VERSION "PMZ_HSCAN"

NS_ :

BS_:

BU_: BCM_Gp BECM CCF_Server EPICD EPICD_E GWM HVAC PCM SGCM TSTR Virtual_Node

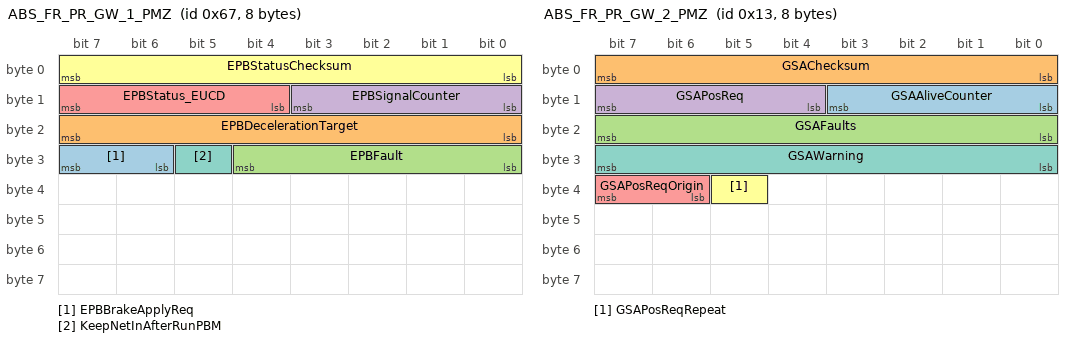
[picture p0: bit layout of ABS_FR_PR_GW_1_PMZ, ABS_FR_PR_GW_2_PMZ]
BO_ 103 ABS_FR_PR_GW_1_PMZ: 8 GWM
 SG_ EPBBrakeApplyReq : 31|2@0+ (1,0) [0|3] "" Vector__XXX
 SG_ EPBDecelerationTarget : 23|8@0+ (0.1,-11) [-11|11] "m/s/s" Vector__XXX
 SG_ EPBFault : 28|5@0+ (1,0) [0|31] "" Vector__XXX
 SG_ EPBSignalCounter : 11|4@0+ (1,0) [0|15] "Counter value" Vector__XXX
 SG_ EPBStatus_EUCD : 15|4@0+ (1,0) [0|15] "" Vector__XXX
 SG_ EPBStatusChecksum : 7|8@0+ (1,0) [0|255] "checksum" Vector__XXX
 SG_ KeepNetInAfterRunPBM : 29|1@0+ (1,0) [0|1] "" Vector__XXX

BO_ 19 ABS_FR_PR_GW_2_PMZ: 8 GWM
 SG_ GSAAliveCounter : 11|4@0+ (1,0) [0|15] "Counter value" Vector__XXX
 SG_ GSAChecksum : 7|8@0+ (1,0) [0|255] "checksum" Vector__XXX
 SG_ GSAFaults : 23|8@0+ (1,0) [0|255] "" Vector__XXX
 SG_ GSAPosReq : 15|4@0+ (1,0) [0|15] "" Vector__XXX
 SG_ GSAPosReqOrigin : 39|2@0+ (1,0) [0|3] "" Vector__XXX
 SG_ GSAPosReqRepeat : 37|1@0+ (1,0) [0|1] "" Vector__XXX
 SG_ GSAWarning : 31|8@0+ (1,0) [0|255] "" Vector__XXX

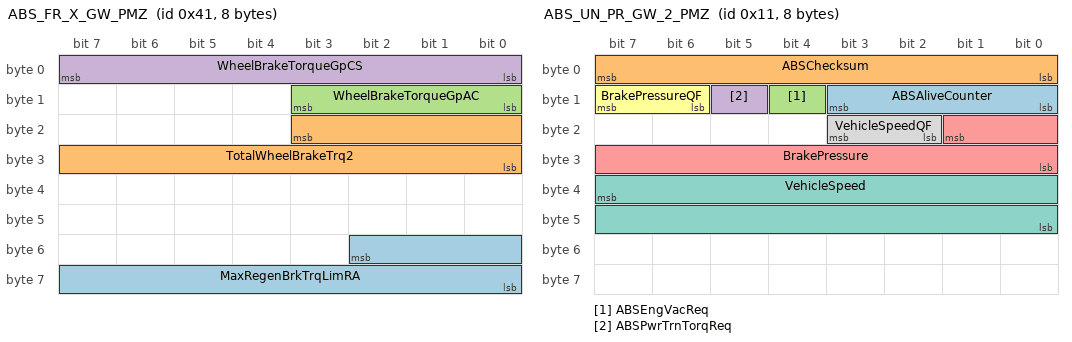
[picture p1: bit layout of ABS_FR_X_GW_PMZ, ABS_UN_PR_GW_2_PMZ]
BO_ 65 ABS_FR_X_GW_PMZ: 8 GWM
 SG_ MaxRegenBrkTrqLimRA : 50|11@0+ (10,0) [0|20470] "Nm" Vector__XXX
 SG_ TotalWheelBrakeTrq2 : 19|12@0+ (10,0) [0|40950] "Nm" Vector__XXX
 SG_ WheelBrakeTorqueGpAC : 11|4@0+ (1,0) [0|15] "Counter value" Vector__XXX
 SG_ WheelBrakeTorqueGpCS : 7|8@0+ (1,0) [0|255] "checksum" Vector__XXX

BO_ 17 ABS_UN_PR_GW_2_PMZ: 8 GWM
 SG_ ABSAliveCounter : 11|4@0+ (1,0) [0|15] "Counter value" Vector__XXX
 SG_ ABSChecksum : 7|8@0+ (1,0) [0|255] "checksum" Vector__XXX
 SG_ ABSEngVacReq : 12|1@0+ (1,0) [0|1] "" Vector__XXX
 SG_ ABSPwrTrnTorqReq : 13|1@0+ (1,0) [0|1] "" Vector__XXX
 SG_ BrakePressure : 17|10@0+ (0.2,0) [0|204.6] "Bar" Vector__XXX
 SG_ BrakePressureQF : 15|2@0+ (1,0) [0|3] "" Vector__XXX
 SG_ VehicleSpeed : 39|16@0+ (0.01,0) [0|320] "kph"  EPICD,EPICD_E
 SG_ VehicleSpeedQF : 19|2@0+ (1,0) [0|3] ""  EPICD,EPICD_E

BO_ 1537 BCM_CCP_Rx_PMZCAN: 8 GWM
 SG_ CCP_BCM_Rx : 7|64@0+ (1,0) [0|1.84467440737096E+019] ""  BCM_Gp

BO_ 1536 BCM_CCP_Tx_PMZCAN: 8 BCM_Gp
 SG_ CCP_BCM_Tx : 7|64@0+ (1,0) [0|1.84467440737096E+019] ""  GWM

BO_ 1281 BCM_NM501HS: 8 BCM_Gp
 SG_ NMmessageBCMHS : 7|64@0+ (1,0) [0|1.84467440737096E+019] ""  Virtual_Node

BO_ 417 BCM_PMZ_Core: 8 BCM_Gp
 SG_ AlarmModeHS : 42|2@0+ (1,0) [0|3] "" Vector__XXX
 SG_ AlarmModeHS_UB : 47|1@0+ (1,0) [0|1] "" Vector__XXX
 SG_ BCMReqBusAwakePT : 43|1@0+ (1,0) [0|1] ""  GWM
 SG_ CabinCleaningWakeUpReq : 27|1@0+ (1,0) [0|1] ""  HVAC
 SG_ CarModeHS : 60|4@0+ (1,0) [0|15] ""  BECM,EPICD,EPICD_E,HVAC
 SG_ CentralLockStatus : 46|3@0+ (1,0) [5|7] "Unused (Undefined)" Vector__XXX
 SG_ CentralLockStatus3 : 30|3@0+ (1,0) [5|7] "Unused (Undefined)" Vector__XXX
 SG_ CLockCmd_2 : 55|8@0+ (1,0) [0|255] "See Description for encoding" Vector__XXX
 SG_ CLockCmd_2_UB : 63|1@0+ (1,0) [0|1] "" Vector__XXX
 SG_ CLockCmd_3 : 39|8@0+ (1,0) [0|255] "See Description for encoding" Vector__XXX
 SG_ CLockCmd_3_UB : 40|1@0+ (1,0) [0|1] "" Vector__XXX
 SG_ PHEVFuelFillRequest : 62|2@0+ (1,0) [0|3] "" Vector__XXX
 SG_ PowerMode : 23|5@0+ (1,0) [0|31] ""  BECM,EPICD,EPICD_E,HVAC,SGCM
 SG_ PowerModeAliveCounter : 11|4@0+ (1,0) [0|15] "Counter value" Vector__XXX
 SG_ PowerModeChecksum : 7|8@0+ (1,0) [0|255] "checksum" Vector__XXX
 SG_ PowerModeQF : 18|2@0+ (1,0) [0|3] "" Vector__XXX
 SG_ RemoteEngStartDrivPres : 16|1@0+ (1,0) [0|1] "" Vector__XXX
 SG_ RemoteFunctionStatus : 15|4@0+ (1,0) [3|14] "Reserved" Vector__XXX
 SG_ RemoteStartStatusMS : 31|1@0+ (1,0) [0|1] "" Vector__XXX
 SG_ TimedChrgWakeUpReq : 56|1@0+ (1,0) [0|1] "" Vector__XXX

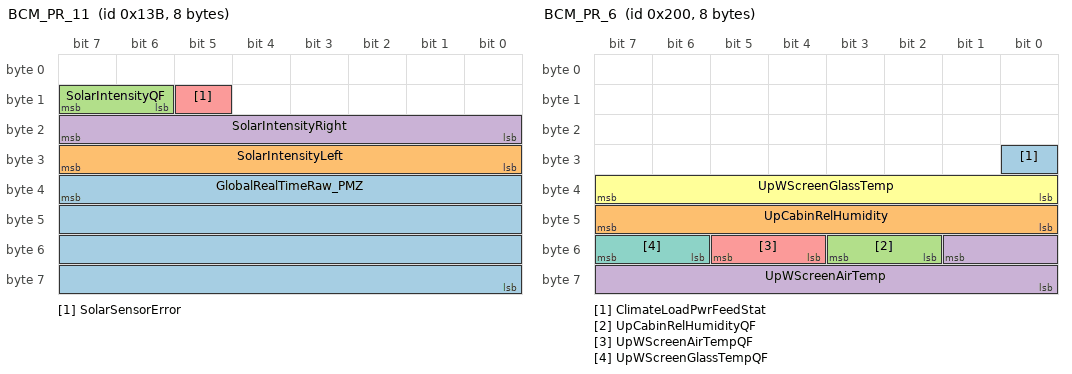
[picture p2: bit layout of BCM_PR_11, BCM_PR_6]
BO_ 315 BCM_PR_11: 8 BCM_Gp
 SG_ GlobalRealTimeRaw_PMZ : 39|32@0+ (1,0) [0|4294967295] ""  GWM,HVAC
 SG_ SolarIntensityLeft : 31|8@0+ (5,0) [0|1250] "W/m2"  GWM,HVAC
 SG_ SolarIntensityQF : 15|2@0+ (1,0) [0|3] ""  GWM,HVAC
 SG_ SolarIntensityRight : 23|8@0+ (5,0) [0|1250] "W/m2"  GWM,HVAC
 SG_ SolarSensorError : 13|1@0+ (1,0) [0|1] ""  GWM,HVAC

BO_ 512 BCM_PR_6: 8 BCM_Gp
 SG_ ClimateLoadPwrFeedStat : 24|1@0+ (1,0) [0|1] ""  HVAC
 SG_ UpCabinRelHumidity : 47|8@0+ (0.5,0) [0|127.5] "%"  HVAC
 SG_ UpCabinRelHumidityQF : 51|2@0+ (1,0) [0|3] ""  HVAC
 SG_ UpWScreenAirTemp : 49|10@0+ (0.125,-40) [-40|87.875] "DegC"  HVAC
 SG_ UpWScreenAirTempQF : 53|2@0+ (1,0) [0|3] ""  HVAC
 SG_ UpWScreenGlassTemp : 39|8@0+ (0.5,-40) [-40|87.5] "DegC"  HVAC
 SG_ UpWScreenGlassTempQF : 55|2@0+ (1,0) [0|3] ""  HVAC

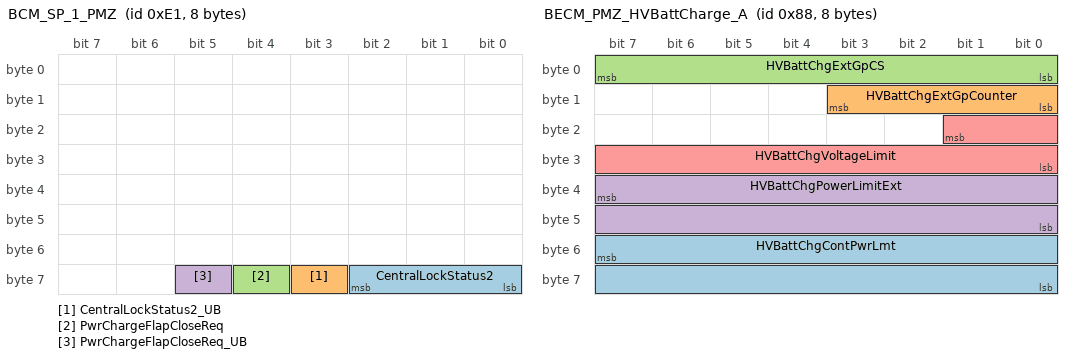
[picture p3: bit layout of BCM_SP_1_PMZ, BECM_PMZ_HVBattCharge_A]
BO_ 225 BCM_SP_1_PMZ: 8 BCM_Gp
 SG_ CentralLockStatus2 : 58|3@0+ (1,0) [5|7] "Unused (Undefined)" Vector__XXX
 SG_ CentralLockStatus2_UB : 59|1@0+ (1,0) [0|1] "" Vector__XXX
 SG_ PwrChargeFlapCloseReq : 60|1@0+ (1,0) [0|1] "" Vector__XXX
 SG_ PwrChargeFlapCloseReq_UB : 61|1@0+ (1,0) [0|1] "" Vector__XXX

BO_ 7 BCM_SP_GW_ParkLockDataControl: 8 BCM_Gp
 SG_ ParkLockDataControl : 7|64@0+ (1,0) [0|1.84467440737096E+019] ""  GWM

BO_ 1672 BCM_UUDT1_PMZCAN: 8 BCM_Gp
 SG_ UUDTBCMResponse1 : 7|64@0+ (1,0) [0|1.84467440737096E+019] ""  GWM

BO_ 1673 BCM_UUDT2_PMZCAN: 8 BCM_Gp
 SG_ UUDTBCMResponse2 : 7|64@0+ (1,0) [0|1.84467440737096E+019] ""  GWM

BO_ 1674 BCM_UUDT3_PMZCAN: 8 BCM_Gp
 SG_ UUDTBCMResponse3 : 7|64@0+ (1,0) [0|1.84467440737096E+019] ""  GWM

BO_ 1675 BCM_UUDT4_PMZCAN: 8 BCM_Gp
 SG_ UUDTBCMResponse4 : 7|64@0+ (1,0) [0|1.84467440737096E+019] ""  GWM

BO_ 1314 BECM_NM522: 8 BECM
 SG_ NMmessageBECM : 7|64@0+ (1,0) [0|1.84467440737096E+019] ""  Virtual_Node

BO_ 136 BECM_PMZ_HVBattCharge_A: 8 BECM
 SG_ HVBattChgContPwrLmt : 55|16@0+ (0.01,-655.35) [-655.35|0] "kW"  PCM
 SG_ HVBattChgExtGpCounter : 11|4@0+ (1,0) [0|15] "Counter value"  PCM
 SG_ HVBattChgExtGpCS : 7|8@0+ (1,0) [0|255] "checksum"  PCM
 SG_ HVBattChgPowerLimitExt : 39|16@0+ (0.01,-655.35) [-655.35|0] "kW"  PCM
 SG_ HVBattChgVoltageLimit : 17|10@0+ (1,0) [0|1023] "Volts"  PCM

BO_ 138 BECM_PMZ_HVBattCharge_B: 8 BECM
 SG_ HVBattChgCurrentLimit : 33|10@0+ (1,-1023) [-1023|0] "Amps"  GWM,PCM
 SG_ HVBattDerateWarning : 54|1@0+ (1,0) [0|1] ""  PCM
 SG_ HVBattTotalCapacity : 19|12@0+ (0.1,0) [0|409.5] "Kwh"  PCM

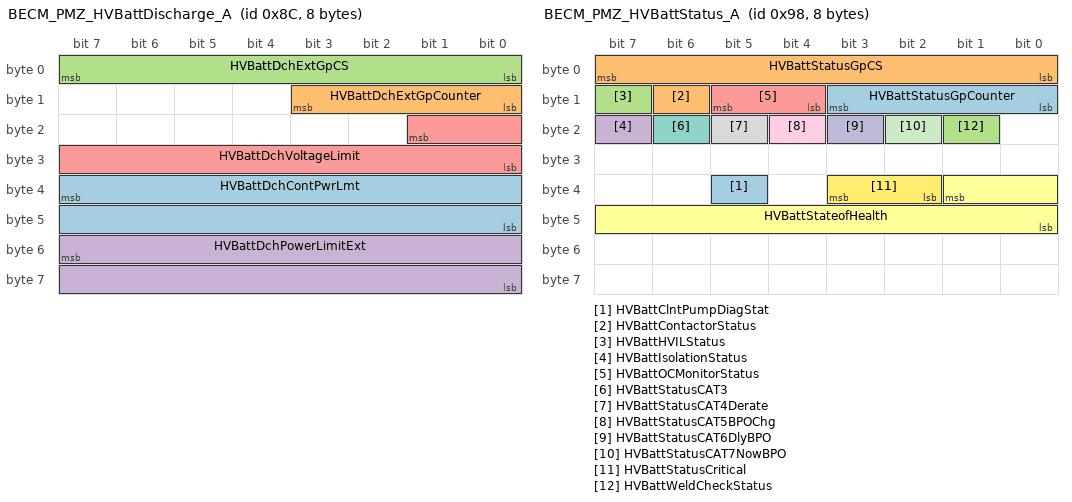
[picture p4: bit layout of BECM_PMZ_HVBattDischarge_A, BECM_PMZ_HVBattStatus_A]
BO_ 140 BECM_PMZ_HVBattDischarge_A: 8 BECM
 SG_ HVBattDchContPwrLmt : 39|16@0+ (0.01,0) [0|655.35] "kW"  PCM
 SG_ HVBattDchExtGpCounter : 11|4@0+ (1,0) [0|15] "Counter value"  PCM
 SG_ HVBattDchExtGpCS : 7|8@0+ (1,0) [0|255] "checksum"  PCM
 SG_ HVBattDchPowerLimitExt : 55|16@0+ (0.01,0) [0|655.35] "kW"  PCM
 SG_ HVBattDchVoltageLimit : 17|10@0+ (1,0) [0|1023] "Volts"  PCM

BO_ 142 BECM_PMZ_HVBattDischarge_B: 8 BECM
 SG_ HVBattDchCurrentLimit : 17|10@0+ (1,0) [0|1023] "Amps"  GWM,PCM

BO_ 144 BECM_PMZ_HVBattPower_A: 8 BECM
 SG_ HVBattMILRequest : 21|2@0+ (1,0) [0|3] ""  PCM

BO_ 519 BECM_PMZ_HVBattSOC: 8 BECM
 SG_ HVBattSOCAverage : 53|14@0+ (0.01,0) [0|100] "%"  GWM,PCM

BO_ 152 BECM_PMZ_HVBattStatus_A: 8 BECM
 SG_ HVBattClntPumpDiagStat : 37|1@0+ (1,0) [0|1] ""  HVAC
 SG_ HVBattContactorStatus : 14|1@0+ (1,0) [0|1] ""  EPICD_E,GWM,PCM
 SG_ HVBattHVILStatus : 15|1@0+ (1,0) [0|1] ""  GWM,PCM
 SG_ HVBattIsolationStatus : 23|1@0+ (1,0) [0|1] ""  PCM
 SG_ HVBattOCMonitorStatus : 13|2@0+ (1,0) [0|3] ""  GWM,PCM
 SG_ HVBattStateofHealth : 33|10@0+ (0.1,0) [0|100] "%"  GWM,PCM
 SG_ HVBattStatusCAT3 : 22|1@0+ (1,0) [0|1] ""  GWM,PCM
 SG_ HVBattStatusCAT4Derate : 21|1@0+ (1,0) [0|1] ""  GWM,PCM
 SG_ HVBattStatusCAT5BPOChg : 20|1@0+ (1,0) [0|1] ""  PCM
 SG_ HVBattStatusCAT6DlyBPO : 19|1@0+ (1,0) [0|1] ""  GWM,PCM
 SG_ HVBattStatusCAT7NowBPO : 18|1@0+ (1,0) [0|1] ""  GWM,PCM
 SG_ HVBattStatusCritical : 35|2@0+ (1,0) [0|3] ""  GWM,HVAC
 SG_ HVBattStatusGpCounter : 11|4@0+ (1,0) [0|15] "Counter value"  PCM
 SG_ HVBattStatusGpCS : 7|8@0+ (1,0) [0|255] "checksum"  PCM
 SG_ HVBattWeldCheckStatus : 17|1@0+ (1,0) [0|1] ""  PCM

BO_ 328 BECM_PMZ_HVBattTemp: 8 BECM
 SG_ HVBattCellTempAverage : 63|8@0+ (0.5,-40) [-40|87.5] "deg C"  GWM,PCM
 SG_ HVBattCellTempColdest : 55|8@0+ (0.5,-40) [-40|87.5] "deg C"  GWM,HVAC,PCM
 SG_ HVBattCellTempHottest : 47|8@0+ (0.5,-40) [-40|87.5] "deg C"  GWM,HVAC,PCM

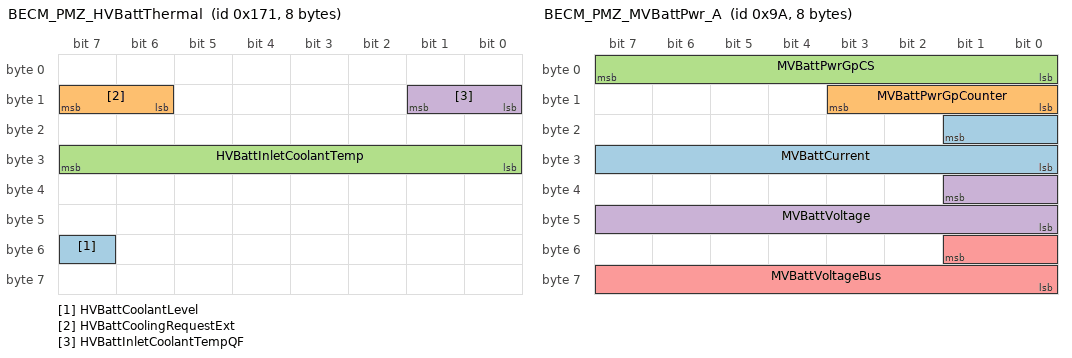
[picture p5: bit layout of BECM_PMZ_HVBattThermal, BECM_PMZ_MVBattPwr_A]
BO_ 369 BECM_PMZ_HVBattThermal: 8 BECM
 SG_ HVBattCoolantLevel : 55|1@0+ (1,0) [0|1] ""  HVAC
 SG_ HVBattCoolingRequestExt : 15|2@0+ (1,0) [0|3] ""  HVAC
 SG_ HVBattInletCoolantTemp : 31|8@0+ (0.5,-40) [-40|86.5] "DegC"  GWM,HVAC,PCM
 SG_ HVBattInletCoolantTempQF : 9|2@0+ (1,0) [0|3] ""  PCM

BO_ 332 BECM_PMZ_HVBattVoltage: 8 BECM
 SG_ HVBattCellVoltageMax : 52|13@0+ (0.001,0) [0|8.191] "Volts"  GWM
 SG_ HVBattCellVoltageMin : 36|13@0+ (0.001,0) [0|8.191] "Volts"  GWM

BO_ 334 BECM_PMZ_HVBattWakeUp: 8 BECM
 SG_ HVBattWakeUpDchReq : 54|1@0+ (1,0) [0|1] ""  BCM_Gp
 SG_ HVBattWakeUpThermalReq : 62|1@0+ (1,0) [0|1] ""  BCM_Gp
 SG_ HVBattWakeUpTopUpReq : 63|1@0+ (1,0) [0|1] ""  BCM_Gp

BO_ 744 BECM_PMZ_MVBattCal_A: 8 BECM
 SG_ MVBattCalibrationID01 : 15|56@0+ (1,0) [0|7.20575940379279E+016] ""  PCM

BO_ 745 BECM_PMZ_MVBattCal_B: 8 BECM
 SG_ MVBattCalibrationID02 : 15|56@0+ (1,0) [0|7.20575940379279E+016] ""  PCM

BO_ 746 BECM_PMZ_MVBattCal_C: 8 BECM
 SG_ MVBattCalibVerifNumber : 39|32@0+ (1,0) [0|4294967295] ""  PCM

BO_ 748 BECM_PMZ_MVBattDiag_A: 8 BECM
 SG_ MVBattDiagnostic01 : 7|64@0+ (1,0) [0|1.84467440737096E+019] ""  PCM

BO_ 749 BECM_PMZ_MVBattDiag_B: 8 BECM
 SG_ MVBattDiagnostic02 : 7|64@0+ (1,0) [0|1.84467440737096E+019] ""  PCM

BO_ 154 BECM_PMZ_MVBattPwr_A: 8 BECM
 SG_ MVBattCurrent : 17|10@0+ (1,-511) [-511|512] "Amps"  PCM
 SG_ MVBattPwrGpCounter : 11|4@0+ (1,0) [0|15] "Counter value"  PCM
 SG_ MVBattPwrGpCS : 7|8@0+ (1,0) [0|255] "checksum"  PCM
 SG_ MVBattVoltage : 33|10@0+ (0.1,0) [0|102.3] "Volts"  PCM
 SG_ MVBattVoltageBus : 49|10@0+ (0.1,0) [0|102.3] "Volts"  PCM

BO_ 249 BECM_PMZ_MVBattPwr_B: 8 BECM
 SG_ HVBattDchContCurLmt : 49|10@0+ (1,0) [0|1023] "Amps"  PCM
 SG_ MVBattTOCRModeReq : 51|2@0+ (1,0) [0|3] ""  PCM

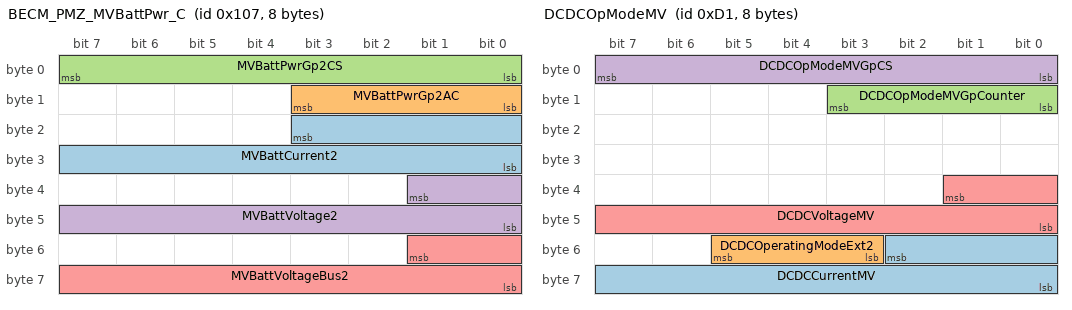
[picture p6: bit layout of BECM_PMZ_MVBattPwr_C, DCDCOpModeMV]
BO_ 263 BECM_PMZ_MVBattPwr_C: 8 BECM
 SG_ MVBattCurrent2 : 19|12@0+ (1,-2047) [-2047|2048] "Amps"  GWM,PCM
 SG_ MVBattPwrGp2AC : 11|4@0+ (1,0) [0|15] "Counter value"  GWM,PCM
 SG_ MVBattPwrGp2CS : 7|8@0+ (1,0) [0|255] "checksum"  GWM,PCM
 SG_ MVBattVoltage2 : 33|10@0+ (0.1,0) [0|102.3] "Volts"  GWM,PCM
 SG_ MVBattVoltageBus2 : 49|10@0+ (0.1,0) [0|102.3] "Volts"  GWM,PCM

BO_ 794 BMS_PR_GW_1_PMZ: 8 GWM
 SG_ BSBattSOC : 54|7@0+ (1,0) [0|100] "%" Vector__XXX
 SG_ BSBattVoltage : 63|8@0+ (0.0625,0) [0|15.9375] "V" Vector__XXX
 SG_ BSBsdEstimState : 41|2@0+ (1,0) [0|3] "" Vector__XXX

BO_ 1617 CCP_REQ_EDPM_PMZCAN: 8 GWM
 SG_ CCPTesterToEDPM : 7|64@0+ (1,0) [0|1.84467440737096E+019] "" Vector__XXX

BO_ 1604 CCP_REQ_HVAC_PMZCAN: 8 GWM
 SG_ CCPTesterToHVAC : 7|64@0+ (1,0) [0|1.84467440737096E+019] ""  HVAC

BO_ 1605 CCP_RES_HVAC_PMZCAN: 8 HVAC
 SG_ CCPHVACToTester : 7|64@0+ (1,0) [0|1.84467440737096E+019] ""  GWM

BO_ 209 DCDCOpModeMV: 8 EPICD_E
 SG_ DCDCCurrentMV : 50|11@0+ (0.1,-102.35) [-102.35|102.35] "Amps"  GWM,PCM
 SG_ DCDCOperatingModeExt2 : 53|3@0+ (1,0) [0|7] ""  GWM,PCM
 SG_ DCDCOpModeMVGpCounter : 11|4@0+ (1,0) [0|15] "Counter value"  GWM,PCM
 SG_ DCDCOpModeMVGpCS : 7|8@0+ (1,0) [0|255] "checksum"  GWM,PCM
 SG_ DCDCVoltageMV : 33|10@0+ (0.1,0) [0|102.3] "Volts"  BECM,GWM,PCM

BO_ 465 ElectricityPeakTimes1_PMZ: 8 GWM
 SG_ TimedCharge1Active : 23|1@0+ (1,0) [0|1] "" Vector__XXX
 SG_ TimedCharge1ActiveFri : 31|1@0+ (1,0) [0|1] "" Vector__XXX
 SG_ TimedCharge1ActiveMon : 39|1@0+ (1,0) [0|1] "" Vector__XXX
 SG_ TimedCharge1ActiveSat : 47|1@0+ (1,0) [0|1] "" Vector__XXX
 SG_ TimedCharge1ActiveSun : 58|1@0+ (1,0) [0|1] "" Vector__XXX
 SG_ TimedCharge1ActiveThur : 59|1@0+ (1,0) [0|1] "" Vector__XXX
 SG_ TimedCharge1ActiveTues : 60|1@0+ (1,0) [0|1] "" Vector__XXX
 SG_ TimedCharge1ActiveWed : 61|1@0+ (1,0) [0|1] "" Vector__XXX
 SG_ TimedCharge1EndTimeA : 22|7@0+ (15,0) [0|1425] "Mins" Vector__XXX
 SG_ TimedCharge1EndTimeB : 30|7@0+ (15,0) [0|1425] "Mins" Vector__XXX
 SG_ TimedCharge1EndTimeC : 38|7@0+ (15,0) [0|1425] "Mins" Vector__XXX
 SG_ TimedCharge1EndTimeD : 46|7@0+ (15,0) [0|1425] "Mins" Vector__XXX
 SG_ TimedCharge1ZoneA : 49|2@0+ (1,0) [0|3] "" Vector__XXX
 SG_ TimedCharge1ZoneB : 51|2@0+ (1,0) [0|3] "" Vector__XXX
 SG_ TimedCharge1ZoneC : 53|2@0+ (1,0) [0|3] "" Vector__XXX
 SG_ TimedCharge1ZoneD : 55|2@0+ (1,0) [0|3] "" Vector__XXX
 SG_ TimedCharge1ZoneE : 63|2@0+ (1,0) [0|3] "" Vector__XXX

BO_ 466 ElectricityPeakTimes2_PMZ: 8 GWM
 SG_ TimedCharge2Active : 23|1@0+ (1,0) [0|1] "" Vector__XXX
 SG_ TimedCharge2ActiveFri : 31|1@0+ (1,0) [0|1] "" Vector__XXX
 SG_ TimedCharge2ActiveMon : 39|1@0+ (1,0) [0|1] "" Vector__XXX
 SG_ TimedCharge2ActiveSat : 47|1@0+ (1,0) [0|1] "" Vector__XXX
 SG_ TimedCharge2ActiveSun : 61|1@0+ (1,0) [0|1] "" Vector__XXX
 SG_ TimedCharge2ActiveThur : 60|1@0+ (1,0) [0|1] "" Vector__XXX
 SG_ TimedCharge2ActiveTues : 59|1@0+ (1,0) [0|1] "" Vector__XXX
 SG_ TimedCharge2ActiveWed : 58|1@0+ (1,0) [0|1] "" Vector__XXX
 SG_ TimedCharge2EndTimeA : 22|7@0+ (15,0) [0|1425] "Mins" Vector__XXX
 SG_ TimedCharge2EndTimeB : 30|7@0+ (15,0) [0|1425] "Mins" Vector__XXX
 SG_ TimedCharge2EndTimeC : 38|7@0+ (15,0) [0|1425] "Mins" Vector__XXX
 SG_ TimedCharge2EndTimeD : 46|7@0+ (15,0) [0|1425] "Mins" Vector__XXX
 SG_ TimedCharge2ZoneA : 49|2@0+ (1,0) [0|3] "" Vector__XXX
 SG_ TimedCharge2ZoneB : 51|2@0+ (1,0) [0|3] "" Vector__XXX
 SG_ TimedCharge2ZoneC : 53|2@0+ (1,0) [0|3] "" Vector__XXX
 SG_ TimedCharge2ZoneD : 55|2@0+ (1,0) [0|3] "" Vector__XXX
 SG_ TimedCharge2ZoneE : 63|2@0+ (1,0) [0|3] "" Vector__XXX

BO_ 467 ElectricityPeakTimes3_PMZ: 8 GWM
 SG_ TimedCharge3Active : 23|1@0+ (1,0) [0|1] "" Vector__XXX
 SG_ TimedCharge3ActiveFri : 31|1@0+ (1,0) [0|1] "" Vector__XXX
 SG_ TimedCharge3ActiveMon : 39|1@0+ (1,0) [0|1] "" Vector__XXX
 SG_ TimedCharge3ActiveSat : 47|1@0+ (1,0) [0|1] "" Vector__XXX
 SG_ TimedCharge3ActiveSun : 61|1@0+ (1,0) [0|1] "" Vector__XXX
 SG_ TimedCharge3ActiveThur : 60|1@0+ (1,0) [0|1] "" Vector__XXX
 SG_ TimedCharge3ActiveTues : 59|1@0+ (1,0) [0|1] "" Vector__XXX
 SG_ TimedCharge3ActiveWed : 58|1@0+ (1,0) [0|1] "" Vector__XXX
 SG_ TimedCharge3EndTimeA : 22|7@0+ (15,0) [0|1425] "Mins" Vector__XXX
 SG_ TimedCharge3EndTimeB : 30|7@0+ (15,0) [0|1425] "Mins" Vector__XXX
 SG_ TimedCharge3EndTimeC : 38|7@0+ (15,0) [0|1425] "Mins" Vector__XXX
 SG_ TimedCharge3EndTimeD : 46|7@0+ (15,0) [0|1425] "Mins" Vector__XXX
 SG_ TimedCharge3ZoneA : 49|2@0+ (1,0) [0|3] "" Vector__XXX
 SG_ TimedCharge3ZoneB : 51|2@0+ (1,0) [0|3] "" Vector__XXX
 SG_ TimedCharge3ZoneC : 53|2@0+ (1,0) [0|3] "" Vector__XXX
 SG_ TimedCharge3ZoneD : 55|2@0+ (1,0) [0|3] "" Vector__XXX
 SG_ TimedCharge3ZoneE : 63|2@0+ (1,0) [0|3] "" Vector__XXX

BO_ 468 ElectricityPeakTimes4_PMZ: 8 GWM
 SG_ TimedCharge4Active : 23|1@0+ (1,0) [0|1] "" Vector__XXX
 SG_ TimedCharge4ActiveFri : 31|1@0+ (1,0) [0|1] "" Vector__XXX
 SG_ TimedCharge4ActiveMon : 39|1@0+ (1,0) [0|1] "" Vector__XXX
 SG_ TimedCharge4ActiveSat : 47|1@0+ (1,0) [0|1] "" Vector__XXX
 SG_ TimedCharge4ActiveSun : 61|1@0+ (1,0) [0|1] "" Vector__XXX
 SG_ TimedCharge4ActiveThur : 60|1@0+ (1,0) [0|1] "" Vector__XXX
 SG_ TimedCharge4ActiveTues : 59|1@0+ (1,0) [0|1] "" Vector__XXX
 SG_ TimedCharge4ActiveWed : 58|1@0+ (1,0) [0|1] "" Vector__XXX
 SG_ TimedCharge4EndTimeA : 22|7@0+ (15,0) [0|1425] "Mins" Vector__XXX
 SG_ TimedCharge4EndTimeB : 30|7@0+ (15,0) [0|1425] "Mins" Vector__XXX
 SG_ TimedCharge4EndTimeC : 38|7@0+ (15,0) [0|1425] "Mins" Vector__XXX
 SG_ TimedCharge4EndTimeD : 46|7@0+ (15,0) [0|1425] "Mins" Vector__XXX
 SG_ TimedCharge4ZoneA : 49|2@0+ (1,0) [0|3] "" Vector__XXX
 SG_ TimedCharge4ZoneB : 51|2@0+ (1,0) [0|3] "" Vector__XXX
 SG_ TimedCharge4ZoneC : 53|2@0+ (1,0) [0|3] "" Vector__XXX
 SG_ TimedCharge4ZoneD : 55|2@0+ (1,0) [0|3] "" Vector__XXX
 SG_ TimedCharge4ZoneE : 63|2@0+ (1,0) [0|3] "" Vector__XXX

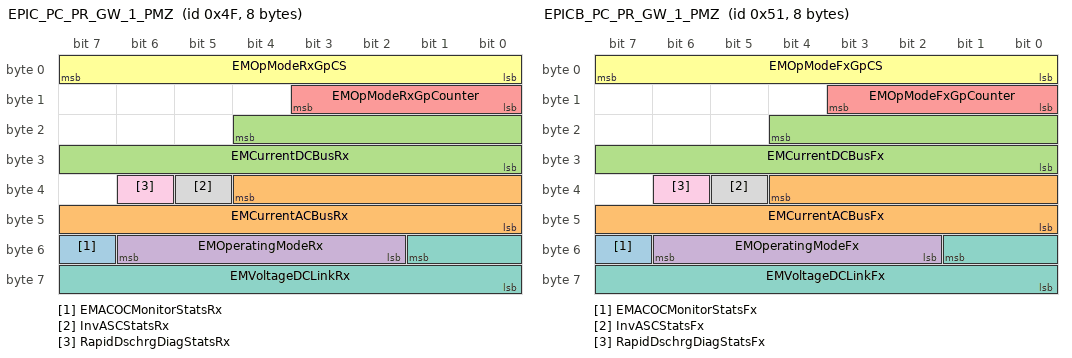
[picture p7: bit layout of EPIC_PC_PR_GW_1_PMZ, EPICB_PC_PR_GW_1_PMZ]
BO_ 79 EPIC_PC_PR_GW_1_PMZ: 8 GWM
 SG_ EMACOCMonitorStatsRx : 55|1@0+ (1,0) [0|1] "" Vector__XXX
 SG_ EMCurrentACBusRx : 36|13@0+ (0.25,-1024) [-1024|1023.75] "Amps" Vector__XXX
 SG_ EMCurrentDCBusRx : 20|13@0+ (0.25,-1024) [-1024|1023.75] "Amps" Vector__XXX
 SG_ EMOperatingModeRx : 54|5@0+ (1,0) [0|31] "" Vector__XXX
 SG_ EMOpModeRxGpCounter : 11|4@0+ (1,0) [0|15] "Counter value" Vector__XXX
 SG_ EMOpModeRxGpCS : 7|8@0+ (1,0) [0|255] "checksum" Vector__XXX
 SG_ EMVoltageDCLinkRx : 49|10@0+ (1,0) [0|1023] "Volts" Vector__XXX
 SG_ InvASCStatsRx : 37|1@0+ (1,0) [0|1] "" Vector__XXX
 SG_ RapidDschrgDiagStatsRx : 38|1@0+ (1,0) [0|1] "" Vector__XXX

BO_ 81 EPICB_PC_PR_GW_1_PMZ: 8 GWM
 SG_ EMACOCMonitorStatsFx : 55|1@0+ (1,0) [0|1] "" Vector__XXX
 SG_ EMCurrentACBusFx : 36|13@0+ (0.25,-1024) [-1024|1023.75] "Amps" Vector__XXX
 SG_ EMCurrentDCBusFx : 20|13@0+ (0.25,-1024) [-1024|1023.75] "Amps" Vector__XXX
 SG_ EMOperatingModeFx : 54|5@0+ (1,0) [0|31] "" Vector__XXX
 SG_ EMOpModeFxGpCounter : 11|4@0+ (1,0) [0|15] "Counter value" Vector__XXX
 SG_ EMOpModeFxGpCS : 7|8@0+ (1,0) [0|255] "checksum" Vector__XXX
 SG_ EMVoltageDCLinkFx : 49|10@0+ (1,0) [0|1023] "Volts" Vector__XXX
 SG_ InvASCStatsFx : 37|1@0+ (1,0) [0|1] "" Vector__XXX
 SG_ RapidDschrgDiagStatsFx : 38|1@0+ (1,0) [0|1] "" Vector__XXX

BO_ 15 EPICB_PMZ_AuthDataControl: 8 BCM_Gp
 SG_ EPICBAuthDataControl : 7|64@0+ (1,0) [0|1.84467440737096E+019] ""  GWM

BO_ 1315 EPICD_NM523: 8 EPICD
 SG_ NMmessageEPICD : 7|64@0+ (1,0) [0|1.84467440737096E+019] ""  Virtual_Node

BO_ 331 EPICD_PMZ_PR_4: 8 EPICD_E
 SG_ DCDCCurrentMVExt : 51|12@0+ (0.1,-150) [-150|259.5] "Amps"  PCM

BO_ 1630 GWA_REQ_EPIC_PMZCAN: 8 TSTR
 SG_ GWA_REQ_EPIC_PMZCAN_Pdu : 7|64@0+ (1,0) [0|0] "" Vector__XXX

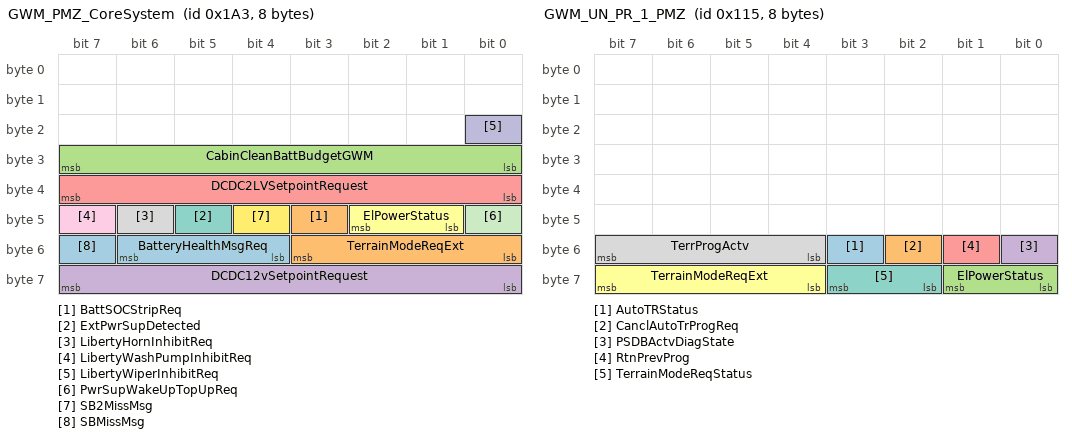
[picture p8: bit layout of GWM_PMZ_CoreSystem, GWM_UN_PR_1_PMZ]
BO_ 419 GWM_PMZ_CoreSystem: 8 GWM
 SG_ BatteryHealthMsgReq : 54|3@0+ (1,0) [0|7] "" Vector__XXX
 SG_ BattSOCStripReq : 43|1@0+ (1,0) [0|1] ""  BCM_Gp
 SG_ CabinCleanBattBudgetGWM : 31|8@0+ (0.1,0) [0|25.3] "AmpHrs"  HVAC
 SG_ DCDC12vSetpointRequest : 63|8@0+ (0.1,0) [0|25.3] "Volts"  EPICD,EPICD_E
 SG_ DCDC2LVSetpointRequest : 39|8@0+ (0.1,0) [0|25.3] "Volts" Vector__XXX
 SG_ ElPowerStatus : 42|2@0+ (1,0) [0|3] "" Vector__XXX
 SG_ ExtPwrSupDetected : 45|1@0+ (1,0) [0|1] ""  BCM_Gp
 SG_ LibertyHornInhibitReq : 46|1@0+ (1,0) [0|1] "" Vector__XXX
 SG_ LibertyWashPumpInhibitReq : 47|1@0+ (1,0) [0|1] "" Vector__XXX
 SG_ LibertyWiperInhibitReq : 16|1@0+ (1,0) [0|1] "" Vector__XXX
 SG_ PwrSupWakeUpTopUpReq : 40|1@0+ (1,0) [0|1] ""  BCM_Gp
 SG_ SB2MissMsg : 44|1@0+ (1,0) [0|1] "" Vector__XXX
 SG_ SBMissMsg : 55|1@0+ (1,0) [0|1] "" Vector__XXX
 SG_ TerrainModeReqExt : 51|4@0+ (1,0) [0|15] "" Vector__XXX

BO_ 277 GWM_UN_PR_1_PMZ: 8 GWM
 SG_ AutoTRStatus : 51|1@0+ (1,0) [0|1] "" Vector__XXX
 SG_ CanclAutoTrProgReq : 50|1@0+ (1,0) [0|1] "" Vector__XXX
 SG_ ElPowerStatus : 57|2@0+ (1,0) [0|3] "" Vector__XXX
 SG_ PSDBActvDiagState : 48|1@0+ (1,0) [0|1] "" Vector__XXX
 SG_ RtnPrevProg : 49|1@0+ (1,0) [0|1] "" Vector__XXX
 SG_ TerrainModeReqExt : 63|4@0+ (1,0) [0|15] "" Vector__XXX
 SG_ TerrainModeReqStatus : 59|2@0+ (1,0) [0|3] "" Vector__XXX
 SG_ TerrProgActv : 55|4@0+ (1,0) [0|15] "" Vector__XXX

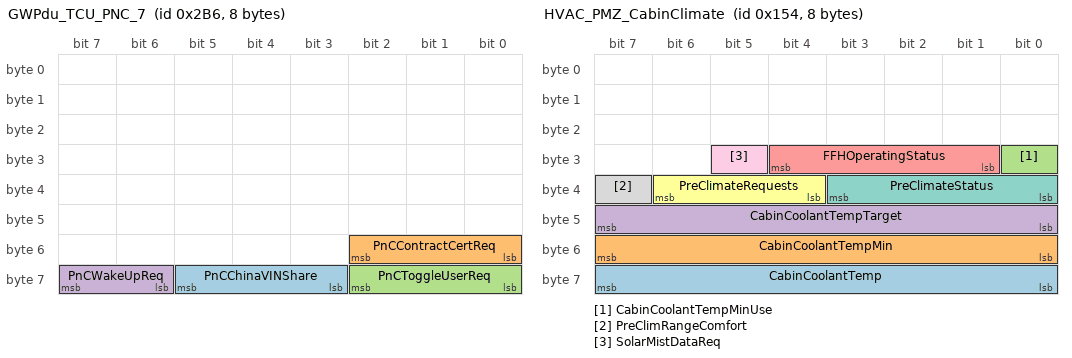
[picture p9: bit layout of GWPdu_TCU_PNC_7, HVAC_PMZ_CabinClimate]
BO_ 694 GWPdu_TCU_PNC_7: 8 GWM
 SG_ PnCChinaVINShare : 61|3@0+ (1,0) [0|7] "" Vector__XXX
 SG_ PnCContractCertReq : 50|3@0+ (1,0) [0|7] "" Vector__XXX
 SG_ PnCToggleUserReq : 58|3@0+ (1,0) [0|7] "" Vector__XXX
 SG_ PnCWakeUpReq : 63|2@0+ (1,0) [0|3] ""  BCM_Gp

BO_ 340 HVAC_PMZ_CabinClimate: 8 HVAC
 SG_ CabinCoolantTemp : 63|8@0+ (1,-60) [-60|195] "deg C" Vector__XXX
 SG_ CabinCoolantTempMin : 55|8@0+ (1,-60) [-60|195] "deg C" Vector__XXX
 SG_ CabinCoolantTempMinUse : 24|1@0+ (1,0) [0|1] "" Vector__XXX
 SG_ CabinCoolantTempTarget : 47|8@0+ (1,-60) [-60|195] "deg C" Vector__XXX
 SG_ FFHOperatingStatus : 28|4@0+ (1,0) [0|15] "" Vector__XXX
 SG_ PreClimateRequests : 38|3@0+ (1,0) [0|7] "" Vector__XXX
 SG_ PreClimateStatus : 35|4@0+ (1,0) [0|15] "" Vector__XXX
 SG_ PreClimRangeComfort : 39|1@0+ (1,0) [0|1] "" Vector__XXX
 SG_ SolarMistDataReq : 29|1@0+ (1,0) [0|1] ""  BCM_Gp

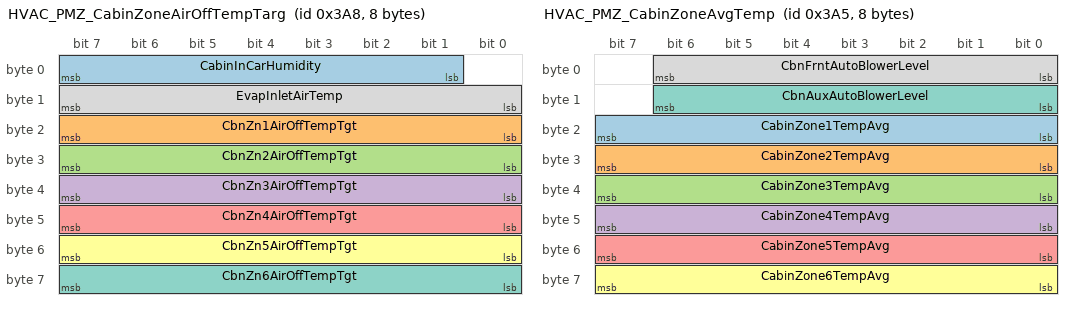
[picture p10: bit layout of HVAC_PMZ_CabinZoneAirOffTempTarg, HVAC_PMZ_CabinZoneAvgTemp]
BO_ 936 HVAC_PMZ_CabinZoneAirOffTempTarg: 8 HVAC
 SG_ CabinInCarHumidity : 7|7@0+ (1,0) [0|100] "%" Vector__XXX
 SG_ CbnZn1AirOffTempTgt : 23|8@0+ (0.5,-57) [-57|70.5] "Deg C" Vector__XXX
 SG_ CbnZn2AirOffTempTgt : 31|8@0+ (0.5,-57) [-57|70.5] "Deg C" Vector__XXX
 SG_ CbnZn3AirOffTempTgt : 39|8@0+ (0.5,-57) [-57|70.5] "Deg C" Vector__XXX
 SG_ CbnZn4AirOffTempTgt : 47|8@0+ (0.5,-57) [-57|70.5] "Deg C" Vector__XXX
 SG_ CbnZn5AirOffTempTgt : 55|8@0+ (0.5,-57) [-57|70.5] "Deg C" Vector__XXX
 SG_ CbnZn6AirOffTempTgt : 63|8@0+ (0.5,-57) [-57|70.5] "Deg C" Vector__XXX
 SG_ EvapInletAirTemp : 15|8@0+ (0.5,-57) [-57|70.5] "Deg C" Vector__XXX

BO_ 933 HVAC_PMZ_CabinZoneAvgTemp: 8 HVAC
 SG_ CabinZone1TempAvg : 23|8@0+ (0.5,-57) [-57|70.5] "Deg C" Vector__XXX
 SG_ CabinZone2TempAvg : 31|8@0+ (0.5,-57) [-57|70.5] "Deg C" Vector__XXX
 SG_ CabinZone3TempAvg : 39|8@0+ (0.5,-57) [-57|70.5] "Deg C" Vector__XXX
 SG_ CabinZone4TempAvg : 47|8@0+ (0.5,-57) [-57|70.5] "Deg C" Vector__XXX
 SG_ CabinZone5TempAvg : 55|8@0+ (0.5,-57) [-57|70.5] "Deg C" Vector__XXX
 SG_ CabinZone6TempAvg : 63|8@0+ (0.5,-57) [-57|70.5] "Deg C" Vector__XXX
 SG_ CbnAuxAutoBlowerLevel : 14|7@0+ (1,0) [0|100] "%" Vector__XXX
 SG_ CbnFrntAutoBlowerLevel : 6|7@0+ (1,0) [0|100] "%" Vector__XXX

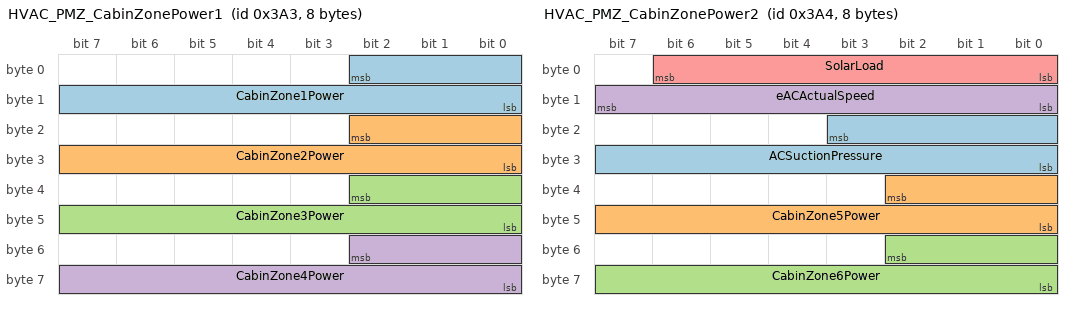
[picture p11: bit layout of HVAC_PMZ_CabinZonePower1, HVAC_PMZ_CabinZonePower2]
BO_ 931 HVAC_PMZ_CabinZonePower1: 8 HVAC
 SG_ CabinZone1Power : 2|11@0+ (10,-10000) [-10000|10000] "W" Vector__XXX
 SG_ CabinZone2Power : 18|11@0+ (10,-10000) [-10000|10000] "W" Vector__XXX
 SG_ CabinZone3Power : 34|11@0+ (10,-10000) [-10000|10000] "W" Vector__XXX
 SG_ CabinZone4Power : 50|11@0+ (10,-10000) [-10000|10000] "W" Vector__XXX

BO_ 932 HVAC_PMZ_CabinZonePower2: 8 HVAC
 SG_ ACSuctionPressure : 19|12@0+ (1,0) [0|3500] "kPa" Vector__XXX
 SG_ CabinZone5Power : 34|11@0+ (10,-10000) [-10000|10000] "W" Vector__XXX
 SG_ CabinZone6Power : 50|11@0+ (10,-10000) [-10000|10000] "W" Vector__XXX
 SG_ eACActualSpeed : 15|8@0+ (50,0) [0|12000] "RPM" Vector__XXX
 SG_ SolarLoad : 6|7@0+ (10,0) [0|1270] "W" Vector__XXX

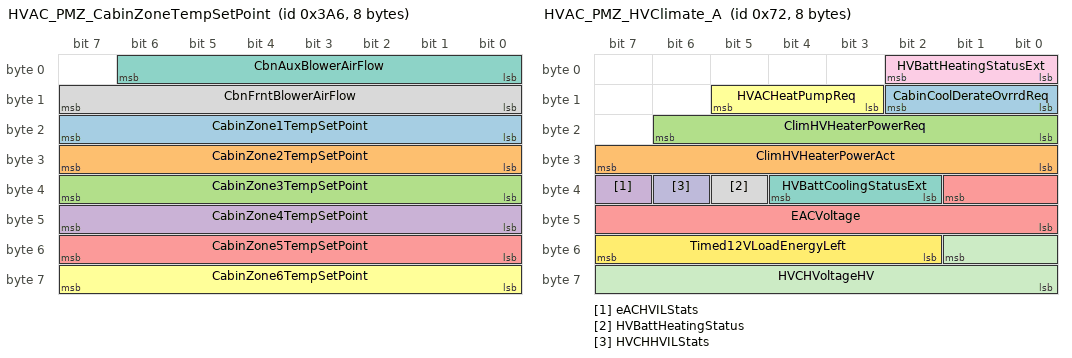
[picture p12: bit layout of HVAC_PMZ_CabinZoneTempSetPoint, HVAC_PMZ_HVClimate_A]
BO_ 934 HVAC_PMZ_CabinZoneTempSetPoint: 8 HVAC
 SG_ CabinZone1TempSetPoint : 23|8@0+ (0.5,-57) [-57|70.5] "Deg C" Vector__XXX
 SG_ CabinZone2TempSetPoint : 31|8@0+ (0.5,-57) [-57|70.5] "Deg C" Vector__XXX
 SG_ CabinZone3TempSetPoint : 39|8@0+ (0.5,-57) [-57|70.5] "Deg C" Vector__XXX
 SG_ CabinZone4TempSetPoint : 47|8@0+ (0.5,-57) [-57|70.5] "Deg C" Vector__XXX
 SG_ CabinZone5TempSetPoint : 55|8@0+ (0.5,-57) [-57|70.5] "Deg C" Vector__XXX
 SG_ CabinZone6TempSetPoint : 63|8@0+ (0.5,-57) [-57|70.5] "Deg C" Vector__XXX
 SG_ CbnAuxBlowerAirFlow : 6|7@0+ (1,0) [0|127] "L/s" Vector__XXX
 SG_ CbnFrntBlowerAirFlow : 15|8@0+ (1,0) [0|255] "L/s" Vector__XXX

BO_ 114 HVAC_PMZ_HVClimate_A: 8 HVAC
 SG_ CabinCoolDerateOvrrdReq : 10|3@0+ (1,0) [0|7] ""  GWM
 SG_ ClimHVHeaterPowerAct : 31|8@0+ (0.1,0) [0|25.5] "kW"  GWM
 SG_ ClimHVHeaterPowerReq : 22|7@0+ (0.25,0) [0|31.75] "kW"  GWM
 SG_ eACHVILStats : 39|1@0+ (1,0) [0|1] ""  GWM
 SG_ EACVoltage : 33|10@0+ (1,0) [0|1021] "Volts"  GWM
 SG_ HVACHeatPumpReq : 13|3@0+ (1,0) [0|7] ""  GWM
 SG_ HVBattCoolingStatusExt : 36|3@0+ (1,0) [0|7] ""  GWM,PCM
 SG_ HVBattHeatingStatus : 37|1@0+ (1,0) [0|1] ""  GWM
 SG_ HVBattHeatingStatusExt : 2|3@0+ (1,0) [0|7] ""  GWM
 SG_ HVCHHVILStats : 38|1@0+ (1,0) [0|1] ""  GWM
 SG_ HVCHVoltageHV : 49|10@0+ (1,0) [0|1023] "Volts"  GWM
 SG_ Timed12VLoadEnergyLeft : 55|6@0+ (0.01,0) [0|0.63] "kWh"  GWM

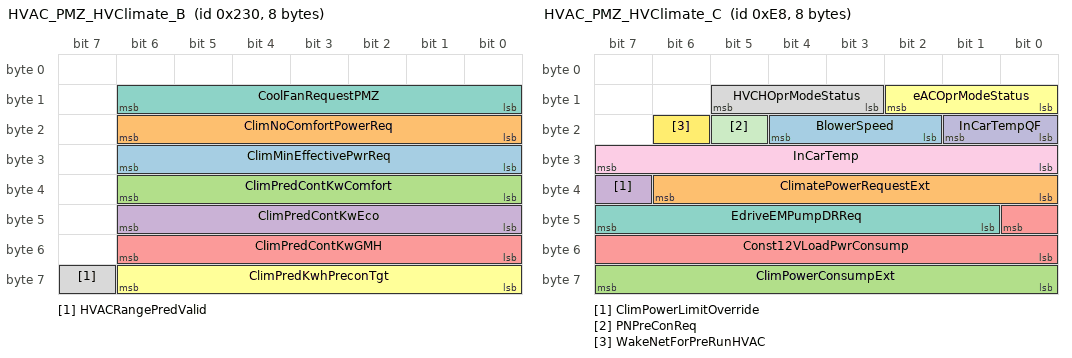
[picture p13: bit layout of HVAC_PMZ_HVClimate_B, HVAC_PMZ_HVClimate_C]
BO_ 560 HVAC_PMZ_HVClimate_B: 8 HVAC
 SG_ ClimMinEffectivePwrReq : 30|7@0+ (0.25,0) [0|31.75] "kW" Vector__XXX
 SG_ ClimNoComfortPowerReq : 22|7@0+ (0.25,0) [0|31.75] "kW" Vector__XXX
 SG_ ClimPredContKwComfort : 38|7@0+ (0.25,0) [0|31.75] "kW" Vector__XXX
 SG_ ClimPredContKwEco : 46|7@0+ (0.25,0) [0|31.75] "kW" Vector__XXX
 SG_ ClimPredContKwGMH : 54|7@0+ (0.25,0) [0|31.75] "kW" Vector__XXX
 SG_ ClimPredKwhPreconTgt : 62|7@0+ (0.1,0) [0|12.7] "kW" Vector__XXX
 SG_ CoolFanRequestPMZ : 14|7@0+ (1,0) [0|100] "Requested speed of cooling fans " Vector__XXX
 SG_ HVACRangePredValid : 63|1@0+ (1,0) [0|1] "" Vector__XXX

BO_ 232 HVAC_PMZ_HVClimate_C: 8 HVAC
 SG_ BlowerSpeed : 20|3@0+ (1,0) [0|7] ""  GWM
 SG_ ClimatePowerRequestExt : 38|7@0+ (0.25,0) [0|31.75] "kW"  GWM
 SG_ ClimPowerConsumpExt : 63|8@0+ (0.1,0) [0|25.5] "kW"  GWM
 SG_ ClimPowerLimitOverride : 39|1@0+ (1,0) [0|1] ""  GWM,Virtual_Node
 SG_ Const12VLoadPwrConsump : 40|9@0+ (0.01,0) [0|5.11] "kW"  GWM
 SG_ eACOprModeStatus : 10|3@0+ (1,0) [0|7] ""  GWM
 SG_ EdriveEMPumpDRReq : 47|7@0+ (1,0) [0|100] "%"  GWM
 SG_ HVCHOprModeStatus : 13|3@0+ (1,0) [0|7] ""  GWM
 SG_ InCarTemp : 31|8@0+ (0.5,-57) [-57|70.5] "Deg C"  GWM
 SG_ InCarTempQF : 17|2@0+ (1,0) [0|3] ""  GWM
 SG_ PNPreConReq : 21|1@0+ (1,0) [0|1] ""  GWM,Virtual_Node
 SG_ WakeNetForPreRunHVAC : 22|1@0+ (1,0) [0|1] ""  GWM

BO_ 795 HVAC_PMZ_HVClimate_D: 8 HVAC
 SG_ EWPClimatePostRunCom : 50|3@0+ (1,0) [0|7] "" Vector__XXX
 SG_ EWPClimateRPMCom : 63|8@0+ (0.3937,0) [0|99.9998] "%" Vector__XXX

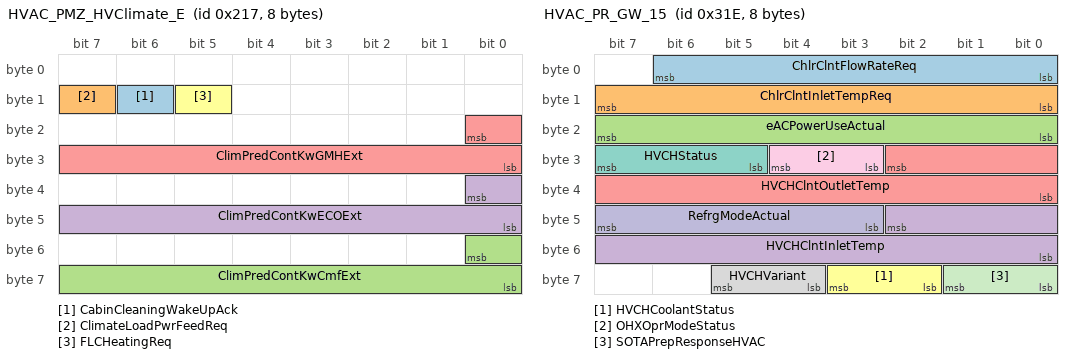
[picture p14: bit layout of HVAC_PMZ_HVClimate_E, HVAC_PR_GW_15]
BO_ 535 HVAC_PMZ_HVClimate_E: 8 HVAC
 SG_ CabinCleaningWakeUpAck : 14|1@0+ (1,0) [0|1] ""  BCM_Gp
 SG_ ClimateLoadPwrFeedReq : 15|1@0+ (1,0) [0|1] ""  BCM_Gp
 SG_ ClimPredContKwCmfExt : 48|9@0+ (0.1,0) [0|51.1] "kW" Vector__XXX
 SG_ ClimPredContKwECOExt : 32|9@0+ (0.1,0) [0|51.1] "kW" Vector__XXX
 SG_ ClimPredContKwGMHExt : 16|9@0+ (0.1,0) [0|51.1] "kW" Vector__XXX
 SG_ FLCHeatingReq : 13|1@0+ (1,0) [0|1] ""  BCM_Gp

BO_ 937 HVAC_PMZ_RefrgTemp: 8 HVAC
 SG_ CbnRecircDoorPos : 30|7@0+ (1,0) [0|100] "%" Vector__XXX
 SG_ ChlrRefrgOutletTemp : 34|11@0+ (0.1,-40) [-40|150] "Deg C" Vector__XXX
 SG_ OHXRefrgOutletTemp : 50|11@0+ (0.1,-40) [-40|150] "Deg C" Vector__XXX

BO_ 798 HVAC_PR_GW_15: 8 HVAC
 SG_ ChlrClntFlowRateReq : 6|7@0+ (1,0) [0|100] "%"  GWM
 SG_ ChlrClntInletTempReq : 15|8@0+ (1,-40) [-40|214] "degC"  GWM
 SG_ eACPowerUseActual : 23|8@0+ (0.1,0) [0|25.4] "kW"  GWM
 SG_ HVCHClntInletTemp : 42|11@0+ (0.1,-40) [-40|164.6] "DegC"  GWM
 SG_ HVCHClntOutletTemp : 26|11@0+ (0.1,-40) [-40|164.6] "DegC"  GWM
 SG_ HVCHCoolantStatus : 59|2@0+ (1,0) [0|3] ""  GWM
 SG_ HVCHStatus : 31|3@0+ (1,0) [0|7] ""  GWM
 SG_ HVCHVariant : 61|2@0+ (1,0) [0|3] ""  GWM
 SG_ OHXOprModeStatus : 28|2@0+ (1,0) [0|3] ""  GWM
 SG_ RefrgModeActual : 47|5@0+ (1,0) [0|31] ""  GWM
 SG_ SOTAPrepResponseHVAC : 57|2@0+ (1,0) [0|3] ""  GWM

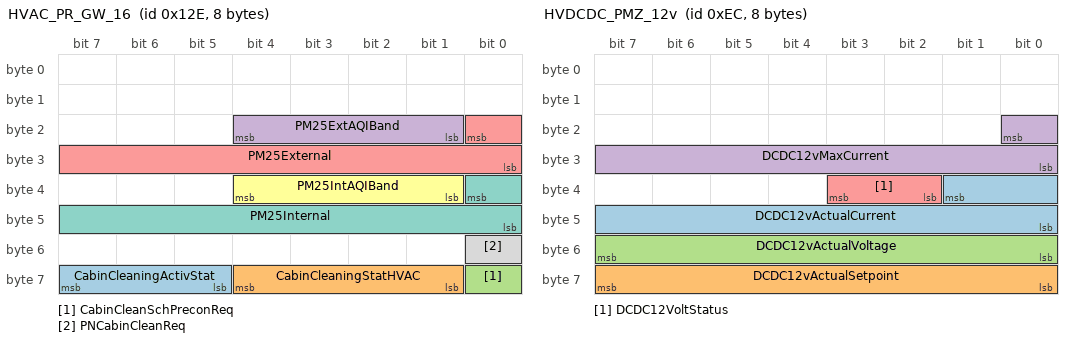
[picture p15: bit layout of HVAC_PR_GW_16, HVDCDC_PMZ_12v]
BO_ 302 HVAC_PR_GW_16: 8 HVAC
 SG_ CabinCleaningActivStat : 63|3@0+ (1,0) [0|7] ""  GWM
 SG_ CabinCleaningStatHVAC : 60|4@0+ (1,0) [0|15] ""  GWM
 SG_ CabinCleanSchPreconReq : 56|1@0+ (1,0) [0|1] ""  GWM
 SG_ PM25ExtAQIBand : 20|4@0+ (1,0) [0|15] ""  GWM
 SG_ PM25External : 16|9@0+ (1,0) [0|500] "Air Quality Index"  GWM
 SG_ PM25IntAQIBand : 36|4@0+ (1,0) [0|15] ""  GWM
 SG_ PM25Internal : 32|9@0+ (1,0) [0|500] "Air Quality Index"  GWM
 SG_ PNCabinCleanReq : 48|1@0+ (1,0) [0|1] ""  GWM

BO_ 236 HVDCDC_PMZ_12v: 8 EPICD_E
 SG_ DCDC12vActualCurrent : 33|10@0+ (1,-510) [-510|511] "Amps"  GWM
 SG_ DCDC12vActualSetpoint : 63|8@0+ (0.1,0) [0|25.3] "Volts"  GWM
 SG_ DCDC12vActualVoltage : 55|8@0+ (0.1,0) [0|25.3] "Volts"  GWM
 SG_ DCDC12vMaxCurrent : 16|9@0+ (1,-509) [-509|0] "Amps"  GWM,PCM
 SG_ DCDC12VoltStatus : 35|2@0+ (1,0) [0|3] ""  GWM,PCM

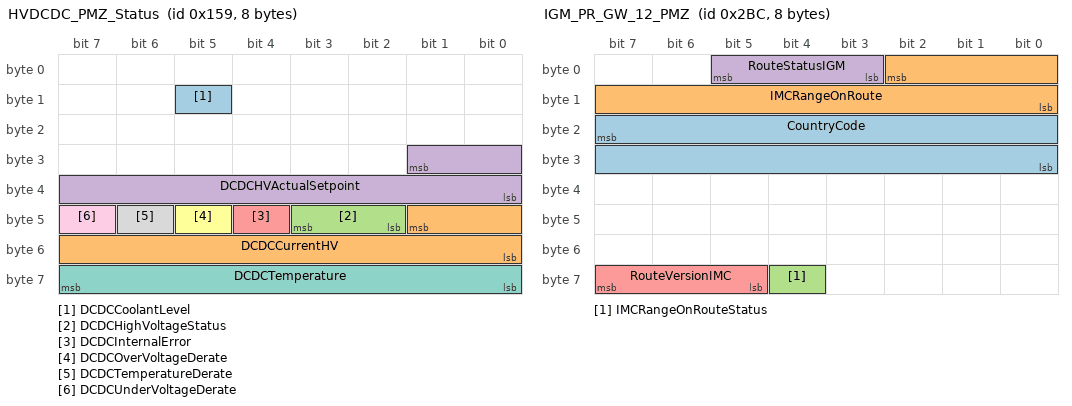
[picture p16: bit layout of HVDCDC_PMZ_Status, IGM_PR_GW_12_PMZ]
BO_ 345 HVDCDC_PMZ_Status: 8 EPICD_E
 SG_ DCDCCoolantLevel : 13|1@0+ (1,0) [0|1] ""  GWM,PCM
 SG_ DCDCCurrentHV : 41|10@0+ (0.1,-51) [-51|51.1] "Amps"  GWM,PCM
 SG_ DCDCHighVoltageStatus : 43|2@0+ (1,0) [0|3] ""  GWM,PCM
 SG_ DCDCHVActualSetpoint : 25|10@0+ (1,0) [0|1021] "Volts"  GWM,PCM
 SG_ DCDCInternalError : 44|1@0+ (1,0) [0|1] ""  GWM,PCM
 SG_ DCDCOverVoltageDerate : 45|1@0+ (1,0) [0|1] ""  GWM,PCM
 SG_ DCDCTemperature : 63|8@0+ (1,-40) [-40|213] "DegC"  GWM,PCM
 SG_ DCDCTemperatureDerate : 46|1@0+ (1,0) [0|1] ""  GWM,PCM
 SG_ DCDCUnderVoltageDerate : 47|1@0+ (1,0) [0|1] ""  GWM,PCM

BO_ 700 IGM_PR_GW_12_PMZ: 8 GWM
 SG_ CountryCode : 23|16@0+ (1,0) [0|65535] "n/a" Vector__XXX
 SG_ IMCRangeOnRoute : 2|11@0+ (1,0) [0|2047] "km" Vector__XXX
 SG_ IMCRangeOnRouteStatus : 60|1@0+ (1,0) [0|1] "" Vector__XXX
 SG_ RouteStatusIGM : 5|3@0+ (1,0) [0|7] "" Vector__XXX
 SG_ RouteVersionIMC : 63|3@0+ (1,0) [0|7] "" Vector__XXX

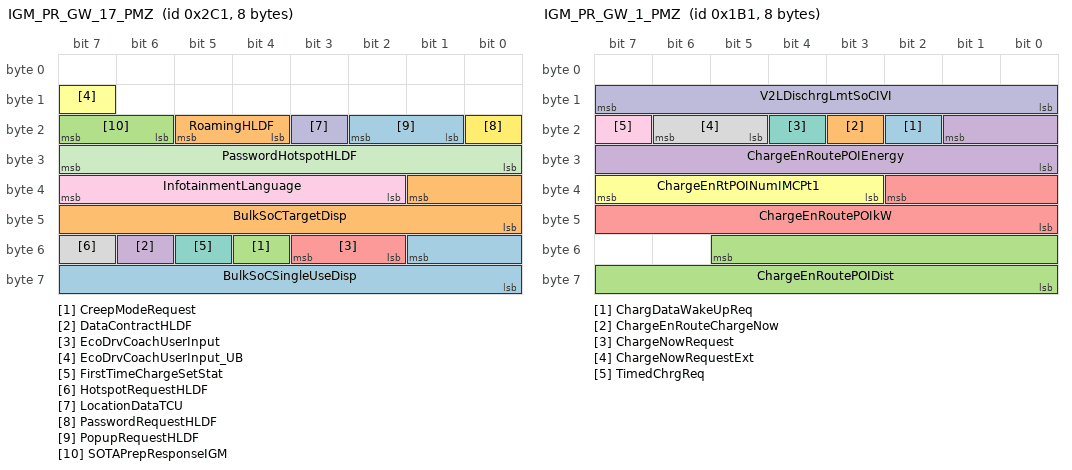
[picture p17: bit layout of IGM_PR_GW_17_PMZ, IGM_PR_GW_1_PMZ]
BO_ 705 IGM_PR_GW_17_PMZ: 8 GWM
 SG_ BulkSoCSingleUseDisp : 49|10@0+ (0.1,0) [0|102.3] "%" Vector__XXX
 SG_ BulkSoCTargetDisp : 33|10@0+ (0.1,0) [0|102.3] "%" Vector__XXX
 SG_ CreepModeRequest : 52|1@0+ (1,0) [0|1] "" Vector__XXX
 SG_ DataContractHLDF : 54|1@0+ (1,0) [0|1] "" Vector__XXX
 SG_ EcoDrvCoachUserInput : 51|2@0+ (1,0) [0|3] ""  PCM
 SG_ EcoDrvCoachUserInput_UB : 15|1@0+ (1,0) [0|1] ""  PCM
 SG_ FirstTimeChargeSetStat : 53|1@0+ (1,0) [0|1] "" Vector__XXX
 SG_ HotspotRequestHLDF : 55|1@0+ (1,0) [0|1] "" Vector__XXX
 SG_ InfotainmentLanguage : 39|6@0+ (1,0) [45|62] "Reserved" Vector__XXX
 SG_ LocationDataTCU : 19|1@0+ (1,0) [0|1] "" Vector__XXX
 SG_ PasswordHotspotHLDF : 31|8@0+ (1,0) [0|255] "DefaultPasswordValue" Vector__XXX
 SG_ PasswordRequestHLDF : 16|1@0+ (1,0) [0|1] "" Vector__XXX
 SG_ PopupRequestHLDF : 18|2@0+ (1,0) [0|3] "" Vector__XXX
 SG_ RoamingHLDF : 21|2@0+ (1,0) [0|3] "" Vector__XXX
 SG_ SOTAPrepResponseIGM : 23|2@0+ (1,0) [0|3] "" Vector__XXX

BO_ 433 IGM_PR_GW_1_PMZ: 8 GWM
 SG_ ChargDataWakeUpReq : 18|1@0+ (1,0) [0|1] ""  BCM_Gp
 SG_ ChargeEnRouteChargeNow : 19|1@0+ (1,0) [0|1] "" Vector__XXX
 SG_ ChargeEnRoutePOIDist : 53|14@0+ (0.1,0) [0|1638.3] "km" Vector__XXX
 SG_ ChargeEnRoutePOIEnergy : 17|10@0+ (0.1,0) [0|102.3] "kWh" Vector__XXX
 SG_ ChargeEnRoutePOIkW : 34|11@0+ (0.1,-42.2) [-42.2|162.5] "kW" Vector__XXX
 SG_ ChargeEnRtPOINumIMCPt1 : 39|5@0+ (1,0) [0|31] "None" Vector__XXX
 SG_ ChargeNowRequest : 20|1@0+ (1,0) [0|1] "" Vector__XXX
 SG_ ChargeNowRequestExt : 22|2@0+ (1,0) [0|3] "" Vector__XXX
 SG_ TimedChrgReq : 23|1@0+ (1,0) [0|1] "" Vector__XXX
 SG_ V2LDischrgLmtSoCIVI : 15|8@0+ (1,0) [0|100] "%" Vector__XXX

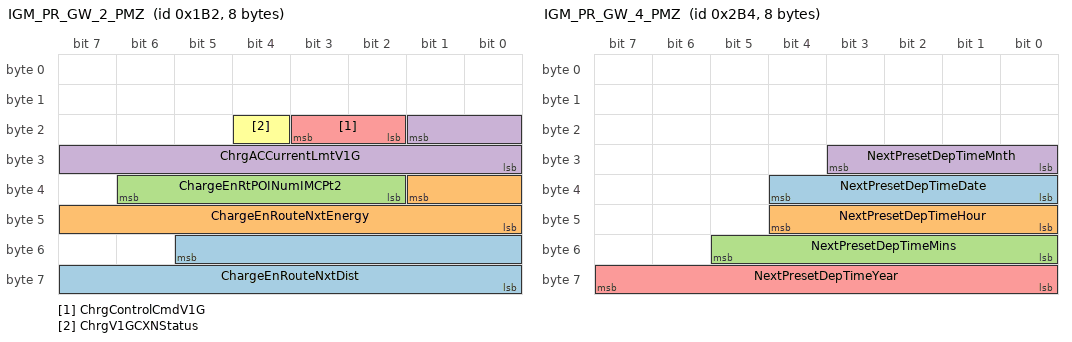
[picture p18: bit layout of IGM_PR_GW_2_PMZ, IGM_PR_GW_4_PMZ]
BO_ 434 IGM_PR_GW_2_PMZ: 8 GWM
 SG_ ChargeEnRouteNxtDist : 53|14@0+ (0.1,0) [0|1638.3] "km" Vector__XXX
 SG_ ChargeEnRouteNxtEnergy : 33|10@0+ (0.1,0) [0|102.3] "kWh" Vector__XXX
 SG_ ChargeEnRtPOINumIMCPt2 : 38|5@0+ (1,0) [0|31] "None" Vector__XXX
 SG_ ChrgACCurrentLmtV1G : 17|10@0+ (0.1,0) [0|102.3] "Amps" Vector__XXX
 SG_ ChrgControlCmdV1G : 19|2@0+ (1,0) [0|3] "" Vector__XXX
 SG_ ChrgV1GCXNStatus : 20|1@0+ (1,0) [0|1] "" Vector__XXX

BO_ 692 IGM_PR_GW_4_PMZ: 8 GWM
 SG_ NextPresetDepTimeDate : 36|5@0+ (1,1) [1|31] "" Vector__XXX
 SG_ NextPresetDepTimeHour : 44|5@0+ (1,0) [0|23] "Hour" Vector__XXX
 SG_ NextPresetDepTimeMins : 53|6@0+ (1,0) [0|59] "Mins" Vector__XXX
 SG_ NextPresetDepTimeMnth : 27|4@0+ (1,1) [1|12] "Month" Vector__XXX
 SG_ NextPresetDepTimeYear : 63|8@0+ (1,2000) [2000|2254] "" Vector__XXX

BO_ 693 IGM_PR_GW_5_PMZ: 8 GWM
 SG_ ChgPreConNowReq : 57|2@0+ (1,0) [0|3] "" Vector__XXX
 SG_ ChrgACCurrUserLimit : 41|10@0+ (0.1,0) [0|102.3] "Amps" Vector__XXX

BO_ 186 IGM_SP_GW_10_PMZ: 8 GWM
 SG_ ABRCTAMode : 47|1@0+ (1,0) [0|1] "" Vector__XXX
 SG_ ABRCTAMode_UB : 35|1@0+ (1,0) [0|1] "" Vector__XXX
 SG_ AdaptDriBeamEnableReq : 3|1@0+ (1,0) [0|1] "" Vector__XXX
 SG_ AdaptDriBeamEnableReq_UB : 4|1@0+ (1,0) [0|1] "" Vector__XXX
 SG_ AnimProjEnableReq : 39|1@0+ (1,0) [0|1] "" Vector__XXX
 SG_ AnimProjEnableReq_UB : 24|1@0+ (1,0) [0|1] "" Vector__XXX
 SG_ AnimProjPreviewReq : 26|1@0+ (1,0) [0|1] "" Vector__XXX
 SG_ AnimProjPreviewReq_UB : 25|1@0+ (1,0) [0|1] "" Vector__XXX
 SG_ AppOpenWalkAwyCloseReq : 27|1@0+ (1,0) [0|1] "" Vector__XXX
 SG_ AppOpenWalkAwyCloseReq_UB : 28|1@0+ (1,0) [0|1] "" Vector__XXX
 SG_ ApproachUnlockOnOffReq : 29|1@0+ (1,0) [0|1] "" Vector__XXX
 SG_ ApproachUnlockOnOffReq_UB : 30|1@0+ (1,0) [0|1] "" Vector__XXX
 SG_ ARAMode : 37|2@0+ (1,0) [0|3] "" Vector__XXX
 SG_ ARAMode_UB : 38|1@0+ (1,0) [0|1] "" Vector__XXX
 SG_ AutoHighBeamEnableReq : 5|1@0+ (1,0) [0|1] "" Vector__XXX
 SG_ AutoHighBeamEnableReq_UB : 6|1@0+ (1,0) [0|1] "" Vector__XXX
 SG_ AutoHighBeamSAEModeReq : 51|2@0+ (1,0) [0|3] "" Vector__XXX
 SG_ AutoHighBeamSAEModeReq_UB : 57|1@0+ (1,0) [0|1] "" Vector__XXX
 SG_ AutoHoldEnable : 52|1@0+ (1,0) [0|1] "" Vector__XXX
 SG_ AutoHoldEnable_UB : 58|1@0+ (1,0) [0|1] "" Vector__XXX
 SG_ BSMMode : 55|3@0+ (1,0) [4|7] "Reserved for future enhancements" Vector__XXX
 SG_ BSMMode_UB : 59|1@0+ (1,0) [0|1] "" Vector__XXX
 SG_ ChargingModeChcToLatch : 40|1@0+ (1,0) [0|1] "" Vector__XXX
 SG_ ChargingModeChcToLatch_UB : 60|1@0+ (1,0) [0|1] "" Vector__XXX
 SG_ CloseAllApertureReqIVI : 17|2@0+ (1,0) [0|3] "" Vector__XXX
 SG_ CloseAllApertureReqIVI_UB : 12|1@0+ (1,0) [0|1] "" Vector__XXX
 SG_ DDOpenCloseSwPressIVI : 19|2@0+ (1,0) [0|3] "" Vector__XXX
 SG_ DDOpenCloseSwPressIVI_UB : 13|1@0+ (1,0) [0|1] "" Vector__XXX
 SG_ DRDOpenCloseSwPressIVI : 21|2@0+ (1,0) [0|3] "" Vector__XXX
 SG_ DRDOpenCloseSwPressIVI_UB : 14|1@0+ (1,0) [0|1] "" Vector__XXX
 SG_ GestDrsOpnClosOnOffReq : 31|1@0+ (1,0) [0|1] "" Vector__XXX
 SG_ GestDrsOpnClosOnOffReq_UB : 15|1@0+ (1,0) [0|1] "" Vector__XXX
 SG_ IMCHybridModeRequest : 43|3@0+ (1,0) [0|7] "" Vector__XXX
 SG_ IMCHybridModeRequest_UB : 61|1@0+ (1,0) [0|1] "" Vector__XXX
 SG_ OnDemandHoldEnable : 44|1@0+ (1,0) [0|1] "" Vector__XXX
 SG_ OnDemandHoldEnable_UB : 62|1@0+ (1,0) [0|1] "" Vector__XXX
 SG_ PDOpenCloseSwPressIVI : 23|2@0+ (1,0) [0|3] "" Vector__XXX
 SG_ PDOpenCloseSwPressIVI_UB : 0|1@0+ (1,0) [0|1] "" Vector__XXX
 SG_ PEOEnablementStatus : 45|1@0+ (1,0) [0|1] "" Vector__XXX
 SG_ PEOEnablementStatus_UB : 63|1@0+ (1,0) [0|1] "" Vector__XXX
 SG_ PRDOpenCloseSwPressIVI : 9|2@0+ (1,0) [0|3] "" Vector__XXX
 SG_ PRDOpenCloseSwPressIVI_UB : 1|1@0+ (1,0) [0|1] "" Vector__XXX
 SG_ RCTAReq : 32|1@0+ (1,0) [0|1] "" Vector__XXX
 SG_ RCTAReq_UB : 49|1@0+ (1,0) [0|1] "" Vector__XXX
 SG_ RPCCustInhibitReq : 34|2@0+ (1,0) [0|3] "" Vector__XXX
 SG_ RPCCustInhibitReq_UB : 56|1@0+ (1,0) [0|1] "" Vector__XXX
 SG_ SupMainBeamEnableReq : 46|1@0+ (1,0) [0|1] "" Vector__XXX
 SG_ SupMainBeamEnableReq_UB : 48|1@0+ (1,0) [0|1] "" Vector__XXX
 SG_ WalkAwayLockOnOffReq : 11|2@0+ (1,0) [0|3] "" Vector__XXX
 SG_ WalkAwayLockOnOffReq_UB : 2|1@0+ (1,0) [0|1] "" Vector__XXX

BO_ 497 IGM_SP_GW_15_PMZ: 8 GWM
 SG_ ALAnimateReqIVI : 31|1@0+ (1,0) [0|1] "" Vector__XXX
 SG_ ALAnimateReqIVI_UB : 19|1@0+ (1,0) [0|1] "" Vector__XXX
 SG_ ALBrightnessReqIVI : 27|4@0+ (1,0) [0|15] "" Vector__XXX
 SG_ ALBrightnessReqIVI_UB : 20|1@0+ (1,0) [0|1] "" Vector__XXX
 SG_ ALCustomL1ColReqIVI : 60|5@0+ (1,0) [0|31] "" Vector__XXX
 SG_ ALCustomL1ColReqIVI_UB : 21|1@0+ (1,0) [0|1] "" Vector__XXX
 SG_ ALCustomL1IntReqIVI : 63|3@0+ (1,0) [0|7] "" Vector__XXX
 SG_ ALCustomL1IntReqIVI_UB : 22|1@0+ (1,0) [0|1] "" Vector__XXX
 SG_ ALCustomL2ColReqIVI : 52|5@0+ (1,0) [0|31] "" Vector__XXX
 SG_ ALCustomL2ColReqIVI_UB : 23|1@0+ (1,0) [0|1] "" Vector__XXX
 SG_ ALCustomL2IntReqIVI : 55|3@0+ (1,0) [0|7] "" Vector__XXX
 SG_ ALCustomL2IntReqIVI_UB : 8|1@0+ (1,0) [0|1] "" Vector__XXX
 SG_ ALCustomL3ColReqIVI : 44|5@0+ (1,0) [0|31] "" Vector__XXX
 SG_ ALCustomL3ColReqIVI_UB : 9|1@0+ (1,0) [0|1] "" Vector__XXX
 SG_ ALCustomL3IntReqIVI : 47|3@0+ (1,0) [0|7] "" Vector__XXX
 SG_ ALCustomL3IntReqIVI_UB : 10|1@0+ (1,0) [0|1] "" Vector__XXX
 SG_ ALCustomL4ColReqIVI : 36|5@0+ (1,0) [0|31] "" Vector__XXX
 SG_ ALCustomL4ColReqIVI_UB : 11|1@0+ (1,0) [0|1] "" Vector__XXX
 SG_ ALCustomL4IntReqIVI : 39|3@0+ (1,0) [0|7] "" Vector__XXX
 SG_ ALCustomL4IntReqIVI_UB : 12|1@0+ (1,0) [0|1] "" Vector__XXX
 SG_ ALDriverModeReqIVI : 18|1@0+ (1,0) [0|1] "" Vector__XXX
 SG_ ALDriverModeReqIVI_UB : 13|1@0+ (1,0) [0|1] "" Vector__XXX
 SG_ ALOnOffReqIVI : 17|2@0+ (1,0) [0|3] "" Vector__XXX
 SG_ ALOnOffReqIVI_UB : 14|1@0+ (1,0) [0|1] "" Vector__XXX
 SG_ ALPresetReqIVI : 30|3@0+ (1,0) [0|7] "" Vector__XXX
 SG_ ALPresetReqIVI_UB : 15|1@0+ (1,0) [0|1] "" Vector__XXX
 SG_ PEODestPredictConfidnc : 6|7@0+ (1,0) [0|100] "" Vector__XXX
 SG_ PEODestPredictConfidnc_UB : 7|1@0+ (1,0) [0|1] "" Vector__XXX

BO_ 44 INVA_EC_PR_GW_1_PMZ: 8 GWM
 SG_ DrvlineDampStatusFx : 60|3@0+ (1,0) [0|7] "" Vector__XXX
 SG_ InverterHVILStatusFx : 57|2@0+ (1,0) [0|3] "" Vector__XXX

BO_ 24 INVB_EC_PR_GW_1_PMZ: 8 GWM
 SG_ DrvlineDampStatusRx : 60|3@0+ (1,0) [0|7] "" Vector__XXX
 SG_ InverterHVILStatusRx : 57|2@0+ (1,0) [0|3] "" Vector__XXX

BO_ 117 Inverter_PMZ_AuthDataControl: 8 BCM_Gp
 SG_ EPICAuthDataControl : 7|64@0+ (1,0) [0|1.84467440737096E+019] ""  GWM,SGCM

BO_ 135 Inverter_PMZ_AuthDataTarget: 8 SGCM
 SG_ EPICAuthDataTarget : 7|64@0+ (1,0) [0|1.84467440737096E+019] ""  BCM_Gp

BO_ 164 Inverter_PMZ_InverterHV: 8 SGCM
 SG_ EMCurrentDcLink : 35|12@0+ (0.25,-511.5) [-511.5|511.75] "Amps"  GWM,PCM

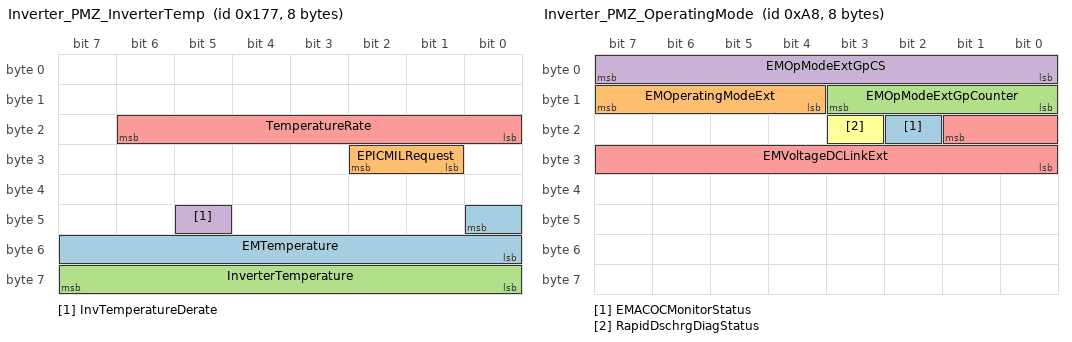
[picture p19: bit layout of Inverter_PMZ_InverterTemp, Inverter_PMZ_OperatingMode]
BO_ 375 Inverter_PMZ_InverterTemp: 8 SGCM
 SG_ EMTemperature : 40|9@0+ (1,-40) [-40|469] "degC"  GWM,PCM
 SG_ EPICMILRequest : 26|2@0+ (1,0) [0|3] ""  GWM,PCM
 SG_ InverterTemperature : 63|8@0+ (1,-40) [-40|213] "DegC"  GWM,PCM
 SG_ InvTemperatureDerate : 45|1@0+ (1,0) [0|1] ""  GWM,Virtual_Node
 SG_ TemperatureRate : 22|7@0+ (1,0) [0|120] "%"  GWM,PCM

BO_ 168 Inverter_PMZ_OperatingMode: 8 SGCM
 SG_ EMACOCMonitorStatus : 18|1@0+ (1,0) [0|1] ""  GWM,PCM
 SG_ EMOperatingModeExt : 15|4@0+ (1,0) [0|15] ""  GWM,PCM
 SG_ EMOpModeExtGpCounter : 11|4@0+ (1,0) [0|15] "Counter value"  GWM,PCM
 SG_ EMOpModeExtGpCS : 7|8@0+ (1,0) [0|255] "checksum"  GWM,PCM
 SG_ EMVoltageDCLinkExt : 17|10@0+ (1,0) [0|1023] "Volts"  GWM,PCM
 SG_ RapidDschrgDiagStatus : 19|1@0+ (1,0) [0|1] ""  GWM,PCM

CM_ BU_ BCM_Gp "Body Control Module, Lear BCM Without TPMS and with HCM, Atlas 3R2

Node type - Type 3, OSEK, Local / Network wake-up 

This variant has 12 LIN bues";
CM_ BU_ BECM "Battery Energy Control Module - EVA2 MHEV";
CM_ BU_ EPICD "EPICD: DCDC Converter MHEV - EVA2";
CM_ BU_ EPICD_E "EPICD: DCDC Converter MHEV - EVA2";
CM_ BU_ GWM "XCL Gateway Module for EVA2, NCR17Q4 / Feature Bundle 3 onwards
";
CM_ BU_ HVAC "Heating Ventilation & Air Conditioning with High Speed Comfort CAN Interfaces";
CM_ BU_ PCM "PCM for Diesel MHEV Engines (PCM_N2)";
CM_ BU_ SGCM "Starter / Generator Control Module.

MHEV 48V BISG";
CM_ BU_ TSTR "Offboard Tester with High Speed Comfort CAN Interface - TSTR_HS";
CM_ SG_ 103 EPBBrakeApplyReq "This is the request from the EPB system for the SCS to apply the main vehicle brakes.
This is to prevent excessive wear of the EPB linings.
";
CM_ SG_ 103 EPBDecelerationTarget "This is the Electric Park Brake target deceleration value.";
CM_ SG_ 103 EPBFault "Indicates if there is a fault with the Electric Park Brake.";
CM_ SG_ 103 EPBSignalCounter "This counter forms part of a safety-related signal group.
It is incremented by the task which generates the data set used in the CRC calculation, and may be used to determine the health of the data generation task.
Refer to STJLR 18.036 for more detail.";
CM_ SG_ 103 EPBStatus_EUCD "To inform the BCM (brake control) about Rear caliper ststus and if EPB system is active or inactive

For details see SRD 31815888 or ECU SWRS
";
CM_ SG_ 103 EPBStatusChecksum "This CRC shall be calculated in compliance with STJLR 18.036 Version 5.
The Data Segment Polynomial shall be constructed from the details
in the network configuration file.";
CM_ SG_ 103 KeepNetInAfterRunPBM "CAN signal stating if the network is required for After-Run.

Description of bit field detailing each application function to be stored in the DID (After-Run Function 1- 16):
Bit 0: Brake Temperature
Bit 1-15: Unused";
CM_ SG_ 19 GSAAliveCounter "This counter forms part of a safety-related signal group.
It is incremented by the task which generates the data set used in the CRC calculation, and may be used to determine the health of the data generation task.
Refer to STJLR 18.036 for more detail.";
CM_ SG_ 19 GSAChecksum "This CRC shall be calculated in compliance with STJLR 18.036 Version 5.
The Data Segment Polynomial shall be constructed from the details in the network configuration file.";
CM_ SG_ 19 GSAFaults "Display GSM Faults
xxxx xxx1 Single Bit Position Sensor Fault
xxxx xx1x Multiple Bit Position Sensor Fault
xxxx x1xx Park Button Stuck
xxxx 1xxx Position Display Fault
xxx1 xxxx Unlock Button Stuck
xx1x xxxx Buttons Electrical Fault
x1xx xxxx Lever Lock/Flipback Fault
1xxx xxxx Ignition Status";
CM_ SG_ 19 GSAPosReq "Final arbitrated gear position as arbitrated by GSA.";
CM_ SG_ 19 GSAPosReqOrigin "Describes how the Transmission Range Request (P,R,N,D,S) transmitted on the signal GSAPosReq was generated";
CM_ SG_ 19 GSAPosReqRepeat "To send repeat request to engage gear requested by GSAPosReq";
CM_ SG_ 19 GSAWarning "Alerts Request Signal originating in GSM. Passed through and modified slightly by GSA to become GSAWarning.

More then one bit to can be set in the signal. This is to request multiple
messages.
xxxx xxx1 = Gearbox Fault
xxxx xx1x = User error1
xxxx x1xx = User error2
xxxx 1xxx = User error3
xxx1 xxxx = Lock failure
xx1x xxxx = Tip not available
x1xx xxxx = GSM Fault 1
1xxx xxxx = GSM Fault 2";
CM_ SG_ 65 MaxRegenBrkTrqLimRA "Rear axle regen torque limit request signal for BEVs. Enables the regen capacity of the rear axle to be capped.";
CM_ SG_ 65 TotalWheelBrakeTrq2 "Total brake request (driver + system + regen braking) referenced at the wheels. Excludes the effects of individual wheel brake modulation e.g. due to stability events.";
CM_ SG_ 65 WheelBrakeTorqueGpAC "This counter forms part of a safety-related signal group.

It is incremented by the task which generates the data set used in the CRC calculation, and may be used to determine the health of the data generation task.

Refer to STJLR 18.036 for more detail.";
CM_ SG_ 65 WheelBrakeTorqueGpCS "This CRC shall be calculated in compliance with STJLR 18.036 Version 6.

The Data Segment Polynomial shall be constructed from the details in the network configuration file.";
CM_ SG_ 17 ABSAliveCounter "This counter forms part of a safety-related signal group.
It is incremented by the task which generates the data set used in the CRC calculation, and may be used to determine the health of the data generation task.
Refer to STJLR 18.036 for more detail.";
CM_ SG_ 17 ABSChecksum "This CRC shall be calculated in compliance with STJLR 18.036 Version 5.
The Data Segment Polynomial shall be constructed from the details
in the network configuration file.";
CM_ SG_ 17 ABSEngVacReq "1 bit signal used to indicate that ABS is unable to generate any/ sufficient brake vacuum using the electric vacuum pump, and that the engine will need to generate brake vacuum itself.";
CM_ SG_ 17 ABSPwrTrnTorqReq "This is a renaming action for ABSReqEngRunning to give clarity of the intent of this signal.
It does not mean that the internal combustion engine must be running, rather it means that the powertrain torque must be available to the driver. This may be achieved by the internal combustion engine, or an e-machine, and the transmission";
CM_ SG_ 17 BrakePressure "Non Hybrid: The signal informs about the pressure in the master cylinder.
Hybrid: Indicates the pressure that would be present at the master cylinder for the same total
brake torque delivered by the HEV braking system compared to a conventional braking system.

Note: The signal saturates at 204.6 bar. The actual brake pressure can exceed 204.6 bar.";
CM_ SG_ 17 BrakePressureQF "Quality factor for the signal BrakePressure.
";
CM_ SG_ 17 VehicleSpeed "Use in conjunction with VehicleSpeedQF. A value of 65535d may also be set under error conditions.
 
Rear Wheel Drive and AWD Vehicles: VehicleSpeed is calculated as the average speed of the two driven rear wheels. If one wheel speed sensor fails, VehicleSpeed will use the speed information from the other sensor.  

Four Wheel Drive Vehicles: VehicleSpeed is calculated as the average speed of all four wheels. In the case of wheel speed sensor failures, VehicleSpeed will use the speed information from the remaining sensors.

Front Wheel Drive and AWD Vehicles: VehicleSpeed is calculated as the average speed of the two driven front wheels. If one wheel speed sensor fails, VehicleSpeed will use the speed information from the other sensor.

Rolling circumference values used in vehicle speed calculation differ per carline.
If you are interested in knowing the rolling circumference values, please contact the ABS team- Tim Reynolds (treyno13)
";
CM_ SG_ 17 VehicleSpeedQF "Quality factor for the signal VehicleSpeed. EuCD compliant signal.";
CM_ SG_ 1281 NMmessageBCMHS "This is the Network Management Protocol Data Unit (NMPDU) for the BCM on HS_CAN.

Description of station manager bit field detailing each application function (station manager function 1-16)
Bit 0 - Power Mode Management
Bit 1 - Start Warnings
Bit 2 - Courtesy Lights
Bit 3 - Alarm and Security
Bit 4 - Passive key scan requests
Bit 5 - Personalisation
Bit 6 - Doors and Windows
Bit 7 - Start Authorisation and ESCL
Bit 8 - Lighting
Bit 9 - Electric Park Brake
Bit 10 - Steering Column Control
Bit 11 - HeVAC
Bit 12 - Trip Computer Button
Bit 13 - Not Used
Bit 14 - Diagnostics
Bit 15 - Not Used

The MSB of the signal must be written to the COM layer first (with an offset of zero in wr_bytes() ) and therefore transmitted on the bus first.
Similarly, subscribing modules will receive the MSB of the signal when they call rd_bytes(0).

E.g. wr_bytes(0) = published_signal_MSB;

Subscribed_Signal_MSB = rd_bytes(0);

";
CM_ SG_ 417 AlarmModeHS "Vehicle Alarm Mode";
CM_ SG_ 417 CabinCleaningWakeUpReq "Signal to trigger the scheduled cabin cleaning after the Timer expired.";
CM_ SG_ 417 CarModeHS "Information about which Carmode the vehicle is in i.e. Normal, factory etc.
";
CM_ SG_ 417 CentralLockStatus "Provides status information for the central locking.";
CM_ SG_ 417 CLockCmd_2 "Central Locking command to control the latch actuators.

Bitcoded:
CentralLock                   0000 0001
CentralUnlock                0000 0010
CentralDL                       0000 0011
CentralUnlockDL           0000 0100
TrunkLock                     0000 0101
TrunkUnlock                  0000 0110
DDUnlock                      xxx1 1111
PDUnlock                      xx1x 1111
LRUnlock                      x1xx 1111
RRUnlock                      1xxx 1111
DDLock                         xxx1 0000
PDLock                         xx1x 0000
LRLock                         x1xx 0000
RRLock                         1xxx 0000
CrashUnlock                  0000 1000 ";
CM_ SG_ 417 CLockCmd_3 "Central Locking command to control the latch actuators.

Bitcoded:
CentralLock                   0000 0001
CentralUnlock                0000 0010
CentralDL                       0000 0011
CentralUnlockDL           0000 0100
TrunkLock                     0000 0101
TrunkUnlock                  0000 0110
DDUnlock                      xxx1 1111
PDUnlock                      xx1x 1111
LRUnlock                      x1xx 1111
RRUnlock                      1xxx 1111
DDLock                         xxx1 0000
PDLock                         xx1x 0000
LRLock                         x1xx 0000
RRLock                         1xxx 0000
CrashUnlock                  0000 1000 ";
CM_ SG_ 417 PHEVFuelFillRequest "This signal is used on vehicles fitted with sealed fuel systems and a fuel flap sensor i.e. PHEV
This  indicates that the fuel refill button has been pressed inside the passenger compartment.
When the button is pressed the status is latched until the PCM acknowledges and clears down the request.";
CM_ SG_ 417 PowerMode "Information of current PowerMode, reflects the current  state of the Power Mode Superviser

For L538:
The signals PowerModeHS, PowerModeHSQF & PowerModeComp are all with the group PowerModeGrpHS. This grouping is to ensure that the signals are packed within the same frame, they are not treated as a group within the BCM. ";
CM_ SG_ 417 PowerModeAliveCounter "This counter forms part of a safety-related signal group.
It is incremented by the task which generates the data set used in the CRC calculation, and may be used to determine the health of the data generation task.
Refer to STJLR 18.036 for more detail.";
CM_ SG_ 417 PowerModeChecksum "This CRC shall be calculated in compliance with STJLR 18.036 Version 5.
The Data Segment Polynomial shall be constructed from the details in the network configuration file";
CM_ SG_ 417 PowerModeQF "Quality Factor of current PowerMode, reflects the quality of the PowerMode signal


For L538:
The signals PowerModeHS, PowerModeHSQF & PowerModeComp are all with the group PowerModeGrpHS. This grouping is to ensure that the signals are packed within the same frame, they are not treated as a group within the BCM. 
";
CM_ SG_ 417 RemoteFunctionStatus "CAN Message required to provide feedback to the TCU. Signal contains engine start Allowed/Blocked status.";
CM_ SG_ 417 RemoteStartStatusMS "Indicates whether Remote Engine starting is currently requested or Not.";
CM_ SG_ 417 TimedChrgWakeUpReq "Signal is used to request the vehicle to wake-up at the appropriate time if timed charging is active.";
CM_ SG_ 315 GlobalRealTimeRaw_PMZ "The raw Global Real Time value calculated in the BCM. 
This value is used by the Vehicle Information Parameters master to populate the Global Real Time value in the  Vehicle Information Parameters signal.
All nodes except the Vehicle Information Parameters master should use the Global Real Time from the Vehicle Information Parameters signal, they must NOT subscribe to this signal.
If there is no value available on Global real time, the value shall be 0xFFFFFFFF.";
CM_ SG_ 315 SolarIntensityLeft "Solar intensity value for the left solar sensor";
CM_ SG_ 315 SolarIntensityQF "Quality factor for Solar intensity values";
CM_ SG_ 315 SolarIntensityRight "Solar intensity value for the right solar sensor";
CM_ SG_ 315 SolarSensorError "Solar sensor internal error status";
CM_ SG_ 512 ClimateLoadPwrFeedStat "Power feed status of the climate loads.";
CM_ SG_ 512 UpCabinRelHumidity "Upper Cabin Relative Humidity Sensor Form RASM";
CM_ SG_ 512 UpCabinRelHumidityQF "Upper Cabin Relative Humidity Quality Factor";
CM_ SG_ 512 UpWScreenAirTemp "Upper Cabin Air Temp Sensor RASM";
CM_ SG_ 512 UpWScreenAirTempQF "Upper Cabin Air Temp Quality Factor";
CM_ SG_ 512 UpWScreenGlassTemp "Windscreen Glass Temp Sensor From RASM";
CM_ SG_ 512 UpWScreenGlassTempQF "Windscreen Glass Temp Quality Factor";
CM_ SG_ 225 CentralLockStatus2 "Provides status information for the central locking.";
CM_ SG_ 225 PwrChargeFlapCloseReq "Request to close power charge flap based on user intended lock";
CM_ SG_ 7 ParkLockDataControl "Signal used by BCM to send 'Idle, key and challenge response' to TCM/EDPM for Start Authorisation.
";
CM_ SG_ 1672 UUDTBCMResponse1 "Unacknowledged Unsegmented Data Transfer Signal from the BCM. Used for rapid data transfer in compliance with:

Ford GGDS (Generic Global Diagnostic Specification).
ISO 14229
ISO 15765-3.

UUDTBCMResponse1 shall always be packaged into CAN Identifier 0x688.

The timing specified within GGDS for frame transfers is:
Slow: 1000ms period
Medium: 100ms period
Fast: Specified by transmitting application supplier.

NOTE: All Volcano Timing Analysis has been performed on this signal at the Medium Rate (100ms). Any attempt to transmit the Message containing this signal at a faster rate may result in unknown delays on the vehicle CAN Bus, which could potentially disrupt normal functionality. In addition, transmission rates faster than Medium cannot be guaranteed.

The MSB of the signal must be written to the COM layer first (with an offset of zero in wr_bytes() ) and therefore transmitted on the bus first.
Similarly, subscribing modules will receive the MSB of the signal when they call rd_bytes(0).

";
CM_ SG_ 1673 UUDTBCMResponse2 "Unacknowledged Unsegmented Data Transfer Signal from the BCM. Used for rapid data transfer in compliance with:

Ford GGDS (Generic Global Diagnostic Specification).
ISO 14229
ISO 15765-3.

UUDTBCMResponse2 shall always be packaged into CAN Identifier 0x689.

The timing specified within GGDS for frame transfers is:
Slow: 1000ms period
Medium: 100ms period
Fast: Specified by transmitting application supplier.

NOTE: All Volcano Timing Analysis has been performed on this signal at the Medium Rate (100ms). Any attempt to transmit the Message containing this signal at a faster rate may result in unknown delays on the vehicle CAN Bus, which could potentially disrupt normal functionality. In addition, transmission rates faster than Medium cannot be guaranteed.

The MSB of the signal must be written to the COM layer first (with an offset of zero in wr_bytes() ) and therefore transmitted on the bus first.
Similarly, subscribing modules will receive the MSB of the signal when they call rd_bytes(0).

";
CM_ SG_ 1674 UUDTBCMResponse3 "Unacknowledged Unsegmented Data Transfer Signal from the BCM. Used for rapid data transfer in compliance with:

Ford GGDS (Generic Global Diagnostic Specification).
ISO 14229
ISO 15765-3.

UUDTBCMResponse3 shall always be packaged into CAN Identifier 0x68A.

The timing specified within GGDS for frame transfers is:
Slow: 1000ms period
Medium: 100ms period
Fast: Specified by transmitting application supplier.

NOTE: All Volcano Timing Analysis has been performed on this signal at the Medium Rate (100ms). Any attempt to transmit the Message containing this signal at a faster rate may result in unknown delays on the vehicle CAN Bus, which could potentially disrupt normal functionality. In addition, transmission rates faster than Medium cannot be guaranteed.

The MSB of the signal must be written to the COM layer first (with an offset of zero in wr_bytes() ) and therefore transmitted on the bus first.
Similarly, subscribing modules will receive the MSB of the signal when they call rd_bytes(0).

";
CM_ SG_ 1675 UUDTBCMResponse4 "Unacknowledged Unsegmented Data Transfer Signal from the BCM. Used for rapid data transfer in compliance with:

Ford GGDS (Generic Global Diagnostic Specification).
ISO 14229
ISO 15765-3.

UUDTBCMResponse4 shall always be packaged into CAN Identifier 0x68B.

The timing specified within GGDS for frame transfers is:
Slow: 1000ms period
Medium: 100ms period
Fast: Specified by transmitting application supplier.

NOTE: All Volcano Timing Analysis has been performed on this signal at the Medium Rate (100ms). Any attempt to transmit the Message containing this signal at a faster rate may result in unknown delays on the vehicle CAN Bus, which could potentially disrupt normal functionality. In addition, transmission rates faster than Medium cannot be guaranteed.

The MSB of the signal must be written to the COM layer first (with an offset of zero in wr_bytes() ) and therefore transmitted on the bus first.
Similarly, subscribing modules will receive the MSB of the signal when they call rd_bytes(0).

";
CM_ SG_ 136 HVBattChgContPwrLmt "The HV battery charge power limit for the plug-in charger to honour when charging the battery.";
CM_ SG_ 136 HVBattChgExtGpCounter "This counter forms part of a safety-related signal group.
It is incremented by the task which generates the data set used in the CRC calculation, and may be used to determine the health of the data generation task.
Refer to STJLR 18.036 for more detail.";
CM_ SG_ 136 HVBattChgExtGpCS "This CRC shall be calculated in compliance with STJLR 18.036 Version 5.
The Data Segment Polynomial shall be constructed from the details in the network configuration file.";
CM_ SG_ 136 HVBattChgPowerLimitExt "Power limit at which the HV battery can be charged. Note that charging current and power are represented as negative values, and discharging current and power are represented as positive values. Therefore this signal will always be less than or equal to zero.";
CM_ SG_ 136 HVBattChgVoltageLimit "Max voltage limit during generating mode i.e during charging of the HV Battery.  ";
CM_ SG_ 138 HVBattChgCurrentLimit "Maximum current that can be transferred into the HV Battery during generating mode i.e during charging. Charging is neagtive and discharging is positive. ";
CM_ SG_ 138 HVBattDerateWarning "This signal is use to provide the VSC with prior warning that a HV battery derate is imminent.";
CM_ SG_ 138 HVBattTotalCapacity "Total battery capacity in kWh (energy content). 
Reference conditions: discharged from 100% to 0% (absolute) SOC at a rate of 1C at 25 degC. 
This value will reduce with the SOH decrease over the lifetime of the battery.
";
CM_ SG_ 140 HVBattDchContPwrLmt "The HV Battery discharge power limit for long duration discharging events.";
CM_ SG_ 140 HVBattDchExtGpCounter "This counter forms part of a safety-related signal group.
It is incremented by the task which generates the data set used in the CRC calculation, and may be used to determine the health of the data generation task.
Refer to STJLR 18.036 for more detail.";
CM_ SG_ 140 HVBattDchExtGpCS "This CRC shall be calculated in compliance with STJLR 18.036 Version 5.
The Data Segment Polynomial shall be constructed from the details in the network configuration file.";
CM_ SG_ 140 HVBattDchPowerLimitExt "Power limit at which the HV battery can be Discharged. Note that charging current and power are represented as negative values, and discharging current and power are represented as positive values. Therefore this signal will always be greater than or equal to zero.";
CM_ SG_ 140 HVBattDchVoltageLimit "Min voltage limit during motoring mode  i.e during discharging of the HV Battery
";
CM_ SG_ 142 HVBattDchCurrentLimit "'Maximum current that can be delivered by the HV Battery during motoring mode  i.e during discharging.
Charging is negative and discharging is postive'
";
CM_ SG_ 144 HVBattMILRequest "Request from HV Battery to light the MIL";
CM_ SG_ 519 HVBattSOCAverage "Average state of charge (SOC) of the traction battery, referenced in battery absolute SOC %.";
CM_ SG_ 152 HVBattClntPumpDiagStat "HV Battery coolant pump diagnostic status";
CM_ SG_ 152 HVBattContactorStatus "Status of the HV Battery Contactor.

For vehicle's with multiple HV Buses, this is the Status of the Auxiliary Bus Contactors.";
CM_ SG_ 152 HVBattHVILStatus "HV Battery Hazardous Voltage Interlock Loop Status";
CM_ SG_ 152 HVBattIsolationStatus "Status of BECM's assessment of the HV isolation measurement against the primary threshold.

This status reflects the status against a different isolation resistance compared to the
HVBattIsolationStatus2 signal. Depending on the vehicle application, both interfaces may be used
to ascertain the severity of the loss of isolation";
CM_ SG_ 152 HVBattOCMonitorStatus "The status of the HV Battery's open circuit monitor.
For a single bus system this reports the DC bus status. For a multiple bus system this reports the Auxiliary DC bus status";
CM_ SG_ 152 HVBattStateofHealth "The estimated State of Health of the HV Battery.
100% = Beginning of Life Capability
0% = No Capability Remaining";
CM_ SG_ 152 HVBattStatusCAT3 "HV Battery 'CAT 3' fault flag";
CM_ SG_ 152 HVBattStatusCAT4Derate "This signal indicates whether or not a HV battery CAT4 fault is present.
The definition of HV battery 'CAT' faults is contained in JLR standard HI-7043.";
CM_ SG_ 152 HVBattStatusCAT5BPOChg "HV Battery Category 5 error during plug-in charging. The charger contacts opens after 1 second.
";
CM_ SG_ 152 HVBattStatusCAT6DlyBPO "HV Battery Category 6 error - battery failure, battery not available. Battery contactor open after  2 to 4 seconds(approx).
";
CM_ SG_ 152 HVBattStatusCAT7NowBPO "HV Battery Cat 7 error - serious battery failure, battery not available. Battery contacts open immediately (0ms).
";
CM_ SG_ 152 HVBattStatusCritical "Indicates whether or not a thermal runaway is detected within the traction battery pack.";
CM_ SG_ 152 HVBattStatusGpCounter "This counter forms part of a safety-related signal group.
It is incremented by the task which generates the data set used in the CRC calculation, and may be used to determine the health of the data generation task.
Refer to STJLR 18.036 for more detail.";
CM_ SG_ 152 HVBattStatusGpCS "This CRC shall be calculated in compliance with STJLR 18.036 Version 5.
The Data Segment Polynomial shall be constructed from the details in the network configuration file.";
CM_ SG_ 152 HVBattWeldCheckStatus "The HV battery shall set the value of CAN signal HVBattWeldCheckStatus_HY as follows: 
a. Set the signal equal to 'weld detected' (0x1) if the positive or negative main contactor was diagnosed as welded during the most recent execution of the main contactor weld diagnostics. 
b. Set the signal equal to 'no weld detected' (0x0) if the positive and negative main contactor weld diagnostics completed successfully (i.e. no welds detected) during their most recent execution. 

Note that the behaviour described above is in addition to the 'CAT7' response of the HV battery to a detected welded contactor.";
CM_ SG_ 328 HVBattCellTempAverage "Estimation of the average cell temperature within the HV battery pack. ";
CM_ SG_ 328 HVBattCellTempColdest "Minimum cell temperature of the HV battery";
CM_ SG_ 328 HVBattCellTempHottest "Temperature of the hottest cell in the HV battery";
CM_ SG_ 369 HVBattCoolantLevel "HV Battery coolant level sensor status";
CM_ SG_ 369 HVBattCoolingRequestExt "HV Battery cooling request to be cooled by the eAC/chiller as its cooling needs exceed the LTR cooling loop capability.";
CM_ SG_ 369 HVBattInletCoolantTemp "HV Battery Inlet Coolant Temperature";
CM_ SG_ 369 HVBattInletCoolantTempQF "Quality factor for HVBattInletCoolantTemp";
CM_ SG_ 332 HVBattCellVoltageMax "Voltage of the HV battery cell with the highest voltage.";
CM_ SG_ 332 HVBattCellVoltageMin "Voltage of the HV battery cell with the lowest voltage.";
CM_ SG_ 334 HVBattWakeUpDchReq "The HV Battery can trigger a vehicle wake-up to request its State of Charge to be reduced.";
CM_ SG_ 334 HVBattWakeUpThermalReq "The HV Battery can trigger a vehicle wake-up in order to be thermally managed (ie. cooled down OR warmed up).";
CM_ SG_ 334 HVBattWakeUpTopUpReq "The HV Battery can trigger a vehicle wake-up to request its State of Charge to be increased.";
CM_ SG_ 744 MVBattCalibrationID01 "Sporadic Signal  - Calibration Identification for the software installed on the ECU. Format is 16 character 128 bit ASCII ($20 through $7E) Each character is 7 bits and is split over two messages. This signal comprises characters 1 to 8 of 16 characters.

128 ASCII (56 bits)
---------------------
Bit 0 to 6 = Character 1 of 16
Bit 7 to 13 = Character 2 of 16
Bit 14 to 20 = Character 3 of 16
Bit 21 to 27 = Character 4 of 16
Bit 28 to 34 = Character 5 of 16
Bit 35 to 41 = Character 6 of 16
Bit 42 to 48 = Character 7 of 16
Bit 49 to 56 = Character 8 of 16
Bit 57 to 63 = Unused";
CM_ SG_ 745 MVBattCalibrationID02 "Sporadic Signal  - Calibration Identification for the software installed on the ECU. Format is 16 character 128 bit ASCII ($20 through $7E) Each character is 7 bits  and is split over two messages. This signal comprises characters 9 to 16 of 16 characters.

128 ASCII (56 bits)
---------------------
Bit 0 to 6 = Character 9 of 16
Bit 7 to 13 = Character 10 of 16
Bit 14 to 20 = Character 11 of 16
Bit 21 to 27 = Character 12 of 16
Bit 28 to 34 = Character 13 of 16
Bit 35 to 41 = Character 14 of 16
Bit 42 to 48 = Character 15 of 16
Bit 49 to 56 = Character 16 of 16
Bit 57 to 63 = Unused";
CM_ SG_ 746 MVBattCalibVerifNumber "Sporadic Signal  - Number used to verify the integrity of the vehicle software. Consists of four Bytes values interpreted as Hexadecimal eg 0B 9F 4E D5

Hexadecimal
Bit Value  Hex Description
--------------------------------------------------------
Bit 0 to 3 (0x0 to 0xF) First Hex value (1st Byte)
Bit 4 to 7 (0x0 to 0xF) Second Hex value (1st Byte)
Bit 8 to 11 (0x0 to 0xF) Third Hex value (2nd Byte)
Bit 12 to 15 (0x0 to 0xF) Forth Hex value (2nd Byte)
Bit 16 to 19 (0x0 to 0xF) Fifth Hex value (3rd Byte)
Bit 20 to 23 (0x0 to 0xF) Sixth Hex value (3rd Byte)
Bit 24 to 27 (0x0 to 0xF) Seventh Hex value (4th Byte)
Bit 28 to 31 (0x0 to 0xF) Eighth Hex value (4th Byte)";
CM_ SG_ 748 MVBattDiagnostic01 "Bit coded Diagnostic message contained in a single CAN signal. Periodically broadcast by component to the Diagnostic Service Manager

Bit 0 = Reserved01
Bit 1 =    STACK_VOLT_CMP [P0B3C-17]  [Stack Voltage]             0 = No Fault     1 = Fault
Bit 2 =    BUS_DCDC_VOLTAGE_MISMATCH [P0E35-62]  [Stack Voltage Sense]             0 = No Fault     1 = Fault
Bit 3 =    BUS_BISG_VOLTAGE_MISMATCH [P0DA8-62]  [Stack Voltage Sense]             0 = No Fault     1 = Fault
Bit 4 =    LVBAT_LO [U3003-16]  [System Voltage]             0 = No Fault     1 = Fault
Bit 5 =    LVBAT_HI [U3003-17]  [System Voltage]             0 = No Fault     1 = Fault
Bit 6 =    SW_5V [P06A3 - 00]  [5 Volt Reference Voltage]             0 = No Fault     1 = Fault'
Bit 7 =    HW_OCP_MON [P0D34-00]  [Battery Current]             0 = No Fault     1 = Fault
Bit 8 =    BCC_CURRENT_SENSE [P0ABF-00]  [Battery Current]             0 = No Fault     1 = Fault
Bit 9 =    TEMP1_OOR_Hi [P0A9E-00]  [Battery Temperature]             0 = No Fault ";
CM_ SG_ 749 MVBattDiagnostic02 "Bit coded Diagnostic message contained in a single CAN signal. Periodically broadcast by component to the Diagnostic Service Manager

Bit 0 = Reserved01
Bit 1 =    CELL_OPEN_SENSE1  [P3007-1C]  [Voltage Measurement]             0 = No Fault     1 = Fault
Bit 2 =    CELL_OPEN_SENSE2 [P3008-1C]  [Voltage Measurement]             0 = No Fault     1 = Fault
Bit 3 =    CELL_OPEN_SENSE3 [P3009-1C]  [Voltage Measurement]             0 = No Fault     1 = Fault
Bit 4 =    CELL_OPEN_SENSE4 [P300A-1C]  [Voltage Measurement]             0 = No Fault     1 = Fault
Bit 5 =    CELL_OPEN_SENSE5 [P300B-1C]  [Voltage Measurement]             0 = No Fault     1 = Fault
Bit 6 =    CELL_OPEN_SENSE6 [P300C-1C]  [Voltage Measurement]             0 = No Fault     1 = Fault
Bit 7 =    CELL_OPEN_SENSE7 [P300D-1C]  [Voltage Measurement]             0 = No Fault     1 = Fault
Bit 8 =    CELL_OPEN_SENSE8 [P300E-1C]  [Voltage Measurement]             0 = No Fault     1 = Fault
Bit 9 =    CELL_OPEN_SENSE9 [P300F-1C]  [Voltage M";
CM_ SG_ 154 MVBattCurrent "Positive - Current taken from the battery (Motoring Mode)
Negative - Current going to the battery (Generating Mode)";
CM_ SG_ 154 MVBattPwrGpCounter "This counter forms part of a safety-related signal group.
It is incremented by the task which generates the data set used in the CRC calculation, and may be used to determine the health of the data generation task.
Refer to STJLR 18.036 for more detail.";
CM_ SG_ 154 MVBattPwrGpCS "This CRC shall be calculated in compliance with STJLR 18.036 Version 5.
The Data Segment Polynomial shall be constructed from the details in the network configuration file.";
CM_ SG_ 154 MVBattVoltage "Voltage of the MHEV battery";
CM_ SG_ 154 MVBattVoltageBus "The voltage on the MHEV DC bus measured
on the vehicle-side of the battery contactors
by the MHEV battery.";
CM_ SG_ 249 HVBattDchContCurLmt "The HV Battery discharge current limit for long duration discharging events.";
CM_ SG_ 249 MVBattTOCRModeReq "Request to run the Top Of Charge Reset function in order to maintain an accurate SOC estimation.";
CM_ SG_ 263 MVBattCurrent2 "Positive - Current taken from the battery (Motoring Mode)
Negative - Current going to the battery (Generating Mode)";
CM_ SG_ 263 MVBattPwrGp2AC "This counter forms part of a safety-related signal group.
It is incremented by the task which generates the data set used in the CRC calculation, and may be used to determine the health of the data generation task.
Refer to STJLR 18.036 for more detail.";
CM_ SG_ 263 MVBattPwrGp2CS "This CRC shall be calculated in compliance with STJLR 18.036 Version 5.
The Data Segment Polynomial shall be constructed from the details in the network configuration file.";
CM_ SG_ 263 MVBattVoltage2 "Voltage of the MHEV battery";
CM_ SG_ 263 MVBattVoltageBus2 "The voltage on the MHEV DC bus measured
on the vehicle-side of the battery contactors
by the MHEV battery.";
CM_ SG_ 794 BSBattSOC "Battery State of charge  (referenced to estimated Capacity not including sulphation losses) at normalised temperature";
CM_ SG_ 794 BSBattVoltage "Battery voltage measured with battery sensor";
CM_ SG_ 794 BSBsdEstimState " Confidence of esimated battery parameters";
CM_ SG_ 1617 CCPTesterToEDPM "The MSB of the signal must be written to the COM layer first (with an offset of zero in wr_bytes() ) and therefore transmitted on the bus first., Similarly, subscribing modules will receive the MSB of the signal when they call rd_bytes(0)., , E.g. wr_bytes(0) = published_signal_MSB;, , Subscribed_Signal_MSB = rd_bytes(0);";
CM_ SG_ 1604 CCPTesterToHVAC "

The MSB of the signal must be written to the COM layer first (with an offset of zero in wr_bytes() ) and therefore transmitted on the bus first.
Similarly, subscribing modules will receive the MSB of the signal when they call rd_bytes(0).

E.g. wr_bytes(0) = published_signal_MSB;

Subscribed_Signal_MSB = rd_bytes(0);

CAN ID = 0x644";
CM_ SG_ 1605 CCPHVACToTester "The MSB of the signal must be written to the COM layer first (with an offset of zero in wr_bytes() ) and therefore transmitted on the bus first.
Similarly, subscribing modules will receive the MSB of the signal when they call rd_bytes(0).

E.g. wr_bytes(0) = published_signal_MSB;

Subscribed_Signal_MSB = rd_bytes(0);

CAN ID = 0x645
";
CM_ SG_ 209 DCDCCurrentMV "DCDC Current on the HV Bus.

Positive - Power transfer from HV to 12v side (Buck Mode).

Negative - Power transfer from 12v to HV side (Boost Mode).
";
CM_ SG_ 209 DCDCOperatingModeExt2 "Operating Mode of the DCDC Converter
";
CM_ SG_ 209 DCDCOpModeMVGpCounter "This counter forms part of a safety-related signal group.
It is incremented by the task which generates the data set used in the CRC calculation, and may be used to determine the health of the data generation task.
Refer to STJLR 18.036 for more detail.";
CM_ SG_ 209 DCDCOpModeMVGpCS "This CRC shall be calculated in compliance with STJLR 18.036 Version 5.
The Data Segment Polynomial shall be constructed from the details
in the network configuration file.";
CM_ SG_ 209 DCDCVoltageMV "48V DC Bus voltage measured at the DCDC Converter";
CM_ SG_ 465 TimedCharge1Active "Indicates whether the first timed charging option is active or not.";
CM_ SG_ 465 TimedCharge1ActiveFri "Indicates whether the first timed charging option is active for Friday or not.";
CM_ SG_ 465 TimedCharge1ActiveMon "Indicates whether the first timed charging option is active for Monday or not.";
CM_ SG_ 465 TimedCharge1ActiveSat "Indicates whether the first timed charging option is active for Saturday or not.";
CM_ SG_ 465 TimedCharge1ActiveSun "Indicates whether the first timed charging option is active for Sunday or not.";
CM_ SG_ 465 TimedCharge1ActiveThur "Indicates whether the first timed charging option is active for Thursday or not.";
CM_ SG_ 465 TimedCharge1ActiveTues "ndicates whether the first timed charging option is active for Tuesday or not.";
CM_ SG_ 465 TimedCharge1ActiveWed "Indicates whether the first timed charging option is active for Wednesday or not.";
CM_ SG_ 465 TimedCharge1EndTimeA "Indicates the end time of Zone A within the 24 hour clock.
Note: The start of Zone A is 00:00 i.e. midnight";
CM_ SG_ 465 TimedCharge1EndTimeB "Indicates the end time of Zone B within the 24 hour clock.
Note: The start of Zone B is the end time of Zone A";
CM_ SG_ 465 TimedCharge1EndTimeC "Indicates the end time of Zone C within the 24 hour clock.
Note: The start of Zone C is the end time of Zone B";
CM_ SG_ 465 TimedCharge1EndTimeD "Indicates the end time of Zone D within the 24 hour clock.
Note: The start of Zone D is the end time of Zone C";
CM_ SG_ 465 TimedCharge1ZoneA "Indicates the Electricity pricing within the specified timeframe (Zone A)";
CM_ SG_ 465 TimedCharge1ZoneB "Indicates the Electricity pricing within the specified timeframe (Zone B)";
CM_ SG_ 465 TimedCharge1ZoneC "Indicates the Electricity pricing within the specified timeframe (Zone C)";
CM_ SG_ 465 TimedCharge1ZoneD "Indicates the Electricity pricing within the specified timeframe (Zone D)";
CM_ SG_ 465 TimedCharge1ZoneE "Indicates the Electricity pricing within the specified timeframe (Zone E)";
CM_ SG_ 466 TimedCharge2Active "Indicates whether the first timed charging option is active or not.";
CM_ SG_ 466 TimedCharge2ActiveFri "Indicates whether the first timed charging option is active for Friday or not.";
CM_ SG_ 466 TimedCharge2ActiveMon "Indicates whether the first timed charging option is active for Monday or not.";
CM_ SG_ 466 TimedCharge2ActiveSat "Indicates whether the first timed charging option is active for Saturday or not.";
CM_ SG_ 466 TimedCharge2ActiveSun "Indicates whether the first timed charging option is active for Sunday or not.";
CM_ SG_ 466 TimedCharge2ActiveThur "Indicates whether the first timed charging option is active for Thursday or not.";
CM_ SG_ 466 TimedCharge2ActiveTues "Indicates whether the first timed charging option is active for Tuesday or not.";
CM_ SG_ 466 TimedCharge2ActiveWed "Indicates whether the first timed charging option is active for Wednesday or not.";
CM_ SG_ 466 TimedCharge2EndTimeA "Indicates the end time of Zone A within the 24 hour clock.
Note: The start of Zone A is 00:00 i.e. midnight";
CM_ SG_ 466 TimedCharge2EndTimeB "Indicates the end time of Zone B within the 24 hour clock.
Note: The start of Zone B is the end time of Zone A";
CM_ SG_ 466 TimedCharge2EndTimeC "Indicates the end time of Zone C within the 24 hour clock.
Note: The start of Zone C is the end time of Zone B";
CM_ SG_ 466 TimedCharge2EndTimeD "Indicates the end time of Zone D within the 24 hour clock.
Note: The start of Zone D is the end time of Zone C";
CM_ SG_ 466 TimedCharge2ZoneA "Indicates the Electricity pricing within the specified timeframe (Zone A)";
CM_ SG_ 466 TimedCharge2ZoneB "Indicates the Electricity pricing within the specified timeframe (Zone B)";
CM_ SG_ 466 TimedCharge2ZoneC "Indicates the Electricity pricing within the specified timeframe (Zone C)";
CM_ SG_ 466 TimedCharge2ZoneD "Indicates the Electricity pricing within the specified timeframe (Zone D)";
CM_ SG_ 466 TimedCharge2ZoneE "Indicates the Electricity pricing within the specified timeframe (Zone E)";
CM_ SG_ 467 TimedCharge3Active "Indicates whether the first timed charging option is active or not.";
CM_ SG_ 467 TimedCharge3ActiveFri "Indicates whether the first timed charging option is active for Friday or not.";
CM_ SG_ 467 TimedCharge3ActiveMon "Indicates whether the first timed charging option is active for Monday or not.";
CM_ SG_ 467 TimedCharge3ActiveSat "Indicates whether the first timed charging option is active for Saturday or not.";
CM_ SG_ 467 TimedCharge3ActiveSun "Indicates whether the first timed charging option is active for Sunday or not.";
CM_ SG_ 467 TimedCharge3ActiveThur "Indicates whether the first timed charging option is active for Thursday or not.";
CM_ SG_ 467 TimedCharge3ActiveTues "Indicates whether the first timed charging option is active for Tuesday or not.";
CM_ SG_ 467 TimedCharge3ActiveWed "Indicates whether the first timed charging option is active for Wednesday or not.";
CM_ SG_ 467 TimedCharge3EndTimeA "Indicates the end time of Zone A within the 24 hour clock.
Note: The start of Zone A is 00:00 i.e. midnight";
CM_ SG_ 467 TimedCharge3EndTimeB "Indicates the end time of Zone B within the 24 hour clock.
Note: The start of Zone B is the end time of Zone A";
CM_ SG_ 467 TimedCharge3EndTimeC "Indicates the end time of Zone C within the 24 hour clock.
Note: The start of Zone C is the end time of Zone B";
CM_ SG_ 467 TimedCharge3EndTimeD "Indicates the end time of Zone D within the 24 hour clock.
Note: The start of Zone D is the end time of Zone C";
CM_ SG_ 467 TimedCharge3ZoneA "Indicates the Electricity pricing within the specified timeframe (Zone A)";
CM_ SG_ 467 TimedCharge3ZoneB "Indicates the Electricity pricing within the specified timeframe (Zone B)";
CM_ SG_ 467 TimedCharge3ZoneC "Indicates the Electricity pricing within the specified timeframe (Zone C)";
CM_ SG_ 467 TimedCharge3ZoneD "Indicates the Electricity pricing within the specified timeframe (Zone D)";
CM_ SG_ 467 TimedCharge3ZoneE "Indicates the Electricity pricing within the specified timeframe (Zone E)";
CM_ SG_ 468 TimedCharge4Active "Indicates whether the first timed charging option is active or not.";
CM_ SG_ 468 TimedCharge4ActiveFri "Indicates whether the first timed charging option is active for Friday or not.";
CM_ SG_ 468 TimedCharge4ActiveMon "Indicates whether the first timed charging option is active for Monday or not.";
CM_ SG_ 468 TimedCharge4ActiveSat "Indicates whether the first timed charging option is active for Saturday or not.";
CM_ SG_ 468 TimedCharge4ActiveSun "Indicates whether the first timed charging option is active for Sunday or not.";
CM_ SG_ 468 TimedCharge4ActiveThur "Indicates whether the first timed charging option is active for Thursday or not.";
CM_ SG_ 468 TimedCharge4ActiveTues "Indicates whether the first timed charging option is active for Tuesday or not.";
CM_ SG_ 468 TimedCharge4ActiveWed "Indicates whether the first timed charging option is active for Wednesday or not.";
CM_ SG_ 468 TimedCharge4EndTimeA "Indicates the end time of Zone A within the 24 hour clock.
Note: The start of Zone A is 00:00 i.e. midnight";
CM_ SG_ 468 TimedCharge4EndTimeB "Indicates the end time of Zone B within the 24 hour clock.
Note: The start of Zone B is the end time of Zone A";
CM_ SG_ 468 TimedCharge4EndTimeC "Indicates the end time of Zone C within the 24 hour clock.
Note: The start of Zone C is the end time of Zone B";
CM_ SG_ 468 TimedCharge4EndTimeD "Indicates the end time of Zone D within the 24 hour clock.
Note: The start of Zone D is the end time of Zone C";
CM_ SG_ 468 TimedCharge4ZoneA "Indicates the Electricity pricing within the specified timeframe (Zone A)";
CM_ SG_ 468 TimedCharge4ZoneB "Indicates the Electricity pricing within the specified timeframe (Zone B)";
CM_ SG_ 468 TimedCharge4ZoneC "Indicates the Electricity pricing within the specified timeframe (Zone C)";
CM_ SG_ 468 TimedCharge4ZoneD "Indicates the Electricity pricing within the specified timeframe (Zone D)";
CM_ SG_ 468 TimedCharge4ZoneE "Indicates the Electricity pricing within the specified timeframe (Zone E)";
CM_ SG_ 79 EMACOCMonitorStatsRx "The status of the Sole Rear or Rear Right (delete where applicable) Electric Machine's open circuit monitor for the 3-phase AC.";
CM_ SG_ 79 EMCurrentACBusRx "The status of the Sole Rear or Rear Right (delete where applicable) Electric Machine's Current measurement at the AC connector.";
CM_ SG_ 79 EMCurrentDCBusRx "The Sole Rear or Rear Right (delete where applicable) Electric Machine's Current measurement of the DC bus.
";
CM_ SG_ 79 EMOperatingModeRx "The status of the Sole Rear or Rear Right (delete where applicable) Electric Machine's operating mode.";
CM_ SG_ 79 EMOpModeRxGpCounter "This counter forms part of a safety-related signal group.
It is incremented by the task which generates the data set used in the CRC calculation, and may be used to determine the health of the data generation task.
Refer to STJLR 18.036 for more detail.";
CM_ SG_ 79 EMOpModeRxGpCS "This CRC shall be calculated in compliance with STJLR 18.036 Version 8.
The Data Segment Polynomial shall be constructed from the details in the network configuration file.";
CM_ SG_ 79 EMVoltageDCLinkRx "The status of the Sole Rear or Rear Right (delete where applicable) Electric Machine's Voltage measurement at the DC connector.";
CM_ SG_ 79 InvASCStatsRx "The status of the Sole Rear or Rear Right (delete where applicable) Electric Machine's Active Short Circuit (ASC) operation.";
CM_ SG_ 79 RapidDschrgDiagStatsRx "The status of the Sole Rear or Rear Right (delete where applicable) Electric Machine's rapid discharge mechanism.";
CM_ SG_ 81 EMCurrentACBusFx "The status of the Sole front or front right (delete where applicable) Electric Machine's Current measurement at the AC connector.";
CM_ SG_ 81 EMOperatingModeFx "The status of the Sole front or front Right (delete where applicable) Electric Machine's operating mode.";
CM_ SG_ 81 EMOpModeFxGpCounter "This counter forms part of a safety-related signal group.
It is incremented by the task which generates the data set used in the CRC calculation, and may be used to determine the health of the data generation task.
Refer to STJLR 18.036 for more detail.";
CM_ SG_ 81 EMOpModeFxGpCS "This CRC shall be calculated in compliance with STJLR 18.036 Version 8.
The Data Segment Polynomial shall be constructed from the details in the network configuration file.";
CM_ SG_ 81 EMVoltageDCLinkFx "The status of the Sole front or front right (delete where applicable) Electric Machine's Voltage measurement at the DC connector.";
CM_ SG_ 15 EPICBAuthDataControl "EPICBAuthDataControl:
CAN signal transmitted by BCM to authenticate (Challenge/Response sequence) the EPIC_B module.

Note: Same details as EPICAuthDataControl as currently used, but concerns Secondary EPIC Module for full electric vehicle, hence the reference to EPIC_B 

0x00 - Idle
0x01 - Key
0x03 - Challenge Response
0x05 - Terminate";
CM_ SG_ 1315 NMmessageEPICD "Network Management Signal. This signal contains Network Management Data. This data includes the DA (Destination Address), CF (Control Field) and up to 6 data bytes of user defined data. 

The MSB of the signal must be written to the COM layer first (with an offset of zero in wr_bytes() ) and therefore transmitted on the bus first.
Similarly, subscribing modules will receive the MSB of the signal when they call rd_bytes(0).

E.g. wr_bytes(0) = published_signal_MSB;

Subscribed_Signal_MSB = rd_bytes(0);
";
CM_ SG_ 331 DCDCCurrentMVExt "DCDC Current on the HV Bus.
Positive - Power transfer from HV to 12v side (Buck Mode).
Negative - Power transfer from 12v to HV side (Boost Mode).";
CM_ SG_ 419 BatteryHealthMsgReq "Signal to report battery condition in Transport and Factory Mode only. These messages will not be seen by the end customer.";
CM_ SG_ 419 CabinCleanBattBudgetGWM "Battery Budget allocated for Cabin Cleaning Feature";
CM_ SG_ 419 DCDC12vSetpointRequest "DCDC low voltage set point in buck mode
";
CM_ SG_ 419 DCDC2LVSetpointRequest "Second DCDC low voltage set point in buck mode.";
CM_ SG_ 419 ElPowerStatus "Multi-stage engine-off battery State of Charge related warning mechanism
";
CM_ SG_ 419 ExtPwrSupDetected "Indicates an external power supply is connected.";
CM_ SG_ 419 LibertyHornInhibitReq "Request to the SDS to prevent actuation of the Horn based on power availability";
CM_ SG_ 419 LibertyWashPumpInhibitReq "Request to the SDS to prevent actuation of the Washer Pump based on power availability";
CM_ SG_ 419 LibertyWiperInhibitReq "Request to the SDS to prevent actuation of the Windscreen Wiper based on power availability";
CM_ SG_ 419 PwrSupWakeUpTopUpReq "Indicate if the 12V battery needs topping up from the HV Battery on a PHEV/HEV/BEV.";
CM_ SG_ 419 SB2MissMsg "Indicates that frames have been missed from the SBU 2 LIN";
CM_ SG_ 419 SBMissMsg "Indicates that frames have been missed from the SBU LIN";
CM_ SG_ 419 TerrainModeReqExt "The 'Drive mode' or 'Terrain mode' selected by the driver. (Jaguar Drive Control and Land Rover Terrain Response)";
CM_ SG_ 277 AutoTRStatus "Indicates that the Auto Terrain Response program is on or off.

0 = Auto TR Off
1 = Auto TR On";
CM_ SG_ 277 CanclAutoTrProgReq "Advises Auto Terrain Response that the requested Terrain Program/Mode cannot be provided ";
CM_ SG_ 277 ElPowerStatus "Multi-stage engine-off battery State of Charge related warning mechanism
";
CM_ SG_ 277 PSDBActvDiagState "PSDB active diagnostics state.";
CM_ SG_ 277 RtnPrevProg "Advises Auto Terrain Response that a return to the previous program occurred due to a Program change timeout.";
CM_ SG_ 277 TerrainModeReqExt "The 'Drive mode' or 'Terrain mode' selected by the driver. (Jaguar Drive Control and Land Rover Terrain Response)";
CM_ SG_ 277 TerrainModeReqStatus "signal for the activation of the passive electrical features included in ECO Mode for future car lines.Signal will allow handshake of TR prior to entering mode removing potential entry and exit faults.";
CM_ SG_ 277 TerrProgActv "Currently active Terrain Program/Mode";
CM_ SG_ 694 PnCChinaVINShare "Provides the user request for PnC to be active or not (For China GBT only).";
CM_ SG_ 694 PnCContractCertReq "Master controller request for PnC Contract Certificate";
CM_ SG_ 694 PnCToggleUserReq "Provides the user request for PnC via the toggle button";
CM_ SG_ 694 PnCWakeUpReq "Signal used to request the vehicle to wake-up for plug and charge certificate installation";
CM_ SG_ 340 CabinCoolantTempMin "The minimum cabin coolant temperature";
CM_ SG_ 340 CabinCoolantTempTarget "The target cabin coolant temperature";
CM_ SG_ 340 FFHOperatingStatus "Status of the Fuel Burning Heater (FFH).";
CM_ SG_ 340 PreClimateRequests "Pre-Climate requested state

Summary of the preconditioning request(s) from multiple ECUs (e.g. Battery cooling, Timed Preclimate, Preclimate direct request (Mobile office), Engine heat)";
CM_ SG_ 340 PreClimateStatus "Pre-Climate system status - Current preconditioning operating system state. ";
CM_ SG_ 340 PreClimRangeComfort "The priority of Range or Comfort for Climate Pre-Conditioning";
CM_ SG_ 340 SolarMistDataReq "Request to provide Solar and Mist data from sensor";
CM_ SG_ 936 CabinInCarHumidity "Cabin InCar Humidity";
CM_ SG_ 936 CbnZn1AirOffTempTgt "Cabin Zone 1 Air Off Temperature Target";
CM_ SG_ 936 CbnZn2AirOffTempTgt "Cabin Zone 2 Air Off Temperature Target";
CM_ SG_ 936 CbnZn3AirOffTempTgt "Cabin Zone 3 Air Off Temperature Target";
CM_ SG_ 936 CbnZn4AirOffTempTgt "Cabin Zone 4 Air Off Temperature Target";
CM_ SG_ 936 CbnZn5AirOffTempTgt "Cabin Zone 5 Air Off Temperature Target";
CM_ SG_ 936 CbnZn6AirOffTempTgt "Cabin Zone 6 Air Off Temperature Target";
CM_ SG_ 936 EvapInletAirTemp "Front Evap Refrigerant Inlet Temperature";
CM_ SG_ 933 CabinZone1TempAvg "Estimated Cabin Zone 1 Average Temperature";
CM_ SG_ 933 CabinZone2TempAvg "Estimated Cabin Zone 2 Average Temperature";
CM_ SG_ 933 CabinZone3TempAvg "Estimated Cabin Zone 3 Average Temperature";
CM_ SG_ 933 CabinZone4TempAvg "Estimated Cabin Zone 4 Average Temperature";
CM_ SG_ 933 CabinZone5TempAvg "Estimated Cabin Zone 5 Average Temperature";
CM_ SG_ 933 CabinZone6TempAvg "Estimated Cabin Zone 6 Average Temperature";
CM_ SG_ 933 CbnAuxAutoBlowerLevel "Cabin Aux Automatic Blower Level";
CM_ SG_ 933 CbnFrntAutoBlowerLevel "Cabin ATC Front Automatic Blower Level";
CM_ SG_ 931 CabinZone1Power "Cabin ATC Zone 1 Power calculated in Watts";
CM_ SG_ 931 CabinZone2Power "Cabin ATC Zone 2 Power calculated in Watts";
CM_ SG_ 931 CabinZone3Power "Cabin ATC Zone 3 Power caluclated in W";
CM_ SG_ 931 CabinZone4Power "Cabin ATC Zone 4 Power caluclated in W";
CM_ SG_ 932 ACSuctionPressure "A/C suction pressure reading";
CM_ SG_ 932 CabinZone5Power "Cabin ATC Zone 5 Power caluclated in W";
CM_ SG_ 932 CabinZone6Power "Cabin ATC Zone 6 Power caluclated in W";
CM_ SG_ 932 eACActualSpeed "eAC Speed Actual";
CM_ SG_ 932 SolarLoad "Cabin front Solar Load Average in  Watts";
CM_ SG_ 934 CabinZone1TempSetPoint "Cabin ATC Zone 1 Set Point Temperature";
CM_ SG_ 934 CabinZone2TempSetPoint "Cabin ATC Zone 2 Set Point Temperature";
CM_ SG_ 934 CabinZone3TempSetPoint "Cabin ATC Zone 3 Set Point Temperature";
CM_ SG_ 934 CabinZone4TempSetPoint "Cabin ATC Zone 4 Set Point Temperature";
CM_ SG_ 934 CabinZone5TempSetPoint "Cabin ATC Zone 5 Set Point Temperature";
CM_ SG_ 934 CabinZone6TempSetPoint "Cabin ATC Zone 6 Set Point Temperature";
CM_ SG_ 934 CbnAuxBlowerAirFlow "Cabin Aux Automatic Blower Level";
CM_ SG_ 934 CbnFrntBlowerAirFlow "Cabin ATC front Blower Air Flow";
CM_ SG_ 114 CabinCoolDerateOvrrdReq "EV thermal arbitration Cabin Derate Inhibit Request";
CM_ SG_ 114 ClimHVHeaterPowerAct "Actual HV (cabin) heater power consumption information sent to VSC for energy management strategy.";
CM_ SG_ 114 ClimHVHeaterPowerReq "HV PTC heater power request sent to VSC for energy management strategy.";
CM_ SG_ 114 eACHVILStats "electric Air Compressor (eAC) Hazardous Voltage Interlock Loop Status";
CM_ SG_ 114 EACVoltage "HV DC bus voltage measured at the EAC compressor";
CM_ SG_ 114 HVACHeatPumpReq "Used to request HVAC Heat Pump Mode";
CM_ SG_ 114 HVBattCoolingStatusExt "Notification to battery thermal management of the state of the cooling system";
CM_ SG_ 114 HVBattHeatingStatus "Indicates to BECM whether the battery is being heated by CCS.";
CM_ SG_ 114 HVBattHeatingStatusExt "HV Battery Heating Status";
CM_ SG_ 114 HVCHHVILStats "Hight Voltage Coolant Heater (HVCH) Hazardous Voltage Interlock Loop Status";
CM_ SG_ 114 HVCHVoltageHV "HV DC bus voltage measured at the HV Coolant Heater";
CM_ SG_ 114 Timed12VLoadEnergyLeft "This will be used to educate the customer that selected loads impact their range.

This is the total remaining energy consumption of the customer actived 'timed' 12V loads controlled by the HVAC module, not considering whether they are currently load-managed off.

Stealth deployment is not shown here, auto operation is.

e.g. If the user switches on the heated front screen and this will be on for 3 minutes, then the signal should jump up to the value of [Amps current consumption*13.5V*0.05 hours] and begin to count down, such that its remaining energy crosses 0 after 3 minutes has elapsed.";
CM_ SG_ 560 ClimMinEffectivePwrReq "The high voltage power required by the Climate Control System to deliver the lowest effective level of component thermal management and cabin comfort.";
CM_ SG_ 560 ClimNoComfortPowerReq "The high voltage power required by the Climate Control System to deliver the lowest allowable level of component thermal management and cabin conditioning excluding comfort.";
CM_ SG_ 560 ClimPredContKwComfort "Predicted value of power (kW) to maintain Cabin
comfort attribute based on the present customer
selected Climate settings if the vehicle were in
'Comfort' Driver Mode and assuming Cabin has
already reached 'pulled-up' or 'pulled-down'
target.";
CM_ SG_ 560 ClimPredContKwEco "Predicted value of power (kW) to maintain Cabin
comfort attribute based on the present customer
selected Climate settings if the vehicle were in 'Eco' Driver Mode and assuming Cabin has
already reached 'pulled-up' or 'pulled-down'
target.";
CM_ SG_ 560 ClimPredContKwGMH "Predicted value of power (kW) to maintain Cabin
comfort attribute based on the present customer
selected Climate settings if the vehicle were in 'Get Me Home' Driver Mode and assuming
Cabin has already reached 'pulled-up' or 'pulled down' target.";
CM_ SG_ 560 ClimPredKwhPreconTgt "Estimate of remaining Climate System energy consumption to reach cabin target, for the present Timed preconditioning event. Used for EV Range Prediction feature.";
CM_ SG_ 560 CoolFanRequestPMZ "For control of the Engine Cooling Fans to give the required setting (in %) of the Cooling Fans.
ECM may add or decrease the amount requested if conditions do not permit the request to be honoured.";
CM_ SG_ 560 HVACRangePredValid "Validity of published HVAC power consumption values at HVAC controller wakeup";
CM_ SG_ 232 BlowerSpeed "Speed of the Aircon Blowers.
";
CM_ SG_ 232 ClimatePowerRequestExt "Predicted power consumption of both manageable loads AND inviolable load request information sent to VSC  for power management strategy";
CM_ SG_ 232 ClimPowerConsumpExt "Actual power consumption information sent to VSC for power management strategy";
CM_ SG_ 232 ClimPowerLimitOverride "Request from HVAC to VSC to override the climate power limit.
";
CM_ SG_ 232 Const12VLoadPwrConsump "This will be used to educate the customer that selected loads impact their range.

This is the total power consumption of the customer actived 'continuous' 12V loads controlled by the HVAC module. 

Stealth deployment is not shown here, auto operation is.

e.g. If the user switches on/turns up the blowers, then the signal should jump up to the value of [average Amps current consumption*13.5V].";
CM_ SG_ 232 eACOprModeStatus "eAC operating mode status";
CM_ SG_ 232 EdriveEMPumpDRReq "e-drive coolant pump duty ratio request from HVAC";
CM_ SG_ 232 HVCHOprModeStatus "HVCH Operating mode status";
CM_ SG_ 232 InCarTemp "In-cabin temperature.

This is the EuCD variant, which has a different scaling and range to the legacy Jaguar signal InCarTemp_J.";
CM_ SG_ 232 InCarTempQF "In-cabin temperature.

This is the EuCD variant, which has a different scaling and range to the legacy Jaguar signal InCarTemp_J.";
CM_ SG_ 232 PNPreConReq "Partial Network Function Request Signal. This signal is used to inform the network master that the partial networking function is active. The modules involved in this function are HVAC, PCM, BCCM, BECM, TCU";
CM_ SG_ 232 WakeNetForPreRunHVAC "CAN signal stating if the network is required for Pre-Run.

Description of bit field detailing each application function to be stored in the DID (After-Run Function 1- 16):
Pre Run Function 1 (Bit 0) - 
HVAC gets external temperature prior to a fuel burn event
PCM obtains fuel burn information (no. of burns, burns times etc)following a fuel burn event.";
CM_ SG_ 795 EWPClimatePostRunCom "Climate Pump post run command";
CM_ SG_ 795 EWPClimateRPMCom "Climate Pump target speed";
CM_ SG_ 535 CabinCleaningWakeUpAck "Signal to acknowledge the trigger of scheduled cabin cleaning.";
CM_ SG_ 535 ClimateLoadPwrFeedReq "Power feed request for climate loads.";
CM_ SG_ 535 ClimPredContKwCmfExt "Predicted value of power (kW) to maintain Cabin
comfort attribute based on the present customer
selected Climate settings if the vehicle were in
'Comfort' Driver Mode and assuming Cabin has
already reached 'pulled-up' or 'pulled-down'
target.";
CM_ SG_ 535 ClimPredContKwECOExt "Predicted value of power (kW) to maintain Cabin
comfort attribute based on the present customer
selected Climate settings if the vehicle were in 'Eco' Driver Mode and assuming Cabin has
already reached 'pulled-up' or 'pulled-down'
target.";
CM_ SG_ 535 ClimPredContKwGMHExt "Predicted value of power (kW) to maintain Cabin
comfort attribute based on the present customer
selected Climate settings if the vehicle were in 'Get Me Home' Driver Mode and assuming
Cabin has already reached 'pulled-up' or 'pulled down' target.";
CM_ SG_ 535 FLCHeatingReq "Request to turn on/off the FLC heating element";
CM_ SG_ 937 CbnRecircDoorPos "Cabin Recirculation Door Position";
CM_ SG_ 937 ChlrRefrgOutletTemp "Chiller Refrigerant Outlet Temperature degC";
CM_ SG_ 937 OHXRefrgOutletTemp "OHX Refrigerant Outlet Temperature degC";
CM_ SG_ 798 ChlrClntFlowRateReq "Chiller coolant flow rate request";
CM_ SG_ 798 ChlrClntInletTempReq "Heat pump target chiller coolant temperature request";
CM_ SG_ 798 eACPowerUseActual "eAC power usage actual";
CM_ SG_ 798 HVCHClntInletTemp "HVCH coolant inlet temperature";
CM_ SG_ 798 HVCHClntOutletTemp "HVCH coolant outlet temperature";
CM_ SG_ 798 HVCHCoolantStatus "Coolant condition as reported by High Voltage Coolant Heater (HVCH) component";
CM_ SG_ 798 HVCHStatus "Status of High Voltage Coolant Heater (HVCH) as reported by the HVCH component";
CM_ SG_ 798 HVCHVariant "High Voltage Coolant Heater (HVCH) variant type as reported by the HVCH component";
CM_ SG_ 798 OHXOprModeStatus "Heat pump mode OHX status";
CM_ SG_ 798 RefrgModeActual "Current refrigerent mode";
CM_ SG_ 798 SOTAPrepResponseHVAC "Response to a SOTA preparation request";
CM_ SG_ 302 CabinCleaningActivStat "Status update of the Cabin Cleaning feature from the Climate System.";
CM_ SG_ 302 CabinCleaningStatHVAC "Status of Cabin Cleaning feature as consolidated at the climate unit.";
CM_ SG_ 302 CabinCleanSchPreconReq "Signal to trigger the Pre condition checks of the scheduled Cabin Cleaning.";
CM_ SG_ 302 PM25ExtAQIBand "Signal to represent the External Air quality categorisation as per the market applicable. CcfPM25Market will be used to define the conversion matrix applicable";
CM_ SG_ 302 PM25External "Outside dust concentration (Particulate Matter of less than 2.5 microns in Air Quality Index format).";
CM_ SG_ 302 PM25IntAQIBand "Signal to represent the Internal Air quality categorisation as per the market applicable. CcfPM25Market will be used to define the conversion matrix applicable. to the current market.";
CM_ SG_ 302 PM25Internal "Cabin dust concentration (Particulate Matter of less than 2.5 microns in Air Quality Index format).";
CM_ SG_ 302 PNCabinCleanReq "Partial Network Function Request Signal. This signal is used to inform the network master that the partial networking function Cabin Cleaning is active. The modules involved in this function are HVAC, GWM, BCM, PCM & TCU.";
CM_ SG_ 236 DCDC12vActualCurrent "Current on the 12v side of the Vehicle DCDC Converter
Negative - Power transfer from HV to 12v side (Buck Mode).  
Positive - Power transfer from 12v to HV side (Boost Mode).";
CM_ SG_ 236 DCDC12vActualSetpoint "Actual DCDC voltage setpoint on the LV side after any applied deratings. This is used in Buck mode.
";
CM_ SG_ 236 DCDC12vActualVoltage "Output voltage on the 12v bus from the Vehicle DCDC Converter
";
CM_ SG_ 236 DCDC12vMaxCurrent "Maximum  available DCDC Current on 12v Bus
Negative - Power transfer from HV to 12v side (Buck Mode).  
";
CM_ SG_ 236 DCDC12VoltStatus "DCDC low voltage status";
CM_ SG_ 345 DCDCCoolantLevel "MHEV3 system coolant level sensor status";
CM_ SG_ 345 DCDCCurrentHV "DCDC Current on the HV Bus. 
Positive - Power transfer from HV to 12v side (Buck Mode).  
Negative - Power transfer from 12v to HV side (Boost Mode).  ";
CM_ SG_ 345 DCDCHighVoltageStatus "DCDC high voltage status";
CM_ SG_ 345 DCDCHVActualSetpoint "Actual DCDC high voltage set point in boost mode after any applied deratings.
";
CM_ SG_ 345 DCDCInternalError "DCDC Internal Error flag status";
CM_ SG_ 345 DCDCOverVoltageDerate "DCDC over voltage derate status
";
CM_ SG_ 345 DCDCTemperature "DCDC temperature";
CM_ SG_ 345 DCDCTemperatureDerate "DCDC temperature derate status
";
CM_ SG_ 345 DCDCUnderVoltageDerate "DCDC under voltage derate status
";
CM_ SG_ 700 CountryCode "ASCII code of actual country";
CM_ SG_ 700 IMCRangeOnRoute "EV Range prediction along programmed Navigation route in km.

If EV Range is less than distance of programmed route, this is the distance the vehicle can travel along the route until it is out of energy.

If EV Range is greater than distance of programmed route, this is the distance of route plus any remaining range (based on the average consumption of that programmed route).";
CM_ SG_ 700 IMCRangeOnRouteStatus "Flag to indicate that a route is programmed and IMCRangeOnRoute value has been calculated ready for use.";
CM_ SG_ 700 RouteStatusIGM "Status of the actual route";
CM_ SG_ 700 RouteVersionIMC "Indicates when the IMC has calculated/recalculated a route and tags it";
CM_ SG_ 705 BulkSoCSingleUseDisp "The target Bulk SoC target that the vehicle will charge to for one charge only, referenced in customer visible SoC %.
";
CM_ SG_ 705 BulkSoCTargetDisp "The target Bulk SoC target that the vehicle will charge to, referenced in customer visible SoC %.";
CM_ SG_ 705 CreepModeRequest "Request from the HMI for Creep to be turned ON or OFF";
CM_ SG_ 705 DataContractHLDF "Indicates if the current Hotspot feature settings within the HLDF node allow the data contract usage limits to be exceeded.

0 - Allowed.
1 - Not Allowed";
CM_ SG_ 705 EcoDrvCoachUserInput "Driver feedback from HMI to Eco Driving Coach feature to enable or disable.";
CM_ SG_ 705 HotspotRequestHLDF "Indicates the requested state of the hotspot feature from the HLDF.";
CM_ SG_ 705 InfotainmentLanguage "Indicates the current status of the user defined System language setting in the HLDF. 

0 - Undefined
1 - Swedish
2 - Danish
3 - Finnish
4 - English
5 - German
6 - Dutch
7 - French
8 - Italian
9 - Spanish
10 - Portuguese
11 - English (US)
12 - French (Canadian)
13 - Japanese (Katakana)
14 - Portuguese (Brazil)
15 - English with number codes
16 - Hungarian
17 - Turkish
18 - Russian
19 - Polish
20 - Czech
21 - Norwegian
22 - Latin Spanish
23 - English (Australian)
24 - Thai
25 - Ford Asia Pacific English
26 - Chinese (Simplified)
27 - Taiwanese
28 - Chinese (Traditional)
29 - Flemish
30 - Bulgarian
31 - Estonian
32 - Greek
33 - Latvian
34 - Lithuanian
35 - Romanian
36 - Slovakian
37 - Slovene
38 - Korean
39 - Croatian
40 - Malaysian
41 - Arabic
42 - Chinese_Mandarin
43 - Chinese_Wu
44 - Chinese_Cantonese
45 - 62 Reserved
63 - Error (default = English)";
CM_ SG_ 705 LocationDataTCU "To enable or disable the transmission of GPS Location data from the TCU to Telematics provider. Managed through a soft-key on the HLDF";
CM_ SG_ 705 PasswordHotspotHLDF "Signal to indicate which hotspot password is active.";
CM_ SG_ 705 PasswordRequestHLDF "Indicates the requested state of the Password settings from the HLDF.";
CM_ SG_ 705 PopupRequestHLDF "Indicates the popup request this is currently actioned by the HLDF.";
CM_ SG_ 705 SOTAPrepResponseIGM "Response to a SOTA preparation request";
CM_ SG_ 433 ChargDataWakeUpReq "Signal used to request the vehicle to wake-up if telematics want to update charging data (e.g. Change in departure time / charge now).";
CM_ SG_ 433 ChargeEnRouteChargeNow "Upon arrival at a POI where charging is available en route to a destination, the IMC sets a Charge
Now Override to On. ";
CM_ SG_ 433 ChargeEnRoutePOIDist "Distance to the POI identified in ChargeEnRoutePOINumIMC from the vehicle's current location.";
CM_ SG_ 433 ChargeEnRoutePOIEnergy "Energy required to travel to the POI identified in ChargeEnRoutePOINumIMC from the vehicle's current location.";
CM_ SG_ 433 ChargeEnRoutePOIkW "Charging rate available at the POI identified in ChargeEnRoutePOINumIMC.";
CM_ SG_ 433 ChargeEnRtPOINumIMCPt1 "Identification number of a Point Of Interest with public charging capability. Unique number is given to each POI which is reset each time a new destination is entered into the Navigation system.
(First group for POI information)";
CM_ SG_ 433 ChargeNowRequest "Status from the Driver that they have requested to Charge the vehicle immediately (rather than a timed charging regime). This request is only valid until the vehicle is next unplugged.";
CM_ SG_ 433 ChargeNowRequestExt "Status from the Driver that they have requested to Charge the vehicle immediately (rather than a timed charging regime). This request is only valid until the vehicle is next unplugged.";
CM_ SG_ 433 TimedChrgReq "Allow user to select timed charging for a charging cycle";
CM_ SG_ 433 V2LDischrgLmtSoCIVI "V2L SOC discharge limit";
CM_ SG_ 434 ChargeEnRouteNxtDist "Distance from the POI identified in ChargeEnRoutePOINumIMC to either the next POI along the route, or the Destination if the starting POI is the last one en route.";
CM_ SG_ 434 ChargeEnRouteNxtEnergy "Energy required to travel from the POI identified in ChargeEnRoutePOINumIMC to either the next
POI along the route, or the Destination if the starting POI is the last one en route.";
CM_ SG_ 434 ChargeEnRtPOINumIMCPt2 "Identification number of a Point Of Interest with public charging capability. Unique number is given to each POI which is reset each time a new destination is entered into the Navigation system.
(Second group for POI information)";
CM_ SG_ 434 ChrgACCurrentLmtV1G "AC current limit request from energy provider while V1G charging";
CM_ SG_ 434 ChrgControlCmdV1G "Request to smart charging Start/Stop";
CM_ SG_ 434 ChrgV1GCXNStatus "Offboard connection status with energy provider";
CM_ SG_ 692 NextPresetDepTimeDate "Indicates the next Preset Departure Time Day set by the vehicle user.";
CM_ SG_ 692 NextPresetDepTimeHour "Indicates the next Preset Departure Time Hour set by the vehicle user.";
CM_ SG_ 692 NextPresetDepTimeMins "Indicates the next Preset Departure Time Minute set by the vehicle user.";
CM_ SG_ 692 NextPresetDepTimeMnth "Indicates the next Preset Departure Time Month set by the vehicle user.";
CM_ SG_ 692 NextPresetDepTimeYear "Indicates the next Preset Departure Time Year set by the vehicle user.";
CM_ SG_ 693 ChgPreConNowReq "User request- manual request to turn on/off preconditioning for fast charging (momentary signal)";
CM_ SG_ 693 ChrgACCurrUserLimit "User selected AC charge rate limit for control the AC charge current received from the grid while AC charging";
CM_ SG_ 186 ABRCTAMode "Indicateds the user slected mode of ABRCTA";
CM_ SG_ 186 AdaptDriBeamEnableReq "New signal from IPC to BCM to confirm when adaptive driving beam is enabled in cluster menu";
CM_ SG_ 186 AnimProjEnableReq "Indicates if WakeUp ShutDown Projection Sequence is selected by User";
CM_ SG_ 186 AnimProjPreviewReq "Request from Infotainment to preview Animated Logo Projection";
CM_ SG_ 186 AppOpenWalkAwyCloseReq "User Request Setting for approach opening and walk away close";
CM_ SG_ 186 ApproachUnlockOnOffReq "User Request Setting for approach opening and walk away close";
CM_ SG_ 186 ARAMode "Used to switch ON/OFF the ARA System. System is default ON when Ignition ON.
Default value will be 2, 'ON with Ignition'";
CM_ SG_ 186 AutoHighBeamEnableReq "User request to enable or disable the Auto High Beam Control ";
CM_ SG_ 186 AutoHighBeamSAEModeReq "User request to configure the Auto High Beam Control for SAE mode sensitivity ";
CM_ SG_ 186 AutoHoldEnable "Signal to request enable or disable Auto Hold";
CM_ SG_ 186 BSMMode "Signal generated as a result of a 'soft' switch press on the HLDF. Used to switch ON/OFF BSM System. System is default ON when Ignition ON.
Default value will be 2, 'ON with Ignition'";
CM_ SG_ 186 ChargingModeChcToLatch "Indicate the vehicle user preferences in terms of charging (ie. time charging On/Off)";
CM_ SG_ 186 CloseAllApertureReqIVI "User switch selection from PiVi screen to request All doors to close, , User switch on PIVI tagged to OpenCloseSwPressIVI request (close)";
CM_ SG_ 186 DDOpenCloseSwPressIVI "User switch selection from PiVi screen to open, close or stop the Drivers door";
CM_ SG_ 186 DRDOpenCloseSwPressIVI "User switch selection from PiVi screen to open, close or stop the Drivers Rear door.";
CM_ SG_ 186 GestDrsOpnClosOnOffReq "User Request Setting for gesture sensors for ALL Power Doors";
CM_ SG_ 186 IMCHybridModeRequest "Driver requested hybrid driving mode.";
CM_ SG_ 186 OnDemandHoldEnable "Signal to request enable or disable On Time Hold";
CM_ SG_ 186 PDOpenCloseSwPressIVI "User switch selection from PiVi screen to open, close or stop the Passenger Front door.";
CM_ SG_ 186 PEOEnablementStatus "Request to enable Predictive Energy Optimisation (PEO)";
CM_ SG_ 186 PRDOpenCloseSwPressIVI "User switch selection from PiVi screen to open, close or stop the Passenger Rear door";
CM_ SG_ 186 RCTAReq "Indicateds the user slected state of RCTA";
CM_ SG_ 186 RPCCustInhibitReq "Indicates the user selected state of RPC";
CM_ SG_ 186 SupMainBeamEnableReq "New signal from IPC to BCM to inform when supplementary main beam is enabled in cluster menu";
CM_ SG_ 186 WalkAwayLockOnOffReq "User Setting for Walk Away Locking";
CM_ SG_ 497 ALAnimateReqIVI "Signal from infotainment to indicate the customer wants to  switch between two colour dynamically";
CM_ SG_ 497 ALBrightnessReqIVI "Signal from infotainment infotainment to indicate the customer wants to change the brightness of the ambient lighting";
CM_ SG_ 497 ALCustomL1ColReqIVI "Signal from infotainment to indicate the customer wants to  change the colour of the roof ambient lighting";
CM_ SG_ 497 ALCustomL1IntReqIVI "Signal from infotainment to indicate the customer wants to  change the intensity of the roof ambient lighting";
CM_ SG_ 497 ALCustomL2ColReqIVI "Signal from infotainment to indicate the customer wants to  change the colour of the feature ambient lighting";
CM_ SG_ 497 ALCustomL2IntReqIVI "Signal from infotainment to indicate the customer wants to  change the intensity of the feature ambient lighting";
CM_ SG_ 497 ALCustomL3ColReqIVI "Signal from infotainment to indicate the customer wants to  change the colour of the texture ambient lighting";
CM_ SG_ 497 ALCustomL3IntReqIVI "Signal from infotainment to indicate the customer wants to  change the intensity of the texture ambient lighting";
CM_ SG_ 497 ALCustomL4ColReqIVI "Signal from infotainment to indicate the customer wants to  change the colour of the footwell ambient lighting";
CM_ SG_ 497 ALCustomL4IntReqIVI "Signal from infotainment to indicate the customer wants to  change the intensity of the footwell ambient lighting";
CM_ SG_ 497 ALDriverModeReqIVI "Signal from infotainment to indicate the customer wants to freeze the current lighting configuration independently of the driver mode";
CM_ SG_ 497 ALOnOffReqIVI "Signal from infotainment to indicate the customer wants to activate/desactivate the ambient lighting";
CM_ SG_ 497 ALPresetReqIVI "Signal from infotainment to indicate the customer wants to switch to a ambient lighting preset";
CM_ SG_ 497 PEODestPredictConfidnc "Auto Route prediction confidence level published by navigation system";
CM_ SG_ 44 DrvlineDampStatusFx "Driveline damping operating mode for the Sole Front or Front Right (delete where applicable) Electric Machine.";
CM_ SG_ 44 InverterHVILStatusFx "The status of the Sole Front or Front Right (delete where applicable) Inverter's HVIL monitor.";
CM_ SG_ 24 DrvlineDampStatusRx "Driveline damping operating mode for the Sole Rear or Rear Right (delete where applicable) Electric Machine.";
CM_ SG_ 24 InverterHVILStatusRx "The status of the Sole Rear or Rear Right (delete where applicable) Inverter's HVIL monitor.";
CM_ SG_ 117 EPICAuthDataControl "EPICAuthDataControl:
CAN signal transmitted by BCM to authenticate (Challenge/Response sequence) the EPIC module. 

0x00 - Idle
0x01 - Key
0x03 - Challenge Response
0x05 - Terminate";
CM_ SG_ 135 EPICAuthDataTarget "EPICAuthDataTarget
CAN signal transmitted by EPIC, covers the Authentication (Challenge Response Sequence) between the EPIC and BCM.

0x00 - Idle
0x02 - Challenge
0x04 - Status";
CM_ SG_ 164 EMCurrentDcLink "High Voltage DC Bus current measured at the Electrical Machine Inverter
Positive - Motoring Mode
Negative - Generating Mode
";
CM_ SG_ 375 EMTemperature "Coil temperature of the Electrical Machine

For PHEV:
Temperature of the Electric Machine's Stator";
CM_ SG_ 375 EPICMILRequest "MIL request signal required to be raised by EPIC module and received by PCM. This is necessary in order to comply with the OBDII requirement for NAS market.";
CM_ SG_ 375 InverterTemperature "Temperature of the ACDC Inverter";
CM_ SG_ 375 InvTemperatureDerate "ACDC Inverter temperarture derate status
";
CM_ SG_ 375 TemperatureRate "Rate of change of Electric Machine temperature (warning of change of Max / Min limits)";
CM_ SG_ 168 EMACOCMonitorStatus "The status of the EPIC's open circuit monitor for the HV AC Bus.";
CM_ SG_ 168 EMOperatingModeExt "Electrical Machine operating mode";
CM_ SG_ 168 EMOpModeExtGpCounter "This counter forms part of a safety-related signal group.
It is incremented by the task which generates the data set used in the CRC calculation, and may be used to determine the health of the data generation task.
Refer to STJLR 18.036 for more detail.";
CM_ SG_ 168 EMOpModeExtGpCS "This CRC shall be calculated in compliance with STJLR 18.036 Version 5.
The Data Segment Polynomial shall be constructed from the details in the network configuration file.";
CM_ SG_ 168 EMVoltageDCLinkExt "High voltage DC bus voltage measured at the electric machine inverter.";
CM_ SG_ 168 RapidDschrgDiagStatus "Status of the HV DC bus rapid discharge mechanism";
BA_DEF_  "Baudrate" FLOAT 1000 1000000;
BA_DEF_  "BusType" STRING ;
BA_DEF_  "DBName" STRING ;
BA_DEF_  "ProtocolType" STRING ;
BA_DEF_ BU_  "NmAsrNode" ENUM  "No","Yes";
BA_DEF_ BU_  "NmAsrNodeIdentifier" INT 0 255;
BA_DEF_ BO_  "GenMsgCycleTime" FLOAT 0 300000;
BA_DEF_ BO_  "GenMsgDelayTime" FLOAT 0 300000;
BA_DEF_ BO_  "GenMsgSendType" ENUM  "cyclic","spontaneous","cyclicIfActive","spontaneousWithDelay","cyclicAndSpontaneous","cyclicAndSpontaneousWithDelay","IfActive","NoMsgSendType";
BA_DEF_ BO_  "GenMsgStartDelayTime" FLOAT 0 300000;
BA_DEF_ SG_  "GenSigSendType" ENUM  "Cyclic","OnWrite","OnWriteWithRepetition","OnChange","OnChangeWithRepetition","IfActive","IfActiveWithRepetition","NoSigSendType";
BA_DEF_ SG_  "GenSigStartValue" FLOAT -1.79769313486232E+308 1.84467440737096E+019;
BA_DEF_ BO_  "SystemMessageLongSymbol" STRING ;
BA_DEF_DEF_  "Baudrate" 1000;
BA_DEF_DEF_  "BusType" "";
BA_DEF_DEF_  "DBName" "";
BA_DEF_DEF_  "ProtocolType" "";
BA_DEF_DEF_  "NmAsrNode" "No";
BA_DEF_DEF_  "NmAsrNodeIdentifier" 0;
BA_DEF_DEF_  "GenMsgCycleTime" 0;
BA_DEF_DEF_  "GenMsgDelayTime" 0;
BA_DEF_DEF_  "GenMsgSendType" "cyclic";
BA_DEF_DEF_  "GenMsgStartDelayTime" 0;
BA_DEF_DEF_  "GenSigSendType" "Cyclic";
BA_DEF_DEF_  "GenSigStartValue" 0;
BA_DEF_DEF_  "SystemMessageLongSymbol" "";
BA_ "ProtocolType" "CAN";
BA_ "BusType" "CAN";
BA_ "Baudrate" 500000;
BA_ "DBName" "PMZ_HSCAN";
BA_ "NmAsrNodeIdentifier" BU_ BECM 162;
BA_ "NmAsrNode" BU_ BECM 1;
BA_ "NmAsrNodeIdentifier" BU_ GWM 30;
BA_ "NmAsrNode" BU_ GWM 1;
BA_ "NmAsrNodeIdentifier" BU_ HVAC 131;
BA_ "NmAsrNode" BU_ HVAC 1;
BA_ "NmAsrNodeIdentifier" BU_ PCM 149;
BA_ "NmAsrNode" BU_ PCM 1;
BA_ "NmAsrNodeIdentifier" BU_ SGCM 148;
BA_ "NmAsrNode" BU_ SGCM 1;
BA_ "NmAsrNodeIdentifier" BU_ Virtual_Node 127;
BA_ "NmAsrNode" BU_ Virtual_Node 1;
BA_ "GenMsgSendType" BO_ 103 1;
BA_ "GenMsgDelayTime" BO_ 103 20;
BA_ "GenMsgSendType" BO_ 19 1;
BA_ "GenMsgDelayTime" BO_ 19 10;
BA_ "GenMsgSendType" BO_ 65 1;
BA_ "GenMsgDelayTime" BO_ 65 10;
BA_ "GenMsgSendType" BO_ 17 1;
BA_ "GenMsgDelayTime" BO_ 17 40;
BA_ "GenMsgSendType" BO_ 1537 1;
BA_ "GenMsgDelayTime" BO_ 1537 100;
BA_ "GenMsgSendType" BO_ 1536 1;
BA_ "GenMsgDelayTime" BO_ 1536 100;
BA_ "GenMsgSendType" BO_ 1281 1;
BA_ "GenMsgDelayTime" BO_ 1281 100;
BA_ "GenMsgCycleTime" BO_ 417 40;
BA_ "GenMsgCycleTime" BO_ 315 80;
BA_ "GenMsgCycleTime" BO_ 512 200;
BA_ "GenMsgSendType" BO_ 225 1;
BA_ "GenMsgDelayTime" BO_ 225 5;
BA_ "GenMsgSendType" BO_ 7 1;
BA_ "GenMsgDelayTime" BO_ 7 5;
BA_ "GenMsgSendType" BO_ 1672 1;
BA_ "GenMsgDelayTime" BO_ 1672 50;
BA_ "GenMsgSendType" BO_ 1673 1;
BA_ "GenMsgDelayTime" BO_ 1673 50;
BA_ "GenMsgSendType" BO_ 1674 1;
BA_ "GenMsgDelayTime" BO_ 1674 50;
BA_ "GenMsgSendType" BO_ 1675 1;
BA_ "GenMsgDelayTime" BO_ 1675 50;
BA_ "GenMsgSendType" BO_ 1314 1;
BA_ "GenMsgDelayTime" BO_ 1314 100;
BA_ "GenMsgCycleTime" BO_ 136 20;
BA_ "GenMsgCycleTime" BO_ 138 20;
BA_ "GenMsgCycleTime" BO_ 140 20;
BA_ "GenMsgCycleTime" BO_ 142 20;
BA_ "GenMsgCycleTime" BO_ 144 20;
BA_ "GenMsgCycleTime" BO_ 519 160;
BA_ "GenMsgCycleTime" BO_ 152 20;
BA_ "GenMsgCycleTime" BO_ 328 100;
BA_ "GenMsgCycleTime" BO_ 369 100;
BA_ "GenMsgCycleTime" BO_ 332 100;
BA_ "GenMsgCycleTime" BO_ 334 100;
BA_ "GenMsgSendType" BO_ 744 1;
BA_ "GenMsgDelayTime" BO_ 744 5;
BA_ "GenMsgSendType" BO_ 745 1;
BA_ "GenMsgDelayTime" BO_ 745 5;
BA_ "GenMsgSendType" BO_ 746 1;
BA_ "GenMsgDelayTime" BO_ 746 5;
BA_ "GenMsgCycleTime" BO_ 748 300;
BA_ "GenMsgCycleTime" BO_ 749 300;
BA_ "GenMsgCycleTime" BO_ 154 20;
BA_ "GenMsgCycleTime" BO_ 249 40;
BA_ "GenMsgCycleTime" BO_ 263 20;
BA_ "GenMsgCycleTime" BO_ 794 400;
BA_ "GenMsgSendType" BO_ 1617 1;
BA_ "GenMsgDelayTime" BO_ 1617 100;
BA_ "GenMsgSendType" BO_ 1604 1;
BA_ "GenMsgDelayTime" BO_ 1604 100;
BA_ "GenMsgSendType" BO_ 1605 1;
BA_ "GenMsgDelayTime" BO_ 1605 50;
BA_ "GenMsgCycleTime" BO_ 209 20;
BA_ "GenMsgSendType" BO_ 465 1;
BA_ "GenMsgDelayTime" BO_ 465 120;
BA_ "GenMsgSendType" BO_ 466 1;
BA_ "GenMsgDelayTime" BO_ 466 120;
BA_ "GenMsgSendType" BO_ 467 1;
BA_ "GenMsgDelayTime" BO_ 467 120;
BA_ "GenMsgSendType" BO_ 468 1;
BA_ "GenMsgDelayTime" BO_ 468 120;
BA_ "GenMsgSendType" BO_ 79 1;
BA_ "GenMsgSendType" BO_ 81 1;
BA_ "GenMsgSendType" BO_ 15 1;
BA_ "GenMsgDelayTime" BO_ 15 5;
BA_ "GenMsgSendType" BO_ 1315 1;
BA_ "GenMsgDelayTime" BO_ 1315 95;
BA_ "GenMsgCycleTime" BO_ 331 80;
BA_ "GenMsgSendType" BO_ 1630 1;
BA_ "GenMsgCycleTime" BO_ 419 100;
BA_ "GenMsgCycleTime" BO_ 277 100;
BA_ "GenMsgSendType" BO_ 694 1;
BA_ "GenMsgDelayTime" BO_ 694 200;
BA_ "GenMsgCycleTime" BO_ 340 100;
BA_ "GenMsgCycleTime" BO_ 936 1000;
BA_ "SystemMessageLongSymbol" BO_ 936 "HVAC_PMZ_CabinZoneAirOffTempTarget";
BA_ "GenMsgCycleTime" BO_ 933 1000;
BA_ "GenMsgCycleTime" BO_ 931 1000;
BA_ "GenMsgCycleTime" BO_ 932 1000;
BA_ "GenMsgCycleTime" BO_ 934 1000;
BA_ "GenMsgCycleTime" BO_ 114 20;
BA_ "GenMsgCycleTime" BO_ 560 200;
BA_ "GenMsgCycleTime" BO_ 232 40;
BA_ "GenMsgCycleTime" BO_ 795 600;
BA_ "GenMsgCycleTime" BO_ 535 200;
BA_ "GenMsgCycleTime" BO_ 937 1000;
BA_ "GenMsgCycleTime" BO_ 798 600;
BA_ "GenMsgCycleTime" BO_ 302 160;
BA_ "GenMsgCycleTime" BO_ 236 50;
BA_ "GenMsgCycleTime" BO_ 345 160;
BA_ "GenMsgSendType" BO_ 700 1;
BA_ "GenMsgDelayTime" BO_ 700 160;
BA_ "GenMsgSendType" BO_ 705 1;
BA_ "GenMsgDelayTime" BO_ 705 200;
BA_ "GenMsgSendType" BO_ 433 1;
BA_ "GenMsgDelayTime" BO_ 433 100;
BA_ "GenMsgSendType" BO_ 434 1;
BA_ "GenMsgDelayTime" BO_ 434 100;
BA_ "GenMsgSendType" BO_ 692 1;
BA_ "GenMsgDelayTime" BO_ 692 160;
BA_ "GenMsgSendType" BO_ 693 1;
BA_ "GenMsgDelayTime" BO_ 693 80;
BA_ "GenMsgSendType" BO_ 186 1;
BA_ "GenMsgDelayTime" BO_ 186 100;
BA_ "GenMsgSendType" BO_ 497 1;
BA_ "GenMsgDelayTime" BO_ 497 10;
BA_ "GenMsgSendType" BO_ 44 1;
BA_ "GenMsgDelayTime" BO_ 44 10;
BA_ "GenMsgSendType" BO_ 24 1;
BA_ "GenMsgDelayTime" BO_ 24 10;
BA_ "GenMsgSendType" BO_ 117 1;
BA_ "GenMsgDelayTime" BO_ 117 10;
BA_ "GenMsgSendType" BO_ 135 1;
BA_ "GenMsgDelayTime" BO_ 135 5;
BA_ "GenMsgCycleTime" BO_ 164 20;
BA_ "GenMsgCycleTime" BO_ 375 100;
BA_ "GenMsgCycleTime" BO_ 168 20;
BA_ "GenSigStartValue" SG_ 19 GSAPosReq 15;
BA_ "GenSigStartValue" SG_ 17 ABSPwrTrnTorqReq 1;
BA_ "GenSigStartValue" SG_ 17 BrakePressureQF 1;
BA_ "GenSigStartValue" SG_ 17 VehicleSpeedQF 1;
BA_ "GenSigSendType" SG_ 1537 CCP_BCM_Rx 1;
BA_ "GenSigSendType" SG_ 1536 CCP_BCM_Tx 1;
BA_ "GenSigSendType" SG_ 1281 NMmessageBCMHS 1;
BA_ "GenSigStartValue" SG_ 417 AlarmModeHS 3;
BA_ "GenSigSendType" SG_ 417 CLockCmd_2 1;
BA_ "GenSigSendType" SG_ 417 CLockCmd_3 1;
BA_ "GenSigStartValue" SG_ 417 PowerModeQF 1;
BA_ "GenSigStartValue" SG_ 512 UpCabinRelHumidityQF 1;
BA_ "GenSigStartValue" SG_ 512 UpWScreenAirTempQF 1;
BA_ "GenSigStartValue" SG_ 512 UpWScreenGlassTempQF 1;
BA_ "GenSigSendType" SG_ 225 CentralLockStatus2 1;
BA_ "GenSigSendType" SG_ 225 PwrChargeFlapCloseReq 1;
BA_ "GenSigSendType" SG_ 7 ParkLockDataControl 1;
BA_ "GenSigSendType" SG_ 1672 UUDTBCMResponse1 1;
BA_ "GenSigSendType" SG_ 1673 UUDTBCMResponse2 1;
BA_ "GenSigSendType" SG_ 1674 UUDTBCMResponse3 1;
BA_ "GenSigSendType" SG_ 1675 UUDTBCMResponse4 1;
BA_ "GenSigSendType" SG_ 1314 NMmessageBECM 1;
BA_ "GenSigStartValue" SG_ 136 HVBattChgContPwrLmt 65535;
BA_ "GenSigStartValue" SG_ 136 HVBattChgPowerLimitExt 65535;
BA_ "GenSigStartValue" SG_ 138 HVBattChgCurrentLimit 1023;
BA_ "GenSigStartValue" SG_ 152 HVBattOCMonitorStatus 1;
BA_ "GenSigStartValue" SG_ 152 HVBattStateofHealth 1000;
BA_ "GenSigStartValue" SG_ 152 HVBattStatusCritical 1;
BA_ "GenSigStartValue" SG_ 328 HVBattCellTempAverage 80;
BA_ "GenSigStartValue" SG_ 328 HVBattCellTempColdest 80;
BA_ "GenSigStartValue" SG_ 328 HVBattCellTempHottest 80;
BA_ "GenSigStartValue" SG_ 369 HVBattInletCoolantTemp 254;
BA_ "GenSigStartValue" SG_ 369 HVBattInletCoolantTempQF 1;
BA_ "GenSigSendType" SG_ 744 MVBattCalibrationID01 1;
BA_ "GenSigSendType" SG_ 745 MVBattCalibrationID02 1;
BA_ "GenSigSendType" SG_ 746 MVBattCalibVerifNumber 1;
BA_ "GenSigStartValue" SG_ 794 BSBattSOC 75;
BA_ "GenSigStartValue" SG_ 794 BSBattVoltage 205;
BA_ "GenSigStartValue" SG_ 794 BSBsdEstimState 1;
BA_ "GenSigSendType" SG_ 1617 CCPTesterToEDPM 1;
BA_ "GenSigSendType" SG_ 1604 CCPTesterToHVAC 1;
BA_ "GenSigSendType" SG_ 1605 CCPHVACToTester 1;
BA_ "GenSigStartValue" SG_ 209 DCDCOperatingModeExt2 6;
BA_ "GenSigStartValue" SG_ 465 TimedCharge1ZoneA 3;
BA_ "GenSigStartValue" SG_ 465 TimedCharge1ZoneB 3;
BA_ "GenSigStartValue" SG_ 465 TimedCharge1ZoneC 3;
BA_ "GenSigStartValue" SG_ 465 TimedCharge1ZoneD 3;
BA_ "GenSigStartValue" SG_ 465 TimedCharge1ZoneE 3;
BA_ "GenSigStartValue" SG_ 466 TimedCharge2ZoneA 3;
BA_ "GenSigStartValue" SG_ 466 TimedCharge2ZoneB 3;
BA_ "GenSigStartValue" SG_ 466 TimedCharge2ZoneC 3;
BA_ "GenSigStartValue" SG_ 466 TimedCharge2ZoneD 3;
BA_ "GenSigStartValue" SG_ 466 TimedCharge2ZoneE 3;
BA_ "GenSigStartValue" SG_ 467 TimedCharge3ZoneA 3;
BA_ "GenSigStartValue" SG_ 467 TimedCharge3ZoneB 3;
BA_ "GenSigStartValue" SG_ 467 TimedCharge3ZoneC 3;
BA_ "GenSigStartValue" SG_ 467 TimedCharge3ZoneD 3;
BA_ "GenSigStartValue" SG_ 467 TimedCharge3ZoneE 3;
BA_ "GenSigStartValue" SG_ 468 TimedCharge4ZoneA 3;
BA_ "GenSigStartValue" SG_ 468 TimedCharge4ZoneB 3;
BA_ "GenSigStartValue" SG_ 468 TimedCharge4ZoneC 3;
BA_ "GenSigStartValue" SG_ 468 TimedCharge4ZoneD 3;
BA_ "GenSigStartValue" SG_ 468 TimedCharge4ZoneE 3;
BA_ "GenSigStartValue" SG_ 79 EMCurrentDCBusRx 4096;
BA_ "GenSigStartValue" SG_ 79 EMOperatingModeRx 14;
BA_ "GenSigSendType" SG_ 15 EPICBAuthDataControl 1;
BA_ "GenSigSendType" SG_ 1315 NMmessageEPICD 1;
BA_ "GenSigStartValue" SG_ 419 DCDC12vSetpointRequest 254;
BA_ "GenSigStartValue" SG_ 419 DCDC2LVSetpointRequest 254;
BA_ "GenSigStartValue" SG_ 419 LibertyHornInhibitReq 1;
BA_ "GenSigStartValue" SG_ 419 LibertyWashPumpInhibitReq 1;
BA_ "GenSigStartValue" SG_ 419 LibertyWiperInhibitReq 1;
BA_ "GenSigStartValue" SG_ 419 TerrainModeReqExt 7;
BA_ "GenSigStartValue" SG_ 277 TerrainModeReqExt 7;
BA_ "GenSigStartValue" SG_ 114 EACVoltage 1022;
BA_ "GenSigStartValue" SG_ 232 eACOprModeStatus 3;
BA_ "GenSigStartValue" SG_ 232 EdriveEMPumpDRReq 11;
BA_ "GenSigStartValue" SG_ 232 InCarTempQF 1;
BA_ "GenSigStartValue" SG_ 795 EWPClimatePostRunCom 7;
BA_ "GenSigStartValue" SG_ 795 EWPClimateRPMCom 255;
BA_ "GenSigStartValue" SG_ 798 eACPowerUseActual 255;
BA_ "GenSigStartValue" SG_ 798 HVCHClntInletTemp 2047;
BA_ "GenSigStartValue" SG_ 798 HVCHClntOutletTemp 2047;
BA_ "GenSigStartValue" SG_ 798 OHXOprModeStatus 3;
BA_ "GenSigStartValue" SG_ 798 RefrgModeActual 20;
BA_ "GenSigStartValue" SG_ 302 PM25External 510;
BA_ "GenSigStartValue" SG_ 302 PM25Internal 510;
BA_ "GenSigStartValue" SG_ 236 DCDC12vActualCurrent 510;
BA_ "GenSigStartValue" SG_ 236 DCDC12vActualVoltage 254;
BA_ "GenSigStartValue" SG_ 236 DCDC12vMaxCurrent 510;
BA_ "GenSigStartValue" SG_ 345 DCDCCurrentHV 1022;
BA_ "GenSigStartValue" SG_ 705 DataContractHLDF 1;
BA_ "GenSigSendType" SG_ 705 EcoDrvCoachUserInput 1;
BA_ "GenSigStartValue" SG_ 705 LocationDataTCU 1;
BA_ "GenSigStartValue" SG_ 705 PasswordHotspotHLDF 1;
BA_ "GenSigStartValue" SG_ 705 RoamingHLDF 2;
BA_ "GenSigStartValue" SG_ 434 ChrgACCurrentLmtV1G 1023;
BA_ "GenSigStartValue" SG_ 692 NextPresetDepTimeDate 31;
BA_ "GenSigStartValue" SG_ 692 NextPresetDepTimeHour 24;
BA_ "GenSigStartValue" SG_ 692 NextPresetDepTimeMins 60;
BA_ "GenSigStartValue" SG_ 692 NextPresetDepTimeMnth 12;
BA_ "GenSigStartValue" SG_ 692 NextPresetDepTimeYear 255;
BA_ "GenSigStartValue" SG_ 693 ChrgACCurrUserLimit 1023;
BA_ "GenSigSendType" SG_ 186 ABRCTAMode 1;
BA_ "GenSigSendType" SG_ 186 AdaptDriBeamEnableReq 1;
BA_ "GenSigSendType" SG_ 186 AnimProjEnableReq 1;
BA_ "GenSigSendType" SG_ 186 AnimProjPreviewReq 1;
BA_ "GenSigSendType" SG_ 186 AppOpenWalkAwyCloseReq 1;
BA_ "GenSigStartValue" SG_ 186 ApproachUnlockOnOffReq 1;
BA_ "GenSigSendType" SG_ 186 ApproachUnlockOnOffReq 1;
BA_ "GenSigStartValue" SG_ 186 ARAMode 2;
BA_ "GenSigSendType" SG_ 186 ARAMode 1;
BA_ "GenSigSendType" SG_ 186 AutoHighBeamEnableReq 1;
BA_ "GenSigSendType" SG_ 186 AutoHighBeamSAEModeReq 1;
BA_ "GenSigSendType" SG_ 186 AutoHoldEnable 1;
BA_ "GenSigStartValue" SG_ 186 BSMMode 2;
BA_ "GenSigSendType" SG_ 186 BSMMode 1;
BA_ "GenSigSendType" SG_ 186 ChargingModeChcToLatch 1;
BA_ "GenSigSendType" SG_ 186 CloseAllApertureReqIVI 1;
BA_ "GenSigSendType" SG_ 186 DDOpenCloseSwPressIVI 1;
BA_ "GenSigSendType" SG_ 186 DRDOpenCloseSwPressIVI 1;
BA_ "GenSigStartValue" SG_ 186 GestDrsOpnClosOnOffReq 1;
BA_ "GenSigSendType" SG_ 186 GestDrsOpnClosOnOffReq 1;
BA_ "GenSigSendType" SG_ 186 IMCHybridModeRequest 1;
BA_ "GenSigSendType" SG_ 186 OnDemandHoldEnable 1;
BA_ "GenSigSendType" SG_ 186 PDOpenCloseSwPressIVI 1;
BA_ "GenSigSendType" SG_ 186 PEOEnablementStatus 1;
BA_ "GenSigSendType" SG_ 186 PRDOpenCloseSwPressIVI 1;
BA_ "GenSigSendType" SG_ 186 RCTAReq 1;
BA_ "GenSigStartValue" SG_ 186 RPCCustInhibitReq 1;
BA_ "GenSigSendType" SG_ 186 RPCCustInhibitReq 1;
BA_ "GenSigSendType" SG_ 186 SupMainBeamEnableReq 1;
BA_ "GenSigStartValue" SG_ 186 WalkAwayLockOnOffReq 1;
BA_ "GenSigSendType" SG_ 186 WalkAwayLockOnOffReq 1;
BA_ "GenSigSendType" SG_ 497 ALAnimateReqIVI 1;
BA_ "GenSigSendType" SG_ 497 ALBrightnessReqIVI 1;
BA_ "GenSigSendType" SG_ 497 ALCustomL1ColReqIVI 1;
BA_ "GenSigSendType" SG_ 497 ALCustomL1IntReqIVI 1;
BA_ "GenSigSendType" SG_ 497 ALCustomL2ColReqIVI 1;
BA_ "GenSigSendType" SG_ 497 ALCustomL2IntReqIVI 1;
BA_ "GenSigSendType" SG_ 497 ALCustomL3ColReqIVI 1;
BA_ "GenSigSendType" SG_ 497 ALCustomL3IntReqIVI 1;
BA_ "GenSigSendType" SG_ 497 ALCustomL4ColReqIVI 1;
BA_ "GenSigSendType" SG_ 497 ALCustomL4IntReqIVI 1;
BA_ "GenSigSendType" SG_ 497 ALDriverModeReqIVI 1;
BA_ "GenSigSendType" SG_ 497 ALOnOffReqIVI 1;
BA_ "GenSigSendType" SG_ 497 ALPresetReqIVI 1;
BA_ "GenSigSendType" SG_ 497 PEODestPredictConfidnc 1;
BA_ "GenSigSendType" SG_ 117 EPICAuthDataControl 1;
BA_ "GenSigSendType" SG_ 135 EPICAuthDataTarget 1;
BA_ "GenSigStartValue" SG_ 164 EMCurrentDcLink 2046;
BA_ "GenSigStartValue" SG_ 375 InverterTemperature 254;
BA_ "GenSigStartValue" SG_ 168 EMOperatingModeExt 14;
VAL_ 103 EPBBrakeApplyReq 0 "Error Condition" 1 "SCS Braking not required" 2 "SCS Braking required" 3 "Error Condition" ;
VAL_ 103 EPBDecelerationTarget 255 "Eror marker" ;
VAL_ 103 EPBFault 0 "System OK - No Faults" 1 "System Fault" 2 "System Fault - Cannot apply EPB" 3 "System Fault - Cannot release EPB" ;
VAL_ 103 EPBStatus_EUCD 0 "Faulty combination0" 1 "Faulty combination1" 2 "Low Speed Automation Ready - Rear clamp force = NONE" 3 "Rear Calliper Closed (Rear clamp force, Full)" 4 "Faulty combination4" 5 "Rear Calliper transition between OPEN - CLOSED or CLOSED - OPEN" 6 "RWU By EPB Active, Rear Clamp force = SOME" 7 "Faulty combination7" 8 "Faulty combination8" 9 "Rear Calliper Open, Rear Clamp force = NONE" 10 "EPB Limphome Active, Rear Clamp force = Some" 11 "Faulty combination11" 12 "ECD by BCM Active, Rear Clamp force = Some, by BCM" 13 "Faulty combination13" 14 "Faulty combination14" 15 "General Faults Or Maintenance mode" ;
VAL_ 103 KeepNetInAfterRunPBM 0 "Function does not need the network" 1 "Function does need the network" ;
VAL_ 19 GSAPosReq 0 "Park" 1 "Reverse" 2 "Neutral" 3 "Drive" 7 "Sport" 14 "Fault" 15 "Un-confirmed position" ;
VAL_ 19 GSAPosReqOrigin 0 "Unknown (Initial)" 1 "Driver Request" 2 "Vehicle Request" 3 "Transmission Request" ;
VAL_ 19 GSAPosReqRepeat 0 "Request" 1 "Repeat Request" ;
VAL_ 17 ABSEngVacReq 0 "no vacuum assistance required" 1 "vacuum assistance required" ;
VAL_ 17 ABSPwrTrnTorqReq 0 "powertrain torque is not required" 1 "powertrain torque is required" ;
VAL_ 17 BrakePressureQF 0 "The accuracy of the data is undefinable" 1 "Data is temporarily undefinable, evaluation in progress" 2 "The accuracy of the data is not within specification" 3 "The data is calculated with the specified accuracy" ;
VAL_ 17 VehicleSpeedQF 0 "The accuracy of the data is undefinable" 1 "Data is temporarily undefinable, evaluation in progress" 2 "The accuracy of the data is not within specification" 3 "The data is calculated with the specified accuracy" ;
VAL_ 417 AlarmModeHS 0 "Set" 1 "Unset" 2 "Active" 3 "Ignore (Initial Value)" ;
VAL_ 417 BCMReqBusAwakePT 0 "Node not requesting bus keepawake." 1 "Node requesting bus keepawake." ;
VAL_ 417 CabinCleaningWakeUpReq 0 "Off" 1 "On" ;
VAL_ 417 CarModeHS 0 "Normal" 1 "Factory" 2 "Unused2" 3 "Transport" 4 "Unused4" ;
VAL_ 417 CentralLockStatus 0 "Unlocked" 1 "Part Locked" 2 "Central Locked" 3 "Double Locked" 4 "TP_NO_DL (TheftProtectNODoubleLock)" ;
VAL_ 417 CentralLockStatus3 0 "Unlocked" 1 "Part Locked" 2 "Central Locked" 3 "Double Locked" 4 "TP_NO_DL (TheftProtectNODoubleLock)" ;
VAL_ 417 PHEVFuelFillRequest 0 "No pending request" 1 "Fuel refill button has been pressed and awaiting acknowledgement" 2 "Not used" 3 "Fault (circuit, button or stuck fault)" ;
VAL_ 417 PowerMode 0 "KeyOut" 1 "KeyRecentlyOut" 2 "KeyApproved_0" 3 "PostAccessory_0" 4 "Accessory_1" 5 "PostIgnition_1" 6 "IgnitionOn_2" 7 "Running_2" 9 "Crank_3" ;
VAL_ 417 PowerModeQF 0 "PowerModeUndefined" 1 "PowerModeEvaluationInProgress" 2 "Not defined" 3 "PowerModeOK" ;
VAL_ 417 RemoteEngStartDrivPres 0 "Driver Not Present" 1 "Driver Present" ;
VAL_ 417 RemoteFunctionStatus 0 "Default" 1 "Engine Start Allowed" 2 "Engine Blocked" 15 "Invalid" ;
VAL_ 417 RemoteStartStatusMS 0 "Normal Mode (Driver present)" 1 "Remote Mode (Driver NOT present)" ;
VAL_ 417 TimedChrgWakeUpReq 0 "Timed Charging Wake Up Not Required" 1 "Timed Charging Wake Up Request" ;
VAL_ 315 SolarIntensityQF 0 "The accuracy of the data is undefinable" 1 "Data is temporarily undefinable, evaluation in progress" 2 "The accuracy of the data is not within specification" 3 "The data is calculated with the specified accuracy" ;
VAL_ 315 SolarSensorError 0 "no error" 1 "error" ;
VAL_ 512 ClimateLoadPwrFeedStat 0 "Off" 1 "On" ;
VAL_ 512 UpCabinRelHumidityQF 0 "The accuracy of the data is undefinable" 1 "Data is temporarily undefinable, evaluation in progress" 2 "The accuracy of the data is not within specification" 3 "The data is calculated with the specified accuracy" ;
VAL_ 512 UpWScreenAirTempQF 0 "The accuracy of the data is undefinable" 1 "Data is temporarily undefinable, evaluation in progress" 2 "The accuracy of the data is not within specification" 3 "The data is calculated with the specified accuracy" ;
VAL_ 512 UpWScreenGlassTempQF 0 "The accuracy of the data is undefinable" 1 "Data is temporarily undefinable, evaluation in progress" 2 "The accuracy of the data is not within specification" 3 "The data is calculated with the specified accuracy" ;
VAL_ 225 CentralLockStatus2 0 "Unlocked" 1 "Part Locked" 2 "Central Locked" 3 "Double Locked" 4 "TP_NO_DL (TheftProtectNODoubleLock)" ;
VAL_ 225 PwrChargeFlapCloseReq 0 "No Request" 1 "Close Request" ;
VAL_ 138 HVBattDerateWarning 0 "No Derate" 1 "Derate Warning" ;
VAL_ 144 HVBattMILRequest 0 "No MIL Request" 1 "Request MIL On" 2 "Request MIL Flashing" 3 "Reserved" ;
VAL_ 152 HVBattClntPumpDiagStat 0 "Pump OK" 1 "Pump Not OK" ;
VAL_ 152 HVBattContactorStatus 0 "Open" 1 "Closed" ;
VAL_ 152 HVBattHVILStatus 0 "Ok" 1 "Not Ok" ;
VAL_ 152 HVBattIsolationStatus 0 "Isolation OK" 1 "Isolation Not OK" ;
VAL_ 152 HVBattOCMonitorStatus 0 "OK" 1 "Don't know" 2 "Not OK" 3 "Unused" ;
VAL_ 152 HVBattStatusCAT3 0 "No Fault" 1 "CAT 3 Fault" ;
VAL_ 152 HVBattStatusCAT4Derate 0 "No Fault" 1 "CAT4 Fault" ;
VAL_ 152 HVBattStatusCAT5BPOChg 0 "No Fault" 1 "CAT5 BPO Charger fault" ;
VAL_ 152 HVBattStatusCAT6DlyBPO 0 "No Fault" 1 "CAT6 Delayed BPO fault" ;
VAL_ 152 HVBattStatusCAT7NowBPO 0 "No Fault" 1 "CAT7 Immediate BPO fault" ;
VAL_ 152 HVBattStatusCritical 0 "NOTUSED1" 1 "OK" 2 "Fault" 3 "NOTUSED2" ;
VAL_ 152 HVBattWeldCheckStatus 0 "No Weld Detected" 1 "Weld Detected" ;
VAL_ 369 HVBattCoolantLevel 0 "Coolant level OK" 1 "Coolant level Low" ;
VAL_ 369 HVBattCoolingRequestExt 0 "Chiller OFF" 1 "Chiller Requested" 2 "Chiller Essential" 3 "Undefined" ;
VAL_ 369 HVBattInletCoolantTemp 254 "Initialisation" 255 "Failure" ;
VAL_ 369 HVBattInletCoolantTempQF 0 "The accuracy of the data is undefinable" 1 "Data is temporarily undefinable, evaluation in progress" 2 "The accuracy of the data is not within specification" 3 "The data is calculated with the specified accuracy" ;
VAL_ 334 HVBattWakeUpDchReq 0 "HV Battery does not require to be discharged" 1 "HV Battery requests to be discharged" ;
VAL_ 334 HVBattWakeUpThermalReq 0 "HV Battery does not require thermal management" 1 "HV Battery requests thermal management" ;
VAL_ 334 HVBattWakeUpTopUpReq 0 "HV Battery does not require to be charged" 1 "HV Battery requests to be charged" ;
VAL_ 249 MVBattTOCRModeReq 0 "TOCR Not Required" 1 "Desired TOCR" 2 "Critical TOCR" 3 "Successful TOCR" ;
VAL_ 794 BSBsdEstimState 0 "Not learned at all" 1 "Inaccurate" 2 "Accurate" 3 "Invalid" ;
VAL_ 209 DCDCOperatingModeExt2 0 "Standby" 1 "Buck Mode" 2 "Reserved (Boost Mode)" 3 "Bus Discharge Mode" 4 "Bus Test Mode OR Bus Test Failed" 5 "Not Capable" 6 "Initialisation" 7 "Failure" ;
VAL_ 465 TimedCharge1Active 0 "Not Active" 1 "Active" ;
VAL_ 465 TimedCharge1ActiveFri 0 "Not Active for Friday" 1 "Active for Friday" ;
VAL_ 465 TimedCharge1ActiveMon 0 "Not Active for Monday" 1 "Active for Monday" ;
VAL_ 465 TimedCharge1ActiveSat 0 "Not Active for Saturday" 1 "Active for Saturday" ;
VAL_ 465 TimedCharge1ActiveSun 0 "Not Active for Sunday" 1 "Active for Sunday" ;
VAL_ 465 TimedCharge1ActiveThur 0 "Not Active for Thursday" 1 "Active for Thursday" ;
VAL_ 465 TimedCharge1ActiveTues 0 "Not Active for Tuesday" 1 "Active for Tuesday" ;
VAL_ 465 TimedCharge1ActiveWed 0 "Not Active for Wednesday" 1 "Active for Wednesday" ;
VAL_ 465 TimedCharge1ZoneA 0 "Off Peak" 1 "Mid-Peak" 2 "Peak" 3 "Unused" ;
VAL_ 465 TimedCharge1ZoneB 0 "Off Peak" 1 "Mid-Peak" 2 "Peak" 3 "Unused" ;
VAL_ 465 TimedCharge1ZoneC 0 "Off Peak" 1 "Mid-Peak" 2 "Peak" 3 "Unused" ;
VAL_ 465 TimedCharge1ZoneD 0 "Off Peak" 1 "Mid-Peak" 2 "Peak" 3 "Unused" ;
VAL_ 465 TimedCharge1ZoneE 0 "Off Peak" 1 "Mid-Peak" 2 "Peak" 3 "Unused" ;
VAL_ 466 TimedCharge2Active 0 "Not Active" 1 "Active" ;
VAL_ 466 TimedCharge2ActiveFri 0 "Not Active for Friday" 1 "Active for Friday" ;
VAL_ 466 TimedCharge2ActiveMon 0 "Not Active for Monday" 1 "Active for Monday" ;
VAL_ 466 TimedCharge2ActiveSat 0 "Not Active for Saturday" 1 "Active for Saturday" ;
VAL_ 466 TimedCharge2ActiveSun 0 "Not Active for Sunday" 1 "Active for Sunday" ;
VAL_ 466 TimedCharge2ActiveThur 0 "Not Active for Thursday" 1 "Active for Thursday" ;
VAL_ 466 TimedCharge2ActiveTues 0 "Not Active for Tuesday" 1 "Active for Tuesday" ;
VAL_ 466 TimedCharge2ActiveWed 0 "Not Active for Wednesday" 1 "Active for Wednesday" ;
VAL_ 466 TimedCharge2ZoneA 0 "Off Peak" 1 "Mid-Peak" 2 "Peak" 3 "Unused" ;
VAL_ 466 TimedCharge2ZoneB 0 "Off Peak" 1 "Mid-Peak" 2 "Peak" 3 "Unused" ;
VAL_ 466 TimedCharge2ZoneC 0 "Off Peak" 1 "Mid-Peak" 2 "Peak" 3 "Unused" ;
VAL_ 466 TimedCharge2ZoneD 0 "Off Peak" 1 "Mid-Peak" 2 "Peak" 3 "Unused" ;
VAL_ 466 TimedCharge2ZoneE 0 "Off Peak" 1 "Mid-Peak" 2 "Peak" 3 "Unused" ;
VAL_ 467 TimedCharge3Active 0 "Not Active" 1 "Active" ;
VAL_ 467 TimedCharge3ActiveFri 0 "Not Active for Friday" 1 "Active for Friday" ;
VAL_ 467 TimedCharge3ActiveMon 0 "Not Active for Monday" 1 "Active for Monday" ;
VAL_ 467 TimedCharge3ActiveSat 0 "Not Active for Saturday" 1 "Active for Saturday" ;
VAL_ 467 TimedCharge3ActiveSun 0 "Not Active for Sunday" 1 "Active for Sunday" ;
VAL_ 467 TimedCharge3ActiveThur 0 "Not Active for Thursday" 1 "Active for Thursday" ;
VAL_ 467 TimedCharge3ActiveTues 0 "Not Active for Tuesday" 1 "Active for Tuesday" ;
VAL_ 467 TimedCharge3ActiveWed 0 "Not Active for Wednesday" 1 "Active for Wednesday" ;
VAL_ 467 TimedCharge3ZoneA 0 "Off Peak" 1 "Mid-Peak" 2 "Peak" 3 "Unused" ;
VAL_ 467 TimedCharge3ZoneB 0 "Off Peak" 1 "Mid-Peak" 2 "Peak" 3 "Unused" ;
VAL_ 467 TimedCharge3ZoneC 0 "Off Peak" 1 "Mid-Peak" 2 "Peak" 3 "Unused" ;
VAL_ 467 TimedCharge3ZoneD 0 "Off Peak" 1 "Mid-Peak" 2 "Peak" 3 "Unused" ;
VAL_ 467 TimedCharge3ZoneE 0 "Off Peak" 1 "Mid-Peak" 2 "Peak" 3 "Unused" ;
VAL_ 468 TimedCharge4Active 0 "Not Active" 1 "Active" ;
VAL_ 468 TimedCharge4ActiveFri 0 "Not Active for Friday" 1 "Active for Friday" ;
VAL_ 468 TimedCharge4ActiveMon 0 "Not Active for Monday" 1 "Active for Monday" ;
VAL_ 468 TimedCharge4ActiveSat 0 "Not Active for Saturday" 1 "Active for Saturday" ;
VAL_ 468 TimedCharge4ActiveSun 0 "Not Active for Sunday" 1 "Active for Sunday" ;
VAL_ 468 TimedCharge4ActiveThur 0 "Not Active for Thursday" 1 "Active for Thursday" ;
VAL_ 468 TimedCharge4ActiveTues 0 "Not Active for Tuesday" 1 "Active for Tuesday" ;
VAL_ 468 TimedCharge4ActiveWed 0 "Not Active for Wednesday" 1 "Active for Wednesday" ;
VAL_ 468 TimedCharge4ZoneA 0 "Off Peak" 1 "Mid-Peak" 2 "Peak" 3 "Unused" ;
VAL_ 468 TimedCharge4ZoneB 0 "Off Peak" 1 "Mid-Peak" 2 "Peak" 3 "Unused" ;
VAL_ 468 TimedCharge4ZoneC 0 "Off Peak" 1 "Mid-Peak" 2 "Peak" 3 "Unused" ;
VAL_ 468 TimedCharge4ZoneD 0 "Off Peak" 1 "Mid-Peak" 2 "Peak" 3 "Unused" ;
VAL_ 468 TimedCharge4ZoneE 0 "Off Peak" 1 "Mid-Peak" 2 "Peak" 3 "Unused" ;
VAL_ 79 EMACOCMonitorStatsRx 0 "OK" 1 "Not OK" ;
VAL_ 79 EMOperatingModeRx 0 "Standby" 1 "Torque Mode" 2 "Speed Mode" 3 "Voltage Mode" 4 "Bus Test Mode" 5 "Not Capable" 6 "Calibration Mode" 7 "Bus Discharge Mode" 8 "Life Saver Mode" 9 "Pre-Load Mode" 10 "Pre-Flux Mode" 11 "ESA - Engine / EM Stop Assist Mode" 13 "Failure HV Not Allowed" 14 "Initialisation" 15 "Failure" 16 "Dynamic Powerloss" 17 "Static Powerloss" ;
VAL_ 79 InvASCStatsRx 0 "Off" 1 "On" ;
VAL_ 79 RapidDschrgDiagStatsRx 0 "OK" 1 "Not OK" ;
VAL_ 81 EMACOCMonitorStatsFx 0 "OK" 1 "Not OK" ;
VAL_ 81 EMOperatingModeFx 0 "Standby" 1 "Torque Mode" 2 "Speed Mode" 3 "Voltage Mode" 4 "Bus Test Mode" 5 "Not Capable" 6 "Calibration Mode" 7 "Bus Discharge Mode" 8 "Life Saver Mode" 9 "Pre-Load Mode" 10 "Pre-Flux Mode" 11 "ESA - Engine / EM Stop Assist Mode" 13 "Failure HV Not Allowed" 14 "Initialisation" 15 "Failure" 16 "Dynamic Powerloss" 17 "Static Powerloss" ;
VAL_ 81 InvASCStatsFx 0 "Off" 1 "On" ;
VAL_ 81 RapidDschrgDiagStatsFx 0 "OK" 1 "Not OK" ;
VAL_ 419 BatteryHealthMsgReq 0 "NONE" 1 "GOOD" 2 "CHARGE" 3 "REPLACE" 4 "RECOVER" 5 "RESERVED1" 6 "RESERVED2" 7 "RESERVED3" ;
VAL_ 419 BattSOCStripReq 0 "Not Active" 1 "Active" ;
VAL_ 419 CabinCleanBattBudgetGWM 254 "Initialisation" 255 "Invalid" ;
VAL_ 419 DCDC12vSetpointRequest 254 "Initialisation" 255 "Failure" ;
VAL_ 419 DCDC2LVSetpointRequest 254 "Initialisation" 255 "Failure" ;
VAL_ 419 ElPowerStatus 0 "KeepActive" 1 "WarningLowBatteryVolt" 2 "ShutDown" 3 "NotUsed" ;
VAL_ 419 ExtPwrSupDetected 0 "No" 1 "Yes" ;
VAL_ 419 LibertyHornInhibitReq 0 "No Inhibit" 1 "Inhibit" ;
VAL_ 419 LibertyWashPumpInhibitReq 0 "No Inhibit" 1 "Inhibit" ;
VAL_ 419 LibertyWiperInhibitReq 0 "No Inhibit" 1 "Inhibit" ;
VAL_ 419 PwrSupWakeUpTopUpReq 0 "No GWM WakeUp/KeepAlive Required for 12V top up" 1 "GWM WakeUp/KeepAlive Required Required for 12V top up" ;
VAL_ 419 SB2MissMsg 0 "No Message Missing" 1 "Message Missing" ;
VAL_ 419 SBMissMsg 0 "No Message Missing" 1 "Message Missing" ;
VAL_ 419 TerrainModeReqExt 0 "Comfort" 1 "Winter_Grass_Gravel_Snow" 2 "RESERVED2" 3 "Sand" 4 "Mud_Ruts" 5 "Rock_Crawl" 6 "Dynamic" 7 "Failsafe_Default" 8 "SPECIAL_DYNAMIC" 9 "ECO" 10 "Medium_Mu" 11 "ULPM" 12 "Wade" 13 "RESERVED13" 14 "RESERVED14" 15 "RESERVED15" ;
VAL_ 277 AutoTRStatus 0 "Off" 1 "On" ;
VAL_ 277 CanclAutoTrProgReq 0 "Program change permitted" 1 "Cancel program change" ;
VAL_ 277 ElPowerStatus 0 "KeepActive" 1 "WarningLowBatteryVolt" 2 "ShutDown" 3 "NotUsed" ;
VAL_ 277 PSDBActvDiagState 0 "PSDB diagnostics is not finished/not run" 1 "PSDB Active diagnostics is finshed." ;
VAL_ 277 RtnPrevProg 0 "No timeout occurred" 1 "Return to previous program" ;
VAL_ 277 TerrainModeReqExt 0 "Comfort" 1 "Winter_Grass_Gravel_Snow" 2 "RESERVED2" 3 "Sand" 4 "Mud_Ruts" 5 "Rock_Crawl" 6 "Dynamic" 7 "Failsafe_Default" 8 "SPECIAL_DYNAMIC" 9 "ECO" 10 "Medium_Mu" 11 "ULPM" 12 "Wade" 13 "RESERVED13" 14 "RESERVED14" 15 "RESERVED15" ;
VAL_ 277 TerrainModeReqStatus 0 "No user initiated change" 1 "Change initiated by user" 2 "User initiated change complete" 3 "Undefined" ;
VAL_ 277 TerrProgActv 0 "Comfort" 1 "Grass/Gravel/Snow | Rain/Ice/Snow" 3 "Sand | High Drag" 4 "Mud" 5 "Rock Crawl" 6 "Dynamic" 7 "Failsafe Default" 8 "SPECIAL_DYNAMIC" 9 "ECO" 10 "Medium Mu" 11 "Ultra Low Power Mode" 12 "Wade" 13 "Configurable TR" ;
VAL_ 694 PnCChinaVINShare 0 "Initialisation" 1 "Do not share VIN" 2 "VIN share allowed" ;
VAL_ 694 PnCContractCertReq 0 "No Request" 1 "Install Contract Certificate" 2 "Update Contract Certificate" 3 "Delete Contract Certificate" ;
VAL_ 694 PnCToggleUserReq 0 "Initialisation" 1 "PnC Not Supported" 2 "PnC Inactive" 3 "PnC Active" ;
VAL_ 694 PnCWakeUpReq 0 "No Wake-Up" 1 "Wake-Up Required" ;
VAL_ 340 CabinCoolantTempMinUse 0 "Limit can be violated" 1 "Respect limit" ;
VAL_ 340 FFHOperatingStatus 0 "Off" 1 "StartingUp" 2 "Running" 3 "Shutting Down" 4 "Low Voltage" 5 "Low Fuel" 6 "Service Required" 7 "System Failure" 8 "Max Operational Time Reached" 9 "Stopped by User" 10 "Reserved10" 11 "Reserved11" 12 "Reserved12" 13 "Reserved13" 14 "Reserved14" 15 "Reserved15" ;
VAL_ 340 PreClimateRequests 0 "PreClim OFF" 1 "PreClimTimed" 2 "PreClimDirectReq" 3 "PreClimVent" 4 "Engine Heat" 5 "Undefined5" 6 "Undefined6" 7 "Undefined7" ;
VAL_ 340 PreClimateStatus 0 "PreClim OFF" 1 "StartUp" 2 "PreClim with Engine Running" 3 "PreClim Vent" 4 "PreClim Heat" 5 "PreClim Cool" 6 "PreClim" 7 "PreClim Vent & Batt Cool" 8 "PreClim & Batt Cool" 9 "Engine Heat" 10 "PreClim Finished" 11 "PreClim Inhibit HV power" 12 "PreClim Inhibited system fault" 13 "PreClim Finished Partial Precon" 14 "PreClim Requires Engine" 15 "PreClim Grace Period" ;
VAL_ 340 PreClimRangeComfort 0 "Range Prioritised" 1 "Comfort Prioritised" ;
VAL_ 340 SolarMistDataReq 0 "No Request" 1 "Request Sensor data" ;
VAL_ 114 CabinCoolDerateOvrrdReq 0 "No override required" 1 "Elevated cabin temperature override required, not being performed" 2 "User cabin cooling demand override required, not being performed" 3 "Elevated cabin temperature override required, override in effect" 4 "User cabin cooling demand override required, override in effect" ;
VAL_ 114 eACHVILStats 0 "OK" 1 "Not OK" ;
VAL_ 114 EACVoltage 1022 "initialisation" 1023 "Failure" ;
VAL_ 114 HVACHeatPumpReq 0 "No Requests" 1 "Heat Pump Request" 2 "Heat Dump Request" 3 "Special Functions" ;
VAL_ 114 HVBattCoolingStatusExt 0 "No cooling performance information available or fault" 1 "OK, Not Cooling" 2 "Cabin cooling circuit active" 3 "Battery cooling circuit active" 4 "Cabin & Battery cooling circuits active" 5 "Unused5" 6 "Unused6" 7 "Unused7" ;
VAL_ 114 HVBattHeatingStatus 0 "No Heating" 1 "Heating" ;
VAL_ 114 HVBattHeatingStatusExt 0 "Cabin Coolant System Fault" 1 "No Operation" 2 "Cabin Heating Only" 3 "Battery Heating " 4 "Cabin plus Battery Heating" ;
VAL_ 114 HVCHHVILStats 0 "OK" 1 "Not OK" ;
VAL_ 560 HVACRangePredValid 0 "Invalid" 1 "Valid" ;
VAL_ 232 BlowerSpeed 0 "Blower Speed 0-12%" 1 "Blower Speed 13-25%" 2 "Blower Speed 26-37%" 3 "Blower Speed 38-50%" 4 "Blower Speed 51-63%" 5 "Blower Speed 64-75%" 6 "Blower Speed 76-88%" 7 "Blower Speed 89-100%" ;
VAL_ 232 ClimPowerLimitOverride 0 "No Override" 1 "Override" ;
VAL_ 232 eACOprModeStatus 0 "Standby" 1 "eAC Active" 2 "Not Capable" 3 "Initalisation" 4 "Failure" 5 "Failure HV Not Allowed" ;
VAL_ 232 HVCHOprModeStatus 0 "Standby" 1 "HVCH Active" 2 "Not Capable" 3 "Initalisation" 4 "Failure" 5 "Failure HV Not Allowed" ;
VAL_ 232 InCarTempQF 0 "The accuracy of the data is undefinable" 1 "Data is temporarily undefinable, evaluation in progress" 2 "The accuracy of the data is not within specification" 3 "The data is calculated with the specified accuracy" ;
VAL_ 232 PNPreConReq 0 "Not Requested" 1 "Requested" ;
VAL_ 232 WakeNetForPreRunHVAC 0 "ECU does not require the Network" 1 "ECU requires the Network" ;
VAL_ 795 EWPClimatePostRunCom 0 "No Post Running" 1 "Post Run Programme1" 2 "Post Run Programme2" 3 "Post Run Programme3" 4 "Post Run Programme4" 5 "Post Run Programme5" 6 "Post Run Programme6" 7 "Signal Not Available" ;
VAL_ 795 EWPClimateRPMCom 255 "INVALID" ;
VAL_ 535 CabinCleaningWakeUpAck 0 "Off" 1 "On" ;
VAL_ 535 ClimateLoadPwrFeedReq 0 "Off" 1 "On" ;
VAL_ 535 FLCHeatingReq 0 "Off" 1 "On" ;
VAL_ 798 HVCHCoolantStatus 0 "No fault " 1 "Coolant Absent Error" 2 "Coolant Abnormal Gradient" 3 "Coolant Over Temp Error" ;
VAL_ 798 HVCHStatus 0 "Off" 1 "Normal Operation" 2 "Power Derate Active" 3 "Initialisation" 4 "Temporary fault" 5 "Reset required " 6 "Permanent Lockout" ;
VAL_ 798 HVCHVariant 0 "Not supported" 1 "Valeo 800V BEV " ;
VAL_ 798 OHXOprModeStatus 0 "System Fault" 1 "OHX Available for Cabin Heating" 2 "OHX not Available due to Icing" 3 "OHX not available Outside Operating Boundary" ;
VAL_ 798 RefrgModeActual 0 "Compressor Operating Mode Off" 1 "Compressor Operating Mode AC1" 2 "Compressor Operating Mode AC2" 3 "Compressor Operating Mode AC3" 4 "Compressor Operating Mode AC4" 5 "Compressor Operating Mode AC5" 6 "Compressor Operating Mode RH1" 7 "Compressor Operating Mode RH2" 8 "Compressor Operating Mode HP1" 9 "Compressor Operating Mode HP2" 10 "Compressor Operating Mode HP3" 11 "Compressor Operating Mode Purge Routine" 13 "Compressor Operating Mode De Ice Routine" 14 "Compressor Operating Mode Oil Flush Routine" 15 "Compressor Operating Mode RH3" 16 "Compressor Operating Mode RH4" 17 "Compressor Operating Mode RH5" 18 "Compressor Operating Mode HP4" 19 "System Fault" 20 "Not Capable" ;
VAL_ 798 SOTAPrepResponseHVAC 0 "No response" 1 "Request in progress" 2 "Request accepted & actioned" 3 "Request denied" ;
VAL_ 302 CabinCleaningActivStat 0 "Inactive" 1 "Cycle Started" 2 "Cycle Completed" 3 "Cycle Aborted-Incomplete" ;
VAL_ 302 CabinCleaningStatHVAC 0 "No Error" 1 "User Stop Requested" 2 "Failure - Low Battery" 3 "Failure - Windows/Doors open/Vehicle not Secured" 4 "Failure - Cleaning Cycles Exhausted" 5 "Failure - System Faults" 6 "Failure - Power Mode Transition" 7 "Failure - Other Climate Feature Active/Requested" 8 "Failure - Crash Detected" 9 "Failure - External Failure" 10 "Failure - Critical Service Active" 11 "Failure - SOTA in Progress" ;
VAL_ 302 CabinCleanSchPreconReq 0 "Off" 1 "On" ;
VAL_ 302 PM25ExtAQIBand 0 "Undefined" 1 "Band 1" 2 "Band 2" 3 "Band 3" 4 "Band 4" 5 "Band 5" 6 "Band 6" 7 "Reserved" 8 "Reserved" 9 "Reserved" 10 "Reserved" 11 "Reserved" 12 "Reserved" 13 "Reserved" 14 "Reserved" 15 "Error" ;
VAL_ 302 PM25External 510 "Initialisation Value" 511 "Fault" ;
VAL_ 302 PM25IntAQIBand 0 "Undefined" 1 "Band 1" 2 "Band 2" 3 "Band 3" 4 "Band 4" 5 "Band 5" 6 "Band 6" 7 "Reserved" 8 "Reserved" 9 "Reserved" 10 "Reserved" 11 "Reserved" 12 "Reserved" 13 "Reserved" 14 "Reserved" 15 "Error" ;
VAL_ 302 PM25Internal 510 "Initialisation Value" 511 "Fault" ;
VAL_ 302 PNCabinCleanReq 0 "Partial NOT networking required" 1 "Partial networking required" ;
VAL_ 236 DCDC12vActualCurrent 1022 "Initialisation" 1023 "Failure" ;
VAL_ 236 DCDC12vActualSetpoint 254 "Initialisation" 255 "Failure" ;
VAL_ 236 DCDC12vActualVoltage 254 "Initialisation" 255 "Failure" ;
VAL_ 236 DCDC12vMaxCurrent 510 "Initialisation" 511 "Failure" ;
VAL_ 236 DCDC12VoltStatus 0 "12v in range" 1 "12v undervoltage" 2 "12v overvoltage" 3 "Not used" ;
VAL_ 345 DCDCCoolantLevel 0 "Coolant level OK" 1 "Coolant level Low" ;
VAL_ 345 DCDCCurrentHV 1022 "Initialisation" 1023 "Failure" ;
VAL_ 345 DCDCHighVoltageStatus 0 "HV in range" 1 "HV undervoltage" 2 "HV overvoltage" 3 "Not used" ;
VAL_ 345 DCDCHVActualSetpoint 1022 "Initialisation" 1023 "Failure" ;
VAL_ 345 DCDCInternalError 0 "No Internal Error" 1 "Internal Error Present" ;
VAL_ 345 DCDCOverVoltageDerate 0 "Not overvoltage derating" 1 "Overvoltage derating" ;
VAL_ 345 DCDCTemperature 254 "Initialisation" 255 "Failure" ;
VAL_ 345 DCDCTemperatureDerate 0 "Not temperature derating" 1 "Temperature derating" ;
VAL_ 345 DCDCUnderVoltageDerate 0 "Not undervoltage derating" 1 "Undervoltage derating" ;
VAL_ 700 IMCRangeOnRouteStatus 0 "Range-On-Route not calculated" 1 "Range-On-Route is calculated" ;
VAL_ 700 RouteStatusIGM 0 "System Start" 1 "Deviation from route" 2 "New programmed destination" 3 "Destination cancelled by driver" 4 "Destination reached" 5 "Position not matched" 6 "Active route" 7 "Unused" ;
VAL_ 700 RouteVersionIMC 0 "No Route" 1 "Route Version 1" 2 "Route Version 2" 3 "Route Version 3" 4 "Route Version 4" 5 "Route Version 5" 6 "Route Version 6" 7 "Route Version 7" ;
VAL_ 705 CreepModeRequest 0 "Creep OFF" 1 "Creep ON" ;
VAL_ 705 DataContractHLDF 0 "Allowed" 1 "Not Allowed" ;
VAL_ 705 EcoDrvCoachUserInput 0 "Disable" 1 "Enable" 2 "Enable only Eco Driving Coach" 3 "Unused" ;
VAL_ 705 FirstTimeChargeSetStat 0 "Not First Time Set-Up" 1 "First Time Set-Up" ;
VAL_ 705 HotspotRequestHLDF 0 "Hotspot OFF" 1 "Hotspot ON" ;
VAL_ 705 InfotainmentLanguage 0 "Undefined" 1 "Swedish" 2 "Danish" 3 "Finnish" 4 "English" 5 "German" 6 "Dutch" 7 "French" 8 "Italian" 9 "Spanish" 10 "Portuguese" 11 "English (US)" 12 "French (Canadian)" 13 "Japanese (Katakana)" 14 "Portuguese (Brazil)" 15 "English with number codes" 16 "Hungarian" 17 "Turkish" 18 "Russian" 19 "Polish" 20 "Czech" 21 "Norwegian" 22 "Latin Spanish" 23 "English (Australian)" 24 "Thai" 25 "Ford Asia Pacific English" 26 "Chinese (Simplified)" 27 "Taiwanese" 28 "Chinese (Traditional)" 29 "Flemish" 30 "Bulgarian" 31 "Estonian" 32 "Greek" 33 "Latvian" 34 "Lithuanian" 35 "Romanian" 36 "Slovakian" 37 "Slovene" 38 "Korean" 39 "Croatian" 40 "Malaysian" 41 "Arabic" 42 "Chinese_Mandarin" 43 "Chinese_Wu" 44 "Chinese_Cantonese" 63 "Error (default = English)" ;
VAL_ 705 LocationDataTCU 0 "GPS Data disabled (do not send)" 1 "GPS Data enabled (always send)" ;
VAL_ 705 PasswordRequestHLDF 0 "DefaultPassword" 1 "UserDefinedPassword" ;
VAL_ 705 PopupRequestHLDF 0 "NO Popup" 1 "Popup_1" 2 "Popup_2" 3 "Popup_3" ;
VAL_ 705 RoamingHLDF 0 "Enabled" 1 "Enabled Once" 2 "Disabled" 3 "reserved" ;
VAL_ 705 SOTAPrepResponseIGM 0 "No response" 1 "Request in progress" 2 "Request accepted & actioned" 3 "Request denied" ;
VAL_ 433 ChargDataWakeUpReq 0 "0 = Does Not Require Wake Up" 1 "Requires Wake Up" ;
VAL_ 433 ChargeEnRouteChargeNow 0 "Disable Charge Now Override for this charge only" 1 "Enable Charge Now Override for this charge only" ;
VAL_ 433 ChargeNowRequest 0 "Don't Charge Now" 1 "Charge Now" ;
VAL_ 433 ChargeNowRequestExt 0 "Default / Resume Charging" 1 "Force Charge Now ON" 2 "Force Charge Now OFF" 3 "Unused" ;
VAL_ 433 TimedChrgReq 0 "Default" 1 "Force Timed Charging" ;
VAL_ 434 ChrgControlCmdV1G 0 "No request" 1 "Start request" 2 "Stop request" ;
VAL_ 434 ChrgV1GCXNStatus 0 "Not connected" 1 "Connected" ;
VAL_ 692 NextPresetDepTimeDate 31 "No value" ;
VAL_ 692 NextPresetDepTimeHour 24 "No value" ;
VAL_ 692 NextPresetDepTimeMins 60 "No Value" ;
VAL_ 692 NextPresetDepTimeMnth 12 "No value" ;
VAL_ 692 NextPresetDepTimeYear 255 "No Value" ;
VAL_ 693 ChgPreConNowReq 0 "No Request" 1 "Button Pressed to Activate" 2 "Button Pressed to Deactivate" ;
VAL_ 186 ABRCTAMode 0 "ON" 1 "OFF" ;
VAL_ 186 AdaptDriBeamEnableReq 0 "DISABLE" 1 "ENABLE" ;
VAL_ 186 AnimProjEnableReq 0 "Disabled" 1 "Enabled" ;
VAL_ 186 AnimProjPreviewReq 0 "No request" 1 "Preview Requested" ;
VAL_ 186 AppOpenWalkAwyCloseReq 0 "Disable Approach Open/Walk Away Close" 1 "Enable Approach Open/Walk Away Close" ;
VAL_ 186 ApproachUnlockOnOffReq 0 "Disable Approach Unlocking" 1 "Enable Approach Unlocking" ;
VAL_ 186 ARAMode 0 "Undefined" 1 "Disabled by the driver" 2 "On with ignition" 3 "Reserved" ;
VAL_ 186 AutoHighBeamEnableReq 0 "AHBC system disable by user" 1 "AHBC system enable by user" ;
VAL_ 186 AutoHighBeamSAEModeReq 0 "Normal sensitivity" 1 "SAE Mode sensitivity" 2 "Reserved - Low sensitivity" 3 "Reserved - High sensitivity" ;
VAL_ 186 AutoHoldEnable 0 "DISABLE" 1 "ENABLE" ;
VAL_ 186 BSMMode 0 "Undefined" 1 "Disabled by Driver" 2 "On with Ignition" 3 "Alert with Turn Signal" ;
VAL_ 186 ChargingModeChcToLatch 0 "Charge Now" 1 "Timed charging" ;
VAL_ 186 CloseAllApertureReqIVI 0 "No user input" 1 "Close All request" 2 "Stop All request" ;
VAL_ 186 DDOpenCloseSwPressIVI 0 "No user input" 1 "Drivers Door Open Request" 2 "Drivers Door Close Request" 3 "Drivers Door Stop Request" ;
VAL_ 186 DRDOpenCloseSwPressIVI 0 "No user input" 1 "Driver Rear Door Open Request" 2 "Driver Rear Door Close Request" 3 "Driver Rear Door Stop Request" ;
VAL_ 186 GestDrsOpnClosOnOffReq 0 "Disable Gesture Doors Open/Close" 1 "Enable  Gesture Doors Open/Close " ;
VAL_ 186 IMCHybridModeRequest 0 "No request" 1 "Mode 1 requested" 2 "Mode 2 requested" 3 "Mode 3 requested" 4 "Mode 4 requested" 5 "Reserved5" 6 "Reserved6" 7 "Reserved7" ;
VAL_ 186 OnDemandHoldEnable 0 "Disabled" 1 "Enabled" ;
VAL_ 186 PDOpenCloseSwPressIVI 0 "No user input" 1 "Passenger Front Door Open Request" 2 "Passenger Front Door Close Request" 3 "Passenger Front Door Stop Request" ;
VAL_ 186 PEOEnablementStatus 0 "on" 1 "off" ;
VAL_ 186 PRDOpenCloseSwPressIVI 0 "No user input" 1 "Passenger Rear Door Open Request" 2 "Passenger Rear Door Close Request" 3 "Passenger Rear Door Stop Request" ;
VAL_ 186 RCTAReq 0 "ON" 1 "OFF" ;
VAL_ 186 RPCCustInhibitReq 0 "Undefined" 1 "ON" 2 "OFF" 3 "Reserved" ;
VAL_ 186 SupMainBeamEnableReq 0 "Disabled" 1 "Enabled" ;
VAL_ 186 WalkAwayLockOnOffReq 0 "Disable Walk Away Locking" 1 "Enable Walk Away Locking" 2 "Unused" 3 "Unused" ;
VAL_ 497 ALAnimateReqIVI 0 "Off" 1 "On" ;
VAL_ 497 ALBrightnessReqIVI 0 "0%" 1 "10%" 2 "20%" 3 "30%" 4 "40%" 5 "50%" 6 "60%" 7 "70%" 8 "80%" 9 "90%" 10 "100%" ;
VAL_ 497 ALCustomL1ColReqIVI 0 "def" 1 "Color 1" 2 "Color 2" 3 "Color 3" 4 "Color 4" 5 "Color 5" 6 "Color 6" 7 "Color 7" 8 "Color 8" 9 "Color 9" 10 "Color 10" 11 "Color 11" 12 "Color 12" 13 "Color 13" 14 "Color 14" 15 "Color 15" 16 "Color 16" 17 "Color 17" 18 "Color 18" 19 "Color 19" 20 "Color 20" 21 "Color 21" 22 "Color 22" 23 "Color 23" 24 "Color 24" 25 "Color 25" 26 "Color 26" 27 "Color 27" 28 "Color 28" 29 "Color 29" 30 "Color 30" ;
VAL_ 497 ALCustomL1IntReqIVI 0 "0%" 1 "25%" 2 "50%" 3 "75%" 4 "100%" ;
VAL_ 497 ALCustomL2ColReqIVI 0 "def" 1 "Color 1" 2 "Color 2" 3 "Color 3" 4 "Color 4" 5 "Color 5" 6 "Color 6" 7 "Color 7" 8 "Color 8" 9 "Color 9" 10 "Color 10" 11 "Color 11" 12 "Color 12" 13 "Color 13" 14 "Color 14" 15 "Color 15" 16 "Color 16" 17 "Color 17" 18 "Color 18" 19 "Color 19" 20 "Color 20" 21 "Color 21" 22 "Color 22" 23 "Color 23" 24 "Color 24" 25 "Color 25" 26 "Color 26" 27 "Color 27" 28 "Color 28" 29 "Color 29" 30 "Color 30" ;
VAL_ 497 ALCustomL2IntReqIVI 0 "0%" 1 "25%" 2 "50%" 3 "75%" 4 "100%" ;
VAL_ 497 ALCustomL3ColReqIVI 0 "def" 1 "Color 1" 2 "Color 2" 3 "Color 3" 4 "Color 4" 5 "Color 5" 6 "Color 6" 7 "Color 7" 8 "Color 8" 9 "Color 9" 10 "Color 10" 11 "Color 11" 12 "Color 12" 13 "Color 13" 14 "Color 14" 15 "Color 15" 16 "Color 16" 17 "Color 17" 18 "Color 18" 19 "Color 19" 20 "Color 20" 21 "Color 21" 22 "Color 22" 23 "Color 23" 24 "Color 24" 25 "Color 25" 26 "Color 26" 27 "Color 27" 28 "Color 28" 29 "Color 29" 30 "Color 30" ;
VAL_ 497 ALCustomL3IntReqIVI 0 "0%" 1 "25%" 2 "50%" 3 "75%" 4 "100%" ;
VAL_ 497 ALCustomL4ColReqIVI 0 "def" 1 "Color 1" 2 "Color 2" 3 "Color 3" 4 "Color 4" 5 "Color 5" 6 "Color 6" 7 "Color 7" 8 "Color 8" 9 "Color 9" 10 "Color 10" 11 "Color 11" 12 "Color 12" 13 "Color 13" 14 "Color 14" 15 "Color 15" 16 "Color 16" 17 "Color 17" 18 "Color 18" 19 "Color 19" 20 "Color 20" 21 "Color 21" 22 "Color 22" 23 "Color 23" 24 "Color 24" 25 "Color 25" 26 "Color 26" 27 "Color 27" 28 "Color 28" 29 "Color 29" 30 "Color 30" ;
VAL_ 497 ALCustomL4IntReqIVI 0 "0%" 1 "25%" 2 "50%" 3 "75%" 4 "100%" ;
VAL_ 497 ALDriverModeReqIVI 0 "Off" 1 "On" ;
VAL_ 497 ALOnOffReqIVI 0 "Off" 1 "Auto on" 2 "Always on" 3 "Not used" ;
VAL_ 497 ALPresetReqIVI 0 "None" 1 "Preset 1" 2 "Preset 2" 3 "Preset 3" 4 "Preset 4" 5 "Preset 5" 6 "Preset 6" 7 "Custom" ;
VAL_ 44 DrvlineDampStatusFx 0 "Not Active" 1 "Active" 2 "Limited Operation" 3 "Not Available" 4 "Failure" ;
VAL_ 44 InverterHVILStatusFx 0 "HVIL OK" 1 "HVIL not OK" 2 "HVIL not checked" ;
VAL_ 24 DrvlineDampStatusRx 0 "Not Active" 1 "Active" 2 "Limited Operation" 3 "Not Available" 4 "Failure" ;
VAL_ 24 InverterHVILStatusRx 0 "HVIL OK" 1 "HVIL Not OK" 2 "HVIL not checked" ;
VAL_ 375 EMTemperature 510 "Initialisation" 511 "Failure" ;
VAL_ 375 EPICMILRequest 0 "No MIL Request" 1 "Request MIL ON" 2 "Request MIL Flashing" 3 "Reserved/Not used" ;
VAL_ 375 InverterTemperature 254 "Initialisation" 255 "Failure" ;
VAL_ 375 InvTemperatureDerate 0 "Not Temperature derating" 1 "Temperature derating" ;
VAL_ 168 EMACOCMonitorStatus 0 "Ok" 1 "Not Ok" ;
VAL_ 168 EMOperatingModeExt 0 "Standby" 1 "Torque Mode" 2 "Reserved (Speed Mode)" 3 "Voltage Mode" 4 "Bus Test Mode" 5 "Not Capable" 6 "Reserved (Calibration Mode)" 7 "Reserved (Bus Discharge Mode)" 8 "Life Saver Mode" 9 "Pre-Load Mode" 10 "Unused10" 11 "Unused11" 12 "Unused12" 13 "Failure HV Not Allowed" 14 "Initialisation" 15 "Failure" ;
VAL_ 168 RapidDschrgDiagStatus 0 "Ok" 1 "Not Ok" ;
SIG_GROUP_ 1536 BCM_CCP_Tx 1 : CCP_BCM_Tx;
SIG_GROUP_ 1281 BCM_NM501HS 1 : NMmessageBCMHS;
SIG_GROUP_ 417 PowerModeGp 1 : PowerMode PowerModeAliveCounter PowerModeChecksum PowerModeQF RemoteEngStartDrivPres RemoteFunctionStatus RemoteStartStatusMS;
SIG_GROUP_ 225 BCM_ENCRYPT_LOCKING_2 1 : CentralLockStatus2;
SIG_GROUP_ 1672 BCM_UUDT1 1 : UUDTBCMResponse1;
SIG_GROUP_ 1673 BCM_UUDT2 1 : UUDTBCMResponse2;
SIG_GROUP_ 1674 BCM_UUDT3 1 : UUDTBCMResponse3;
SIG_GROUP_ 1675 BCM_UUDT4 1 : UUDTBCMResponse4;
SIG_GROUP_ 1314 BECM_NM522 1 : NMmessageBECM;
SIG_GROUP_ 136 HVBattChgExtGp 1 : HVBattChgContPwrLmt HVBattChgExtGpCounter HVBattChgExtGpCS HVBattChgPowerLimitExt HVBattChgVoltageLimit;
SIG_GROUP_ 140 HVBattDchExtGp 1 : HVBattDchContPwrLmt HVBattDchExtGpCounter HVBattDchExtGpCS HVBattDchPowerLimitExt HVBattDchVoltageLimit;
SIG_GROUP_ 152 HVBattStatusGp 1 : HVBattContactorStatus HVBattHVILStatus HVBattIsolationStatus HVBattOCMonitorStatus HVBattStatusCAT3 HVBattStatusCAT4Derate HVBattStatusCAT5BPOChg HVBattStatusCAT6DlyBPO HVBattStatusCAT7NowBPO HVBattStatusGpCounter HVBattStatusGpCS HVBattWeldCheckStatus;
SIG_GROUP_ 154 MVBattPwrGp 1 : MVBattCurrent MVBattPwrGpCounter MVBattPwrGpCS MVBattVoltage MVBattVoltageBus;
SIG_GROUP_ 263 MVBattPwrGp2 1 : MVBattCurrent2 MVBattPwrGp2AC MVBattPwrGp2CS MVBattVoltage2 MVBattVoltageBus2;
SIG_GROUP_ 1605 CCP_RES_HVAC 1 : CCPHVACToTester;
SIG_GROUP_ 209 DCDCOpModeMVGp 1 : DCDCCurrentMV DCDCOperatingModeExt2 DCDCOpModeMVGpCounter DCDCOpModeMVGpCS DCDCVoltageMV;
SIG_GROUP_ 1315 EPICD_NM523 1 : NMmessageEPICD;
SIG_GROUP_ 277 TR1 1 : AutoTRStatus CanclAutoTrProgReq RtnPrevProg TerrProgActv;
SIG_GROUP_ 936 CbnZnAirOffTempTgtGp 1 : CbnZn1AirOffTempTgt CbnZn2AirOffTempTgt CbnZn3AirOffTempTgt CbnZn4AirOffTempTgt CbnZn5AirOffTempTgt CbnZn6AirOffTempTgt;
SIG_GROUP_ 933 CabinZoneTempAvgGp 1 : CabinZone1TempAvg CabinZone2TempAvg CabinZone3TempAvg CabinZone4TempAvg CabinZone5TempAvg CabinZone6TempAvg;
SIG_GROUP_ 934 CabinZoneTempSetPointGp 1 : CabinZone1TempSetPoint CabinZone2TempSetPoint CabinZone3TempSetPoint CabinZone4TempSetPoint CabinZone5TempSetPoint CabinZone6TempSetPoint;
SIG_GROUP_ 535 ClimPredContKwGp 1 : ClimPredContKwCmfExt ClimPredContKwECOExt ClimPredContKwGMHExt;
SIG_GROUP_ 302 CabinCleanStatusGp 1 : CabinCleaningActivStat CabinCleaningStatHVAC CabinCleanSchPreconReq;
SIG_GROUP_ 302 HVAC_PM25Filtration 1 : PM25ExtAQIBand PM25External PM25IntAQIBand PM25Internal;
SIG_GROUP_ 168 EMOpModeExtGp 1 : EMACOCMonitorStatus EMOperatingModeExt EMOpModeExtGpCounter EMOpModeExtGpCS EMVoltageDCLinkExt RapidDschrgDiagStatus;
